VERSION "HNNBNNNYNNNNNNNNNNNNNNNNNNNNNNNNNNNNNNNNNN/4/%%%/4/'%**4NNN///"

NS_ :

BS_:

BU_: AWC BAP_Tester BMC_MLBevo BMS_MV BMS_NV CBC DCDC_800V_PAG DCDC_HV DCDC_HV_02 DCDC_IHEV FCU_MLBevo_FCEV Gateway Gateway_PAG Ladegeraet_2 Ladegeraet_Konzern LE1 LE2 LE_MLBevo Sub_Gateway TME

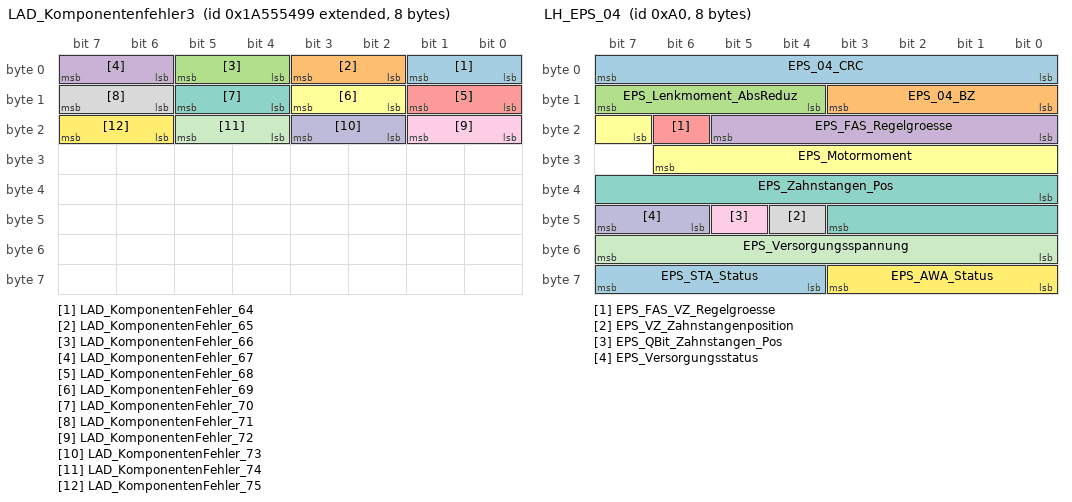
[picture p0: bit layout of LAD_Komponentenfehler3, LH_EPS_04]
BO_ 2589283481 LAD_Komponentenfehler3: 8 Ladegeraet_Konzern
 SG_ LAD_KomponentenFehler_64 : 0|2@1+ (1.0,0.0) [0.0|3] ""  BMC_MLBevo
 SG_ LAD_KomponentenFehler_65 : 2|2@1+ (1.0,0.0) [0.0|3] ""  BMC_MLBevo
 SG_ LAD_KomponentenFehler_66 : 4|2@1+ (1.0,0.0) [0.0|3] ""  BMC_MLBevo
 SG_ LAD_KomponentenFehler_67 : 6|2@1+ (1.0,0.0) [0.0|3] ""  BMC_MLBevo
 SG_ LAD_KomponentenFehler_68 : 8|2@1+ (1.0,0.0) [0.0|3] ""  BMC_MLBevo
 SG_ LAD_KomponentenFehler_69 : 10|2@1+ (1.0,0.0) [0.0|3] ""  BMC_MLBevo
 SG_ LAD_KomponentenFehler_70 : 12|2@1+ (1.0,0.0) [0.0|3] ""  BMC_MLBevo
 SG_ LAD_KomponentenFehler_71 : 14|2@1+ (1.0,0.0) [0.0|3] ""  BMC_MLBevo
 SG_ LAD_KomponentenFehler_72 : 16|2@1+ (1.0,0.0) [0.0|3] ""  BMC_MLBevo
 SG_ LAD_KomponentenFehler_73 : 18|2@1+ (1.0,0.0) [0.0|3] ""  BMC_MLBevo
 SG_ LAD_KomponentenFehler_74 : 20|2@1+ (1.0,0.0) [0.0|3] ""  BMC_MLBevo
 SG_ LAD_KomponentenFehler_75 : 22|2@1+ (1.0,0.0) [0.0|3] ""  BMC_MLBevo

BO_ 160 LH_EPS_04: 8 Gateway
 SG_ EPS_04_CRC : 0|8@1+ (1,0) [0|255] ""  Vector__XXX
 SG_ EPS_04_BZ : 8|4@1+ (1,0) [0|15] ""  Vector__XXX
 SG_ EPS_Lenkmoment_AbsReduz : 12|4@1+ (0.62,0.61) [0.61|8.05] "Unit_NewtoMeter"  Vector__XXX
 SG_ EPS_FAS_Regelgroesse : 16|6@1+ (2,0) [0|100] "Unit_PerCent"  Vector__XXX
 SG_ EPS_FAS_VZ_Regelgroesse : 22|1@1+ (1.0,0.0) [0.0|1] ""  Vector__XXX
 SG_ EPS_Motormoment : 23|8@1+ (0.2,-16.2) [-16.0|16.0] "Unit_NewtoMeter"  Vector__XXX
 SG_ EPS_Zahnstangen_Pos : 32|12@1+ (0.02,0) [0.00|81.86] "Unit_MilliMeter"  Vector__XXX
 SG_ EPS_VZ_Zahnstangenposition : 44|1@1+ (1.0,0.0) [0.0|1] ""  Vector__XXX
 SG_ EPS_QBit_Zahnstangen_Pos : 45|1@1+ (1.0,0.0) [0.0|1] ""  Vector__XXX
 SG_ EPS_Versorgungsstatus : 46|2@1+ (1.0,0.0) [0.0|3] ""  Vector__XXX
 SG_ EPS_Versorgungsspannung : 48|8@1+ (0.05,5.05) [5.05|17.70] "Unit_Volt"  Vector__XXX
 SG_ EPS_AWA_Status : 56|4@1+ (1.0,0.0) [0.0|15] ""  Vector__XXX
 SG_ EPS_STA_Status : 60|4@1+ (1.0,0.0) [0.0|15] ""  Vector__XXX

BO_ 1600 Motor_07: 8 Gateway
 SG_ MO_QBit_Ansaugluft_Temp : 0|1@1+ (1.0,0.0) [0.0|1] ""  Vector__XXX
 SG_ MO_QBit_Oel_Temp : 1|1@1+ (1.0,0.0) [0.0|1] ""  Vector__XXX
 SG_ MO_QBit_Kuehlmittel_Temp : 2|1@1+ (1.0,0.0) [0.0|1] ""  Vector__XXX
 SG_ MO_KL15_Abschaltempfehlung : 3|1@1+ (1.0,0.0) [0.0|1] ""  Vector__XXX
 SG_ MO_HYB_Fehler_HV_Netz : 4|1@1+ (1.0,0.0) [0.0|1] ""  Vector__XXX
 SG_ MO_aktives_Getriebeheizen : 5|1@1+ (1.0,0.0) [0.0|1] ""  Vector__XXX
 SG_ MO_Absperrventil_oeffnen : 6|2@1+ (1.0,0.0) [0.0|3] ""  TME
 SG_ MO_Ansaugluft_Temp : 8|8@1+ (0.75,-48) [-48.00|141.75] "Unit_DegreCelsi"  TME
 SG_ MO_Oel_Temp : 16|8@1+ (1,-60) [-60|192] "Unit_DegreCelsi"  TME
 SG_ MO_Kuehlmittel_Temp : 24|8@1+ (0.75,-48) [-48.00|141.75] "Unit_DegreCelsi"  TME
 SG_ MO_Hoeheninfo : 32|8@1+ (0.00781,0) [0.00000|1.98374] ""  TME
 SG_ MO_Kennfeldk : 40|1@1+ (1.0,0.0) [0.0|1] ""  TME
 SG_ MO_Versionsinfo_02 : 41|5@1+ (1.0,0.0) [0.0|31] ""  Vector__XXX
 SG_ MO_QBit_Hoeheninfo : 46|1@1+ (1.0,0.0) [0.0|1] ""  Vector__XXX
 SG_ MO_Getriebe_kuehlen : 47|1@1+ (1.0,0.0) [0.0|1] ""  Vector__XXX
 SG_ MO_Mom_Traegheit_02 : 48|5@1+ (0.01,0) [0.00|0.31] "Unit_KiloGramMeterSquar"  Vector__XXX
 SG_ MO_Heizungspumpenansteuerung : 53|4@1+ (10,0) [0|100] "Unit_PerCent"  TME
 SG_ MO_SpannungsAnf : 57|1@1+ (1.0,0.0) [0.0|1] ""  Vector__XXX
 SG_ MO_Nachlaufzeit_Heizungspumpe : 58|6@1+ (15,0) [0|945] "Unit_Secon"  TME

BO_ 1607 Motor_09: 8 Gateway
 SG_ MO_ITM_Kuehlmittel_Temp : 0|8@1+ (0.75,-48) [-45.75|143.25] "Unit_DegreCelsi"  TME
 SG_ MO_E85_Sensor : 8|4@1+ (10,0) [0|100] "Unit_PerCent"  Vector__XXX
 SG_ SCR_Anz_Motorstarts : 12|4@1+ (1.0,0.0) [0.0|15] ""  Vector__XXX
 SG_ SCR_Reichweite : 16|15@1+ (1,0) [0|32766] "Unit_KiloMeter"  Vector__XXX
 SG_ MO_Ethanol_Spuelhinweis : 31|1@1+ (1.0,0.0) [0.0|1] ""  Vector__XXX
 SG_ SCR_Warnstufe_1 : 32|1@1+ (1.0,0.0) [0.0|1] ""  Vector__XXX
 SG_ SCR_Warnstufe_2 : 33|1@1+ (1.0,0.0) [0.0|1] ""  Vector__XXX
 SG_ SCR_Text : 34|3@1+ (1.0,0.0) [0.0|7] ""  Vector__XXX
 SG_ SCR_Akustik : 37|2@1+ (1.0,0.0) [0.0|3] ""  Vector__XXX
 SG_ SCR_verbaut : 39|1@1+ (1.0,0.0) [0.0|1] ""  Vector__XXX
 SG_ MO_Kraftstofffilter_Wasser : 40|1@1+ (1.0,0.0) [0.0|1] ""  Vector__XXX
 SG_ SCR_Systemfehler : 41|1@1+ (1.0,0.0) [0.0|1] ""  Vector__XXX
 SG_ SCR_Inducement_Strategie : 42|2@1+ (1.0,0.0) [0.0|3] ""  Vector__XXX
 SG_ MO_CO2_Faktor : 44|12@1+ (1,0) [1|4094] "Unit_GramPerLiter"  Vector__XXX
 SG_ MO_MKB_MUX M  : 56|2@1+ (1.0,0.0) [0.0|3] ""  Vector__XXX
 SG_ MO_MKB_01 m0  : 59|5@1+ (1.0,0.0) [0.0|31] ""  Vector__XXX
 SG_ MO_MKB_02 m1  : 59|5@1+ (1.0,0.0) [0.0|31] ""  Vector__XXX
 SG_ MO_MKB_03 m2  : 59|5@1+ (1.0,0.0) [0.0|31] ""  Vector__XXX
 SG_ MO_MKB_04 m3  : 59|5@1+ (1.0,0.0) [0.0|31] ""  Vector__XXX

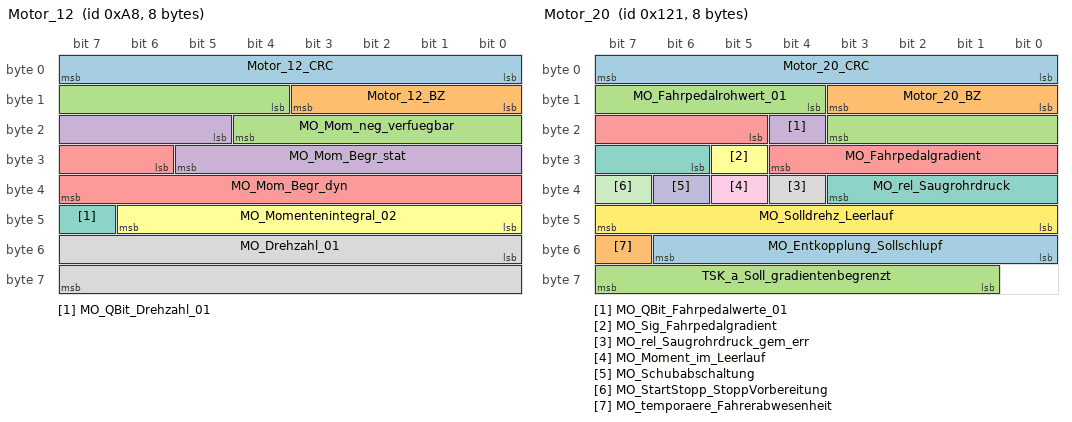
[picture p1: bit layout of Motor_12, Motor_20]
BO_ 168 Motor_12: 8 Gateway
 SG_ Motor_12_CRC : 0|8@1+ (1,0) [0|255] ""  Sub_Gateway
 SG_ Motor_12_BZ : 8|4@1+ (1,0) [0|15] ""  Sub_Gateway
 SG_ MO_Mom_neg_verfuegbar : 12|9@1+ (1,-509) [-509|0] ""  Sub_Gateway
 SG_ MO_Mom_Begr_stat : 21|9@1+ (1,0) [0|509] ""  Sub_Gateway
 SG_ MO_Mom_Begr_dyn : 30|10@1+ (1,-509) [-509|509] ""  Sub_Gateway
 SG_ MO_Momentenintegral_02 : 40|7@1+ (1,0) [0|100] "Unit_PerCent"  Sub_Gateway
 SG_ MO_QBit_Drehzahl_01 : 47|1@1+ (1.0,0.0) [0.0|1] ""  Sub_Gateway
 SG_ MO_Drehzahl_01 : 48|16@1+ (0.25,0) [0.00|16383.00] "Unit_MinutInver"  BMC_MLBevo,CBC,DCDC_800V_PAG,DCDC_HV,Ladegeraet_2,Ladegeraet_Konzern,Sub_Gateway,TME

BO_ 958 Motor_14: 8 Gateway
 SG_ Motor_14_CRC : 0|8@1+ (1,0) [0|255] ""  FCU_MLBevo_FCEV,Sub_Gateway
 SG_ Motor_14_BZ : 8|4@1+ (1,0) [0|15] ""  FCU_MLBevo_FCEV,Sub_Gateway
 SG_ MO_StartStopp_Status : 12|2@1+ (1.0,0.0) [0.0|3] ""  Sub_Gateway,TME
 SG_ MO_StartStopp_Wiederstart : 14|1@1+ (1.0,0.0) [0.0|1] ""  BMS_NV,Sub_Gateway,TME
 SG_ MO_StartStopp_Motorstopp : 15|1@1+ (1.0,0.0) [0.0|1] ""  BMS_NV,Sub_Gateway,TME
 SG_ MO_Freig_Reku : 16|2@1+ (1.0,0.0) [0.0|3] ""  Sub_Gateway
 SG_ MO_Kl_75 : 18|1@1+ (1.0,0.0) [0.0|1] ""  Sub_Gateway,TME
 SG_ MO_Kl_50 : 19|1@1+ (1.0,0.0) [0.0|1] ""  DCDC_IHEV,Ladegeraet_Konzern,Sub_Gateway
 SG_ MO_Gangposition : 20|4@1+ (1.0,0.0) [0.0|15] ""  Sub_Gateway,TME
 SG_ MO_StartStopp_Fahrerwunsch : 24|2@1+ (1.0,0.0) [0.0|3] ""  Sub_Gateway,TME
 SG_ MO_HYB_Fahrbereitschaft : 26|1@1+ (1.0,0.0) [0.0|1] ""  BMS_NV,FCU_MLBevo_FCEV,Ladegeraet_Konzern,Sub_Gateway,TME
 SG_ MO_Ext_E_Fahrt_aktiv : 27|1@1+ (1.0,0.0) [0.0|1] ""  Sub_Gateway,TME
 SG_ MO_Fahrer_bremst : 28|1@1+ (1.0,0.0) [0.0|1] ""  Sub_Gateway
 SG_ MO_QBit_Fahrer_bremst : 29|1@1+ (1.0,0.0) [0.0|1] ""  Sub_Gateway
 SG_ MO_BLS : 30|1@1+ (1.0,0.0) [0.0|1] ""  Sub_Gateway
 SG_ MO_Konsistenz_Bremsped : 31|1@1+ (1.0,0.0) [0.0|1] ""  Sub_Gateway
 SG_ MO_KomFehler_ESP : 32|1@1+ (1.0,0.0) [0.0|1] ""  Sub_Gateway
 SG_ MO_Klima_Eingr : 33|2@1+ (1.0,0.0) [0.0|3] ""  Sub_Gateway,TME
 SG_ MO_Aussp_Anlass : 35|1@1+ (1.0,0.0) [0.0|1] ""  Sub_Gateway
 SG_ MO_Freig_Anlass : 36|1@1+ (1.0,0.0) [0.0|1] ""  Sub_Gateway
 SG_ MO_Kuppl_schalter : 37|1@1+ (1.0,0.0) [0.0|1] ""  Sub_Gateway
 SG_ MO_Interlock : 38|1@1+ (1.0,0.0) [0.0|1] ""  Sub_Gateway
 SG_ MO_Motor_laeuft : 39|1@1+ (1.0,0.0) [0.0|1] ""  Sub_Gateway,TME
 SG_ MO_Kickdown : 40|1@1+ (1.0,0.0) [0.0|1] ""  Sub_Gateway,TME
 SG_ MO_QBit_KL_75 : 41|1@1+ (1.0,0.0) [0.0|1] ""  Sub_Gateway
 SG_ MO_EKlKomLeiRed : 42|2@1+ (1.0,0.0) [0.0|3] ""  Sub_Gateway
 SG_ MO_Handshake_STH : 44|1@1+ (1.0,0.0) [0.0|1] ""  Sub_Gateway
 SG_ MO_BKV_Unterdruckwarnung : 45|1@1+ (1.0,0.0) [0.0|1] ""  Sub_Gateway
 SG_ MO_Freigabe_Segeln : 46|1@1+ (1.0,0.0) [0.0|1] ""  Sub_Gateway
 SG_ MO_PTC_Status : 47|3@1+ (1.0,0.0) [0.0|7] ""  Sub_Gateway
 SG_ MO_QBit_Gangposition : 50|1@1+ (1.0,0.0) [0.0|1] ""  Sub_Gateway
 SG_ MO_Signalquelle_Gangposition : 51|1@1+ (1.0,0.0) [0.0|1] ""  Sub_Gateway
 SG_ MO_Remotestart_Betrieb : 52|1@1+ (1.0,0.0) [0.0|1] ""  Sub_Gateway
 SG_ MO_Remotestart_moeglich : 53|1@1+ (1.0,0.0) [0.0|1] ""  Sub_Gateway
 SG_ MO_Text_Geschw_red : 54|1@1+ (1.0,0.0) [0.0|1] ""  Sub_Gateway
 SG_ MO_FMAus_aktiv : 55|1@1+ (1.0,0.0) [0.0|1] ""  BMS_NV,Sub_Gateway
 SG_ MO_FMAus_Startvariante : 56|2@1+ (1.0,0.0) [0.0|3] ""  Sub_Gateway
 SG_ MO_BMS_NV_Anf_stuetzen : 58|1@1+ (1.0,0.0) [0.0|1] ""  Sub_Gateway
 SG_ MO_Zylinderabschaltung : 59|2@1+ (1.0,0.0) [0.0|3] ""  Sub_Gateway
 SG_ MO_HYB_VM_aktiv : 61|1@1+ (1.0,0.0) [0.0|1] ""  Sub_Gateway
 SG_ MO_StartVorauss_erfuellt : 62|2@1+ (1.0,0.0) [0.0|3] ""  Ladegeraet_Konzern,Sub_Gateway

BO_ 812 Motor_17: 8 Gateway
 SG_ MO_Sperrung_FahrPr_BZS : 0|8@1+ (1.0,0.0) [0.0|255] ""  Vector__XXX
 SG_ MO_Rampenzeit_Generator_Anf : 8|4@1+ (1.0,0.0) [0.0|15] ""  Vector__XXX
 SG_ MO_Prio_MAX_Wunschdrehzahl : 12|1@1+ (1.0,0.0) [0.0|1] ""  Vector__XXX
 SG_ MO_Prio_MIN_Wunschdrehzahl : 13|1@1+ (1.0,0.0) [0.0|1] ""  Vector__XXX
 SG_ MO_Luftpfad_aktiv : 14|1@1+ (1.0,0.0) [0.0|1] ""  Vector__XXX
 SG_ MO_v_Begrenz_Aktivierbar : 15|1@1+ (1.0,0.0) [0.0|1] ""  Vector__XXX
 SG_ MO_Drehzahlbeeinflussung : 16|8@1+ (0.39,0) [0.00|99.45] "Unit_PerCent"  Vector__XXX
 SG_ MO_MIN_Wunschdrehzahl : 24|8@1+ (25,0) [0|6350] "Unit_MinutInver"  Vector__XXX
 SG_ MO_MAX_Wunschdrehzahl : 32|9@1+ (25,0) [0|12750] "Unit_MinutInver"  Vector__XXX
 SG_ MO_Charisma_FahrPr : 41|4@1+ (1.0,0.0) [0.0|15] ""  TME
 SG_ MO_Charisma_Status : 45|2@1+ (1.0,0.0) [0.0|3] ""  Vector__XXX
 SG_ MO_StSt_Charisma_FahrPr : 47|4@1+ (1.0,0.0) [0.0|15] ""  Vector__XXX
 SG_ MO_StSt_Charisma_Status : 51|2@1+ (1.0,0.0) [0.0|3] ""  Vector__XXX
 SG_ MO_BZS_Charisma_FahrPr : 53|4@1+ (1.0,0.0) [0.0|15] ""  TME
 SG_ MO_BZS_Charisma_Status : 57|2@1+ (1.0,0.0) [0.0|3] ""  Vector__XXX
 SG_ MO_NGS_Position : 59|1@1+ (1.0,0.0) [0.0|1] ""  Vector__XXX
 SG_ MO_NGS_Status : 60|2@1+ (1.0,0.0) [0.0|3] ""  Vector__XXX
 SG_ MO_v_Begrenzung_Niveau : 62|2@1+ (1.0,0.0) [0.0|3] ""  Vector__XXX

BO_ 1648 Motor_18: 8 Gateway
 SG_ MO_max_Ladedruck : 0|6@1+ (0.1,0) [0.0|6.3] "Unit_Bar"  Sub_Gateway
 SG_ MO_ANC_Kennfeld_Anf : 6|2@1+ (1.0,0.0) [0.0|3] ""  Sub_Gateway
 SG_ MO_Bremslicht_Reku : 8|1@1+ (1.0,0.0) [0.0|1] ""  Sub_Gateway
 SG_ MO_StartStopp_PopUp : 9|2@1+ (1.0,0.0) [0.0|3] ""  Sub_Gateway
 SG_ MO1_Sperr_Info_WFS : 11|1@1+ (1.0,0.0) [0.0|1] ""  Sub_Gateway
 SG_ MO1_Freigabe_Info_WFS : 12|1@1+ (1.0,0.0) [0.0|1] ""  Sub_Gateway
 SG_ MO_EPCL : 13|3@1+ (1.0,0.0) [0.0|7] ""  Sub_Gateway
 SG_ MO_Zylabsch_Texte_02 : 16|4@1+ (1.0,0.0) [0.0|15] ""  Sub_Gateway
 SG_ MO_Fahrzeugtyp : 20|3@1+ (1.0,0.0) [0.0|7] ""  BMS_NV,Sub_Gateway
 SG_ MO_NMAX_Schaltanzeige : 23|9@1+ (25,0) [0|12775] "Unit_MinutInver"  Sub_Gateway
 SG_ MO_Abstellzeit : 32|8@1+ (8,0) [0|2024] "Unit_Minut"  BMS_MV,BMS_NV,Sub_Gateway,TME
 SG_ MO_Abstellzeit_Status : 40|2@1+ (1.0,0.0) [0.0|3] ""  BMS_MV,BMS_NV,Sub_Gateway,TME
 SG_ MO1_Freigabe_Verfallsinfo_WFS : 42|1@1+ (1.0,0.0) [0.0|1] ""  Sub_Gateway
 SG_ MO_Hybrid_StartStopp_LED : 43|2@1+ (1.0,0.0) [0.0|3] ""  Sub_Gateway
 SG_ MO_Fehler_Zylabsch : 45|2@1+ (1.0,0.0) [0.0|3] ""  Sub_Gateway
 SG_ MO_Anzahl_Abgesch_Zyl : 47|3@1+ (1.0,0.0) [0.0|7] ""  Sub_Gateway
 SG_ MO_Zylabsch_Texte : 50|2@1+ (1.0,0.0) [0.0|3] ""  Sub_Gateway
 SG_ MO_Ethanol_BS_Texte : 52|3@1+ (1.0,0.0) [0.0|7] ""  Sub_Gateway
 SG_ MO_Drehzahl_Warnung : 55|1@1+ (1.0,0.0) [0.0|1] ""  Sub_Gateway
 SG_ MO_obere_Drehzahlgrenze : 56|8@1+ (50,0) [50|12750] "Unit_MinutInver"  Sub_Gateway

BO_ 289 Motor_20: 8 Gateway
 SG_ Motor_20_CRC : 0|8@1+ (1,0) [0|255] ""  Sub_Gateway
 SG_ Motor_20_BZ : 8|4@1+ (1,0) [0|15] ""  Sub_Gateway
 SG_ MO_Fahrpedalrohwert_01 : 12|8@1+ (0.4,0) [0.0|101.6] "Unit_PerCent"  Sub_Gateway
 SG_ MO_QBit_Fahrpedalwerte_01 : 20|1@1+ (1.0,0.0) [0.0|1] ""  Sub_Gateway
 SG_ MO_Fahrpedalgradient : 21|8@1+ (25,0) [0|6350] "Unit_PerCentPerSecon"  Sub_Gateway
 SG_ MO_Sig_Fahrpedalgradient : 29|1@1+ (1.0,0.0) [0.0|1] ""  Sub_Gateway
 SG_ MO_rel_Saugrohrdruck : 30|6@1+ (18,0) [0|1116] "Unit_MilliBar"  Sub_Gateway
 SG_ MO_rel_Saugrohrdruck_gem_err : 36|1@1+ (1.0,0.0) [0.0|1] ""  Sub_Gateway
 SG_ MO_Moment_im_Leerlauf : 37|1@1+ (1.0,0.0) [0.0|1] ""  Sub_Gateway
 SG_ MO_Schubabschaltung : 38|1@1+ (1.0,0.0) [0.0|1] ""  Sub_Gateway
 SG_ MO_StartStopp_StoppVorbereitung : 39|1@1+ (1.0,0.0) [0.0|1] ""  Sub_Gateway
 SG_ MO_Solldrehz_Leerlauf : 40|8@1+ (10,0) [0|2540] "Unit_MinutInver"  Sub_Gateway
 SG_ MO_Entkopplung_Sollschlupf : 48|7@1+ (20,0) [0|2480] "Unit_MinutInver"  Sub_Gateway
 SG_ MO_temporaere_Fahrerabwesenheit : 55|1@1+ (1.0,0.0) [0.0|1] ""  Sub_Gateway
 SG_ TSK_a_Soll_gradientenbegrenzt : 57|7@1+ (0.1,-7.2) [-7.2|5.4] "Unit_MeterPerSeconSquar"  Sub_Gateway

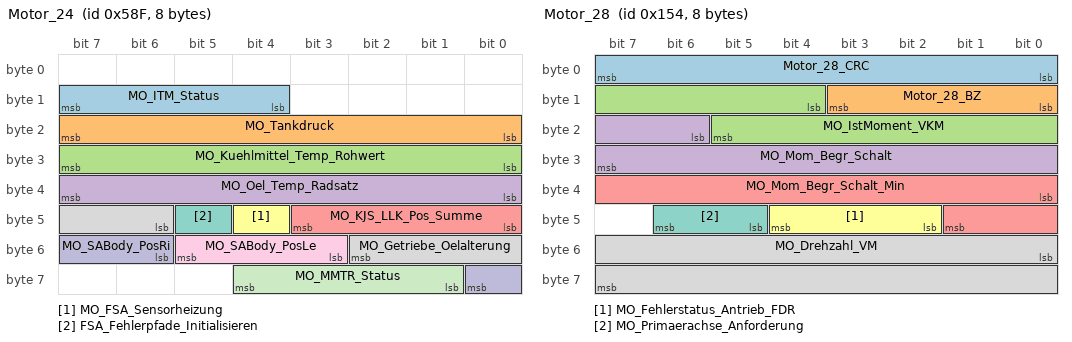
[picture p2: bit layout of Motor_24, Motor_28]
BO_ 1423 Motor_24: 8 Gateway
 SG_ MO_ITM_Status : 12|4@1+ (1.0,0.0) [0.0|15] ""  TME
 SG_ MO_Tankdruck : 16|8@1+ (2,-250) [-250|256] "Unit_MilliBar"  Vector__XXX
 SG_ MO_Kuehlmittel_Temp_Rohwert : 24|8@1+ (0.75,-48) [-48.00|141.75] "Unit_DegreCelsi"  TME
 SG_ MO_Oel_Temp_Radsatz : 32|8@1+ (1,-60) [-60|193] "Unit_DegreCelsi"  Vector__XXX
 SG_ MO_KJS_LLK_Pos_Summe : 40|4@1+ (10,0) [0|100] "Unit_PerCent"  Vector__XXX
 SG_ MO_FSA_Sensorheizung : 44|1@1+ (1.0,0.0) [0.0|1] ""  Vector__XXX
 SG_ FSA_Fehlerpfade_Initialisieren : 45|1@1+ (1.0,0.0) [0.0|1] ""  Vector__XXX
 SG_ MO_Getriebe_Oelalterung : 46|5@1+ (5,0) [0|100] "Unit_PerCent"  Vector__XXX
 SG_ MO_SABody_PosLe : 51|3@1+ (20,-20) [0|100] "Unit_PerCent"  Vector__XXX
 SG_ MO_SABody_PosRi : 54|3@1+ (20,-20) [0|100] "Unit_PerCent"  Vector__XXX
 SG_ MO_MMTR_Status : 57|4@1+ (1.0,0.0) [0.0|15] ""  LE1,LE2

BO_ 967 Motor_26: 8 Gateway
 SG_ MO_Kuehlerluefter_MUX M  : 0|1@1+ (1.0,0.0) [0.0|1] ""  TME
 SG_ MO_Kuehlerluefter_1 m0  : 1|7@1+ (1,0) [0|100] "Unit_PerCent"  TME
 SG_ MO_Kuehlerluefter_2 m1  : 1|7@1+ (1,0) [0|100] "Unit_PerCent"  TME
 SG_ MO_EFLEX_Lampe : 8|2@1+ (1.0,0.0) [0.0|3] ""  Vector__XXX
 SG_ MO_KJS_nicht_bereit : 10|1@1+ (1.0,0.0) [0.0|1] ""  Vector__XXX
 SG_ MO_ITM_Warnung_Pumpe : 11|1@1+ (1.0,0.0) [0.0|1] ""  Vector__XXX
 SG_ WIV_Anzeige_aktiv : 12|1@1+ (1.0,0.0) [0.0|1] ""  Vector__XXX
 SG_ WIV_Oelmin_Warn : 13|1@1+ (1.0,0.0) [0.0|1] ""  Vector__XXX
 SG_ WIV_Sensorfehler : 14|1@1+ (1.0,0.0) [0.0|1] ""  Vector__XXX
 SG_ WIV_Schieflage : 15|1@1+ (1.0,0.0) [0.0|1] ""  Vector__XXX
 SG_ WIV_Oelstand : 16|4@1+ (12.5,0) [0.0|100.0] "Unit_PerCent"  Vector__XXX
 SG_ MO_Zustand_HWP : 20|2@1+ (1.0,0.0) [0.0|3] ""  TME
 SG_ OLEV_Systemstoerung : 22|1@1+ (1.0,0.0) [0.0|1] ""  Vector__XXX
 SG_ MO_Oelwarnung_max : 23|1@1+ (1.0,0.0) [0.0|1] ""  Vector__XXX
 SG_ WIV_Oelsystem_aktiv : 24|1@1+ (1.0,0.0) [0.0|1] ""  Vector__XXX
 SG_ WIV_nicht_betriebswarm : 25|1@1+ (1.0,0.0) [0.0|1] ""  Vector__XXX
 SG_ WIV_Ueberfuell_Warn : 26|1@1+ (1.0,0.0) [0.0|1] ""  Vector__XXX
 SG_ WIV_laufender_Motor : 27|1@1+ (1.0,0.0) [0.0|1] ""  Vector__XXX
 SG_ MO_E_Warnungen : 28|4@1+ (1.0,0.0) [0.0|15] ""  Vector__XXX
 SG_ MO_Text_Motorstart : 32|4@1+ (1.0,0.0) [0.0|15] ""  Vector__XXX
 SG_ MO_E_Texte : 36|4@1+ (1.0,0.0) [0.0|15] ""  Vector__XXX
 SG_ WIV_Oeldyn_avl : 40|1@1+ (1.0,0.0) [0.0|1] ""  Vector__XXX
 SG_ MO_Text_Partikelfil_Reg : 41|1@1+ (1,0) [0|1] ""  Vector__XXX
 SG_ OLEV_Oelstand_nicht_vorhanden : 42|1@1+ (1.0,0.0) [0.0|1] ""  Vector__XXX
 SG_ WIV_Oelmenge : 43|5@1+ (125,0) [0|3875] "Unit_MilliLiter"  Vector__XXX
 SG_ MO_Systemlampe : 48|1@1+ (1.0,0.0) [0.0|1] ""  Vector__XXX
 SG_ MO_OBD2_Lampe : 49|1@1+ (1.0,0.0) [0.0|1] ""  Vector__XXX
 SG_ MO_Heissleuchte : 50|1@1+ (1.0,0.0) [0.0|1] ""  TME
 SG_ MO_Partikel_Lampe : 51|1@1+ (1.0,0.0) [0.0|1] ""  Vector__XXX
 SG_ MO_RedFahrleistung_Lampe : 52|1@1+ (1.0,0.0) [0.0|1] ""  Vector__XXX
 SG_ WIV_Oelstand_nicht_vorhanden : 53|1@1+ (1.0,0.0) [0.0|1] ""  Vector__XXX
 SG_ WIV_nachfuellanzeige_ein : 54|1@1+ (1.0,0.0) [0.0|1] ""  Vector__XXX
 SG_ WIV_Ueberfuell_deaktiv : 55|1@1+ (1.0,0.0) [0.0|1] ""  Vector__XXX
 SG_ WIV_Unterfuell_Warn : 56|1@1+ (1.0,0.0) [0.0|1] ""  Vector__XXX
 SG_ MO_Tankdeckel_Lampe : 57|1@1+ (1.0,0.0) [0.0|1] ""  Vector__XXX
 SG_ MO_Text_Tankdeckelwarn : 58|1@1+ (1.0,0.0) [0.0|1] ""  Vector__XXX
 SG_ MO_Vorglueh_Lampe : 59|1@1+ (1.0,0.0) [0.0|1] ""  Vector__XXX
 SG_ WIV_Oeldr_Warn_Motor : 60|1@1+ (1.0,0.0) [0.0|1] ""  Vector__XXX
 SG_ MO_E_Mode : 61|3@1+ (1.0,0.0) [0.0|7] ""  Vector__XXX

BO_ 340 Motor_28: 8 Gateway
 SG_ Motor_28_CRC : 0|8@1+ (1,0) [0|255] ""  Sub_Gateway
 SG_ Motor_28_BZ : 8|4@1+ (1,0) [0|15] ""  Sub_Gateway
 SG_ MO_IstMoment_VKM : 12|10@1+ (1,-509) [-509|509] ""  Sub_Gateway
 SG_ MO_Mom_Begr_Schalt : 22|10@1+ (1,-509) [-509|509] ""  Sub_Gateway
 SG_ MO_Mom_Begr_Schalt_Min : 32|10@1+ (1,-509) [-509|509] ""  Sub_Gateway
 SG_ MO_Fehlerstatus_Antrieb_FDR : 42|3@1+ (1.0,0.0) [0.0|7] ""  Sub_Gateway
 SG_ MO_Primaerachse_Anforderung : 45|2@1+ (1.0,0.0) [0.0|3] ""  Sub_Gateway
 SG_ MO_Drehzahl_VM : 48|16@1+ (0.25,0) [0.00|16383.00] "Unit_MinutInver"  BMC_MLBevo,BMS_MV,BMS_NV,DCDC_HV,DCDC_IHEV,Sub_Gateway,TME

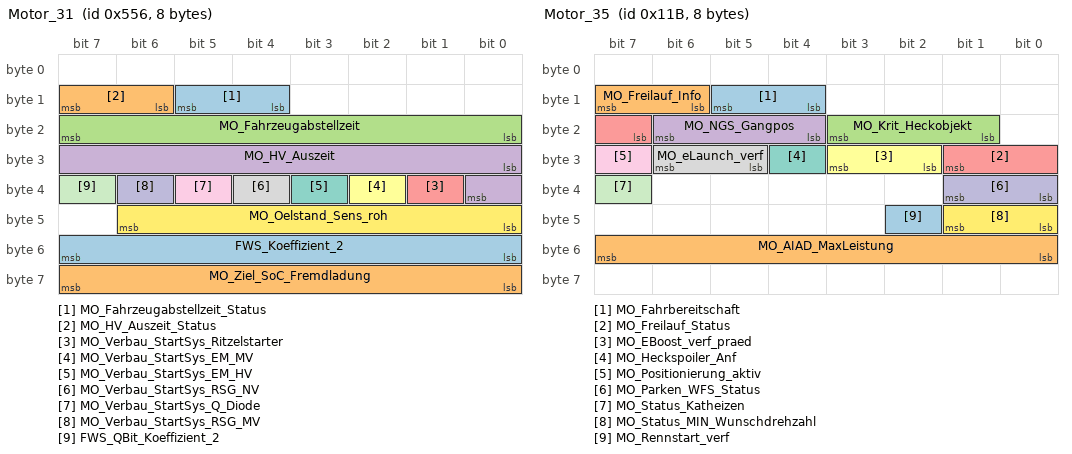
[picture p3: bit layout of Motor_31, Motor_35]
BO_ 1366 Motor_31: 8 Gateway
 SG_ MO_Fahrzeugabstellzeit_Status : 12|2@1+ (1.0,0.0) [0.0|3] ""  BMC_MLBevo,TME
 SG_ MO_HV_Auszeit_Status : 14|2@1+ (1.0,0.0) [0.0|3] ""  BMC_MLBevo,DCDC_HV,Ladegeraet_Konzern,TME
 SG_ MO_Fahrzeugabstellzeit : 16|8@1+ (8,0) [0|2024] "Unit_Minut"  BMC_MLBevo,TME
 SG_ MO_HV_Auszeit : 24|9@1+ (4,0) [0|2036] "Unit_Minut"  BMC_MLBevo,DCDC_HV,Ladegeraet_Konzern,TME
 SG_ MO_Verbau_StartSys_Ritzelstarter : 33|1@1+ (1.0,0.0) [0.0|1] ""  BMS_NV
 SG_ MO_Verbau_StartSys_EM_MV : 34|1@1+ (1.0,0.0) [0.0|1] ""  BMS_NV
 SG_ MO_Verbau_StartSys_EM_HV : 35|1@1+ (1.0,0.0) [0.0|1] ""  BMS_NV
 SG_ MO_Verbau_StartSys_RSG_NV : 36|1@1+ (1.0,0.0) [0.0|1] ""  BMS_NV
 SG_ MO_Verbau_StartSys_Q_Diode : 37|1@1+ (1.0,0.0) [0.0|1] ""  BMS_NV
 SG_ MO_Verbau_StartSys_RSG_MV : 38|1@1+ (1.0,0.0) [0.0|1] ""  BMS_NV
 SG_ FWS_QBit_Koeffizient_2 : 39|1@1+ (1.0,0.0) [0.0|1] ""  Vector__XXX
 SG_ MO_Oelstand_Sens_roh : 40|7@1+ (1,0) [0|127] "Unit_MilliMeter"  Vector__XXX
 SG_ FWS_Koeffizient_2 : 48|8@1+ (0.002,0) [0.000|0.506] "Unit_NewtonPer_Kmh_Squar"  Vector__XXX
 SG_ MO_Ziel_SoC_Fremdladung : 56|8@1+ (0.4,0) [0.0|100.0] "Unit_PerCent"  Vector__XXX

BO_ 283 Motor_35: 8 Gateway
 SG_ MO_Fahrbereitschaft : 12|2@1+ (1.0,0.0) [0.0|3] ""  Vector__XXX
 SG_ MO_Freilauf_Info : 14|2@1+ (1.0,0.0) [0.0|3] ""  Vector__XXX
 SG_ MO_Krit_Heckobjekt : 17|3@1+ (1.0,0.0) [0.0|7] ""  Vector__XXX
 SG_ MO_NGS_Gangpos : 20|3@1+ (1.0,0.0) [0.0|7] ""  Vector__XXX
 SG_ MO_Freilauf_Status : 23|3@1+ (1.0,0.0) [0.0|7] ""  BMS_NV
 SG_ MO_EBoost_verf_praed : 26|2@1+ (1.0,0.0) [0.0|3] ""  Vector__XXX
 SG_ MO_Heckspoiler_Anf : 28|1@1+ (1.0,0.0) [0.0|1] ""  Vector__XXX
 SG_ MO_eLaunch_verf : 29|2@1+ (1.0,0.0) [0.0|3] ""  Vector__XXX
 SG_ MO_Positionierung_aktiv : 31|1@1+ (1.0,0.0) [0.0|1] ""  Vector__XXX
 SG_ MO_Parken_WFS_Status : 32|2@1+ (1.0,0.0) [0.0|3] ""  Vector__XXX
 SG_ MO_Status_Katheizen : 39|1@1+ (1.0,0.0) [0.0|1] ""  Vector__XXX
 SG_ MO_Status_MIN_Wunschdrehzahl : 40|2@1+ (1.0,0.0) [0.0|3] ""  Vector__XXX
 SG_ MO_Rennstart_verf : 42|1@1+ (1.0,0.0) [0.0|1] ""  Vector__XXX
 SG_ MO_AIAD_MaxLeistung : 48|8@1+ (100,0) [0|25400] "Unit_Watt"  Vector__XXX

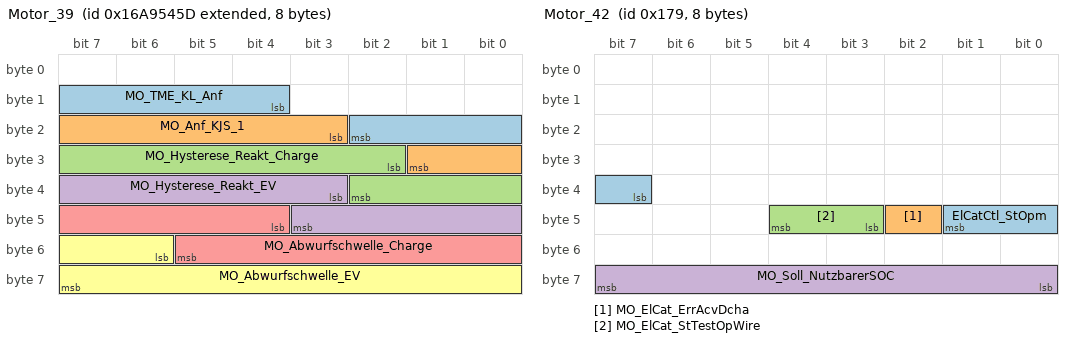
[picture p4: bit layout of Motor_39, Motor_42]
BO_ 2527679581 Motor_39: 8 Gateway
 SG_ MO_TME_KL_Anf : 12|7@1+ (1,0) [0|100] "Unit_PerCent"  TME
 SG_ MO_Anf_KJS_1 : 19|7@1+ (1,0) [0|100] "Unit_PerCent"  TME
 SG_ MO_Hysterese_Reakt_Charge : 26|9@1+ (4,0) [0|2036] "Unit_WattHour"  BMC_MLBevo
 SG_ MO_Hysterese_Reakt_EV : 35|9@1+ (4,0) [0|2036] "Unit_WattHour"  BMC_MLBevo
 SG_ MO_Abwurfschwelle_Charge : 44|10@1+ (4,0) [0|4084] "Unit_WattHour"  BMC_MLBevo
 SG_ MO_Abwurfschwelle_EV : 54|10@1+ (4,0) [0|4084] "Unit_WattHour"  BMC_MLBevo

BO_ 377 Motor_42: 8 Gateway
 SG_ ElCatCtl_StOpm : 39|3@1+ (1.0,0.0) [0.0|7] ""  Vector__XXX
 SG_ MO_ElCat_ErrAcvDcha : 42|1@1+ (1.0,0.0) [0.0|1] ""  Vector__XXX
 SG_ MO_ElCat_StTestOpWire : 43|2@1+ (1.0,0.0) [0.0|3] ""  Vector__XXX
 SG_ MO_Soll_NutzbarerSOC : 56|8@1+ (0.5,0) [0.0|100.0] "Unit_PerCent"  BMC_MLBevo

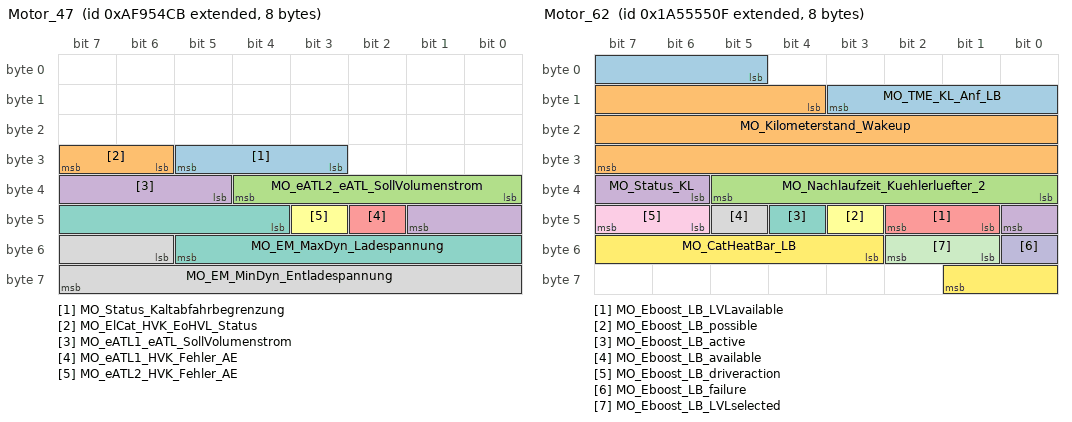
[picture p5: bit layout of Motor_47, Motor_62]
BO_ 2331595979 Motor_47: 8 Gateway
 SG_ MO_Status_Kaltabfahrbegrenzung : 27|3@1+ (1.0,0.0) [0.0|7] ""  Vector__XXX
 SG_ MO_ElCat_HVK_EoHVL_Status : 30|2@1+ (1.0,0.0) [0.0|3] ""  Vector__XXX
 SG_ MO_eATL2_eATL_SollVolumenstrom : 32|5@1+ (0.5,0) [0.0|14.5] "Unit_LiterPerMinut"  TME
 SG_ MO_eATL1_eATL_SollVolumenstrom : 37|5@1+ (0.5,0) [0.0|14.5] "Unit_LiterPerMinut"  TME
 SG_ MO_eATL1_HVK_Fehler_AE : 42|1@1+ (1.0,0.0) [0.0|1] ""  Vector__XXX
 SG_ MO_eATL2_HVK_Fehler_AE : 43|1@1+ (1.0,0.0) [0.0|1] ""  Vector__XXX
 SG_ MO_EM_MaxDyn_Ladespannung : 44|10@1+ (1,0) [0|1022] "Unit_Volt"  Vector__XXX
 SG_ MO_EM_MinDyn_Entladespannung : 54|10@1+ (1,0) [0|1022] "Unit_Volt"  Vector__XXX

BO_ 2589283599 Motor_62: 8 Gateway
 SG_ MO_TME_KL_Anf_LB : 5|7@1+ (1,0) [0|100] "Unit_PerCent"  TME
 SG_ MO_Kilometerstand_Wakeup : 12|20@1+ (1,0) [0|1048573] "Unit_KiloMeter"  Vector__XXX
 SG_ MO_Nachlaufzeit_Kuehlerluefter_2 : 32|6@1+ (15,0) [0|945] "Unit_Secon"  TME
 SG_ MO_Status_KL : 38|3@1+ (1.0,0.0) [0.0|7] ""  TME
 SG_ MO_Eboost_LB_LVLavailable : 41|2@1+ (1.0,0.0) [0.0|3] ""  Vector__XXX
 SG_ MO_Eboost_LB_possible : 43|1@1+ (1.0,0.0) [0.0|1] ""  Vector__XXX
 SG_ MO_Eboost_LB_active : 44|1@1+ (1.0,0.0) [0.0|1] ""  Vector__XXX
 SG_ MO_Eboost_LB_available : 45|1@1+ (1.0,0.0) [0.0|1] ""  Vector__XXX
 SG_ MO_Eboost_LB_driveraction : 46|2@1+ (1.0,0.0) [0.0|3] ""  Vector__XXX
 SG_ MO_Eboost_LB_failure : 48|1@1+ (1.0,0.0) [0.0|1] ""  Vector__XXX
 SG_ MO_Eboost_LB_LVLselected : 49|2@1+ (1.0,0.0) [0.0|3] ""  Vector__XXX
 SG_ MO_CatHeatBar_LB : 51|7@1+ (1,0) [0|100] "Unit_PerCent"  Vector__XXX

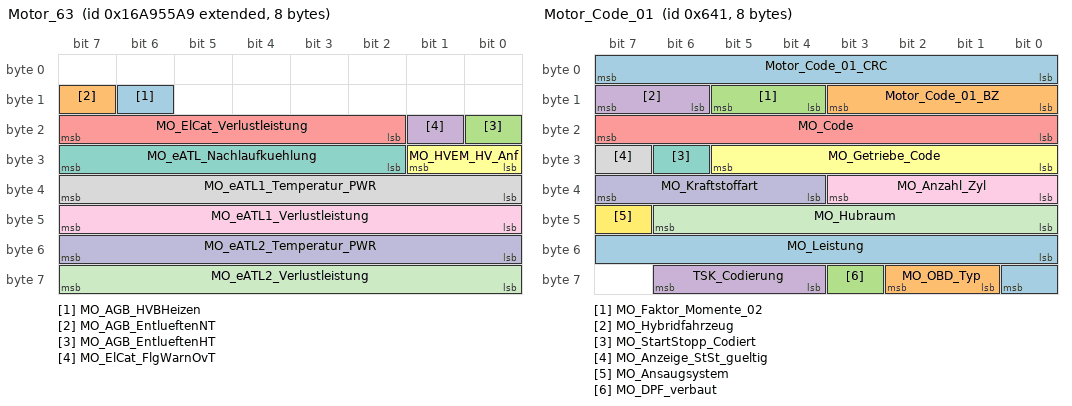
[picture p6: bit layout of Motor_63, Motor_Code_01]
BO_ 2527679913 Motor_63: 8 Gateway
 SG_ MO_AGB_HVBHeizen : 14|1@1+ (1.0,0.0) [0.0|1] ""  TME
 SG_ MO_AGB_EntlueftenNT : 15|1@1+ (1.0,0.0) [0.0|1] ""  TME
 SG_ MO_AGB_EntlueftenHT : 16|1@1+ (1.0,0.0) [0.0|1] ""  TME
 SG_ MO_ElCat_FlgWarnOvT : 17|1@1+ (1.0,0.0) [0.0|1] ""  TME
 SG_ MO_ElCat_Verlustleistung : 18|6@1+ (100,0) [0|6100] "Unit_Watt"  TME
 SG_ MO_HVEM_HV_Anf : 24|2@1+ (1.0,0.0) [0.0|3] ""  Vector__XXX
 SG_ MO_eATL_Nachlaufkuehlung : 26|6@1+ (107.43,0) [0.00|6553.23] "Unit_None"  TME
 SG_ MO_eATL1_Temperatur_PWR : 32|8@1+ (1,-40) [-40|213] "Unit_DegreCelsi"  TME
 SG_ MO_eATL1_Verlustleistung : 40|8@1+ (33,0) [0|8349] "Unit_Watt"  TME
 SG_ MO_eATL2_Temperatur_PWR : 48|8@1+ (1,-40) [-40|213] "Unit_DegreCelsi"  TME
 SG_ MO_eATL2_Verlustleistung : 56|8@1+ (33,0) [0|8349] "Unit_Watt"  TME

BO_ 1601 Motor_Code_01: 8 Gateway
 SG_ Motor_Code_01_CRC : 0|8@1+ (1,0) [0|255] ""  BMC_MLBevo,BMS_MV,BMS_NV,FCU_MLBevo_FCEV,TME
 SG_ Motor_Code_01_BZ : 8|4@1+ (1,0) [0|15] ""  BMC_MLBevo,BMS_MV,BMS_NV,FCU_MLBevo_FCEV,TME
 SG_ MO_Faktor_Momente_02 : 12|2@1+ (1,0) [1|3] "Unit_NewtoMeter"  FCU_MLBevo_FCEV
 SG_ MO_Hybridfahrzeug : 14|2@1+ (1.0,0.0) [0.0|3] ""  BMS_MV,BMS_NV,FCU_MLBevo_FCEV,TME
 SG_ MO_Code : 16|8@1+ (1,0) [0|255] ""  FCU_MLBevo_FCEV,TME
 SG_ MO_Getriebe_Code : 24|6@1+ (1.0,0.0) [0.0|63] ""  FCU_MLBevo_FCEV,TME
 SG_ MO_StartStopp_Codiert : 30|1@1+ (1.0,0.0) [0.0|1] ""  BMS_NV,FCU_MLBevo_FCEV
 SG_ MO_Anzeige_StSt_gueltig : 31|1@1+ (1.0,0.0) [0.0|1] ""  FCU_MLBevo_FCEV
 SG_ MO_Anzahl_Zyl : 32|4@1+ (1.0,0.0) [0.0|15] ""  FCU_MLBevo_FCEV
 SG_ MO_Kraftstoffart : 36|4@1+ (1.0,0.0) [0.0|15] ""  BMC_MLBevo,BMS_MV,FCU_MLBevo_FCEV,TME
 SG_ MO_Hubraum : 40|7@1+ (0.1,0) [0.0|12.7] "Unit_Liter"  BMC_MLBevo,BMS_MV,FCU_MLBevo_FCEV
 SG_ MO_Ansaugsystem : 47|1@1+ (1.0,0.0) [0.0|1] ""  FCU_MLBevo_FCEV
 SG_ MO_Leistung : 48|9@1+ (1,0) [0|511] "Unit_KiloWatt"  FCU_MLBevo_FCEV
 SG_ MO_OBD_Typ : 57|2@1+ (1.0,0.0) [0.0|3] ""  BMC_MLBevo,BMS_MV,DCDC_IHEV,FCU_MLBevo_FCEV,Ladegeraet_2,Ladegeraet_Konzern,TME
 SG_ MO_DPF_verbaut : 59|1@1+ (1.0,0.0) [0.0|1] ""  FCU_MLBevo_FCEV
 SG_ TSK_Codierung : 60|3@1+ (1.0,0.0) [0.0|7] ""  FCU_MLBevo_FCEV

BO_ 220 Motor_FuelCell_01: 8 Gateway
 SG_ MO_FCU_SollModus : 45|5@1+ (1.0,0.0) [0.0|31] ""  FCU_MLBevo_FCEV
 SG_ MO_FCU_SollLeistung : 50|14@1+ (0.1,-200) [-200.0|1438.2] "Unit_KiloWatt"  FCU_MLBevo_FCEV

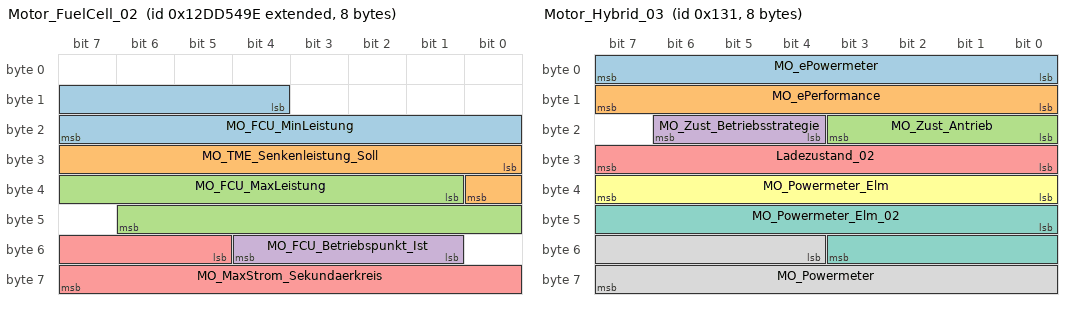
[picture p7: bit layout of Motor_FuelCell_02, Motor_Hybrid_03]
BO_ 2463978654 Motor_FuelCell_02: 8 Gateway
 SG_ MO_FCU_MinLeistung : 12|12@1+ (0.1,-200) [-200.0|209.4] "Unit_KiloWatt"  FCU_MLBevo_FCEV
 SG_ MO_TME_Senkenleistung_Soll : 24|9@1+ (0.1,0) [0.0|51.0] "Unit_KiloWatt"  TME
 SG_ MO_FCU_MaxLeistung : 33|14@1+ (0.1,-200) [-200.0|1438.2] "Unit_KiloWatt"  FCU_MLBevo_FCEV
 SG_ MO_FCU_Betriebspunkt_Ist : 49|4@1+ (1.0,0.0) [0.0|15] ""  FCU_MLBevo_FCEV
 SG_ MO_MaxStrom_Sekundaerkreis : 53|11@1+ (1,0) [0|2046] "Unit_Amper"  FCU_MLBevo_FCEV

BO_ 305 Motor_Hybrid_03: 8 Gateway
 SG_ MO_ePowermeter : 0|8@1+ (0.4,-0.4) [0.0|100.8] "Unit_PerCent"  Sub_Gateway
 SG_ MO_ePerformance : 8|8@1+ (0.4,-0.4) [0.0|100.8] "Unit_PerCent"  Sub_Gateway
 SG_ MO_Zust_Antrieb : 16|4@1+ (1.0,0.0) [0.0|15] ""  Sub_Gateway,TME
 SG_ MO_Zust_Betriebsstrategie : 20|3@1+ (1.0,0.0) [0.0|7] ""  Sub_Gateway,TME
 SG_ Ladezustand_02 : 24|8@1+ (0.5,0) [0.0|100.0] "Unit_PerCent"  Ladegeraet_Konzern,Sub_Gateway,TME
 SG_ MO_Powermeter_Elm : 32|8@1+ (1,-128) [-100|100] "Unit_PerCent"  Sub_Gateway
 SG_ MO_Powermeter_Elm_02 : 40|12@1+ (0.05,-102.4) [-100.00|100.00] "Unit_PerCent"  Sub_Gateway
 SG_ MO_Powermeter : 52|12@1+ (1,0) [0|4092] ""  Sub_Gateway

BO_ 394 Motor_Hybrid_11: 8 Gateway
 SG_ MO_Ablaufstatus : 12|4@1+ (1.0,0.0) [0.0|15] ""  Vector__XXX
 SG_ MO_Ablaufstrg_Betriebszustand : 16|3@1+ (1.0,0.0) [0.0|7] ""  Vector__XXX
 SG_ MO_Ablaufstrg_Zustand_VKM_Ist : 19|1@1+ (1.0,0.0) [0.0|1] ""  Vector__XXX
 SG_ MO_Ablaufstrg_Kraftschluss_Ist : 20|1@1+ (1.0,0.0) [0.0|1] ""  Vector__XXX
 SG_ MO_Ablaufstrg_Zustand_K0_Ist : 21|1@1+ (1.0,0.0) [0.0|1] ""  Vector__XXX
 SG_ MO_Ablaufstrg_Kraftschluss2_Ist : 22|1@1+ (1.0,0.0) [0.0|1] ""  Vector__XXX
 SG_ MO_HYB_LowSpeedModus : 23|1@1+ (1.0,0.0) [0.0|1] ""  Vector__XXX
 SG_ MO_Ablaufstrg_Zustand_VKM_Ziel : 24|1@1+ (1.0,0.0) [0.0|1] ""  Vector__XXX
 SG_ MO_Ablaufstrg_Kraftschluss_Ziel : 25|1@1+ (1.0,0.0) [0.0|1] ""  Vector__XXX
 SG_ MO_Ablaufstrg_Zustand_K0_Ziel : 26|1@1+ (1.0,0.0) [0.0|1] ""  Vector__XXX
 SG_ MO_Ablaufstrg_Kraftschluss2_Ziel : 27|1@1+ (1.0,0.0) [0.0|1] ""  Vector__XXX
 SG_ MO_HYB_Stoppmodus : 28|1@1+ (1.0,0.0) [0.0|1] ""  Vector__XXX
 SG_ MO_Auth_Aufforderung_WFS : 29|1@1+ (1.0,0.0) [0.0|1] ""  Vector__XXX
 SG_ MO_Start_Dynamik : 30|3@1+ (1.0,0.0) [0.0|7] ""  Vector__XXX
 SG_ MO_Start_Art : 33|3@1+ (1.0,0.0) [0.0|7] ""  TME
 SG_ MO_Abstellposition_02 : 36|8@1+ (2,0) [0|508] "Unit_DegreOfArc"  Vector__XXX
 SG_ MO_Mom_Freiheit_Sekundaerachse : 44|1@1+ (1.0,0.0) [0.0|1] ""  Vector__XXX
 SG_ MO_Nachlaufzeit_Kuehlerluefter : 45|6@1+ (15,0) [0|945] "Unit_Secon"  TME
 SG_ MO_Tankklappensteuerung : 51|2@1+ (1.0,0.0) [0.0|3] ""  Vector__XXX
 SG_ MO_HYB_E_Faktor : 53|4@1+ (1.0,0.0) [0.0|15] ""  Vector__XXX
 SG_ MO_HYB_EMode_Info : 57|2@1+ (1.0,0.0) [0.0|3] ""  Vector__XXX
 SG_ MO_HYB_Adaption_aktiv : 59|1@1+ (1.0,0.0) [0.0|1] ""  Vector__XXX

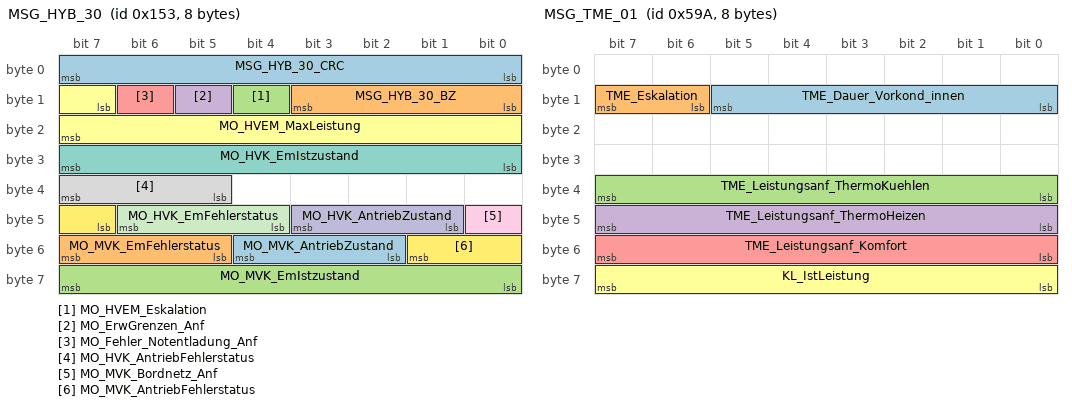
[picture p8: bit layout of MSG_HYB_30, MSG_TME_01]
BO_ 339 MSG_HYB_30: 8 Gateway
 SG_ MSG_HYB_30_CRC : 0|8@1+ (1,0) [0|255] ""  Ladegeraet_Konzern
 SG_ MSG_HYB_30_BZ : 8|4@1+ (1,0) [0|15] ""  Ladegeraet_Konzern
 SG_ MO_HVEM_Eskalation : 12|1@1+ (1.0,0.0) [0.0|1] ""  Vector__XXX
 SG_ MO_ErwGrenzen_Anf : 13|1@1+ (1.0,0.0) [0.0|1] ""  BMC_MLBevo
 SG_ MO_Fehler_Notentladung_Anf : 14|1@1+ (1.0,0.0) [0.0|1] ""  Vector__XXX
 SG_ MO_HVEM_MaxLeistung : 15|9@1+ (50,0) [0|25450] "Unit_Watt"  Vector__XXX
 SG_ MO_HVK_EmIstzustand : 24|8@1+ (1.0,0.0) [0.0|255] ""  Vector__XXX
 SG_ MO_HVK_AntriebFehlerstatus : 37|3@1+ (1.0,0.0) [0.0|7] ""  Vector__XXX
 SG_ MO_MVK_Bordnetz_Anf : 40|1@1+ (1.0,0.0) [0.0|1] ""  Vector__XXX
 SG_ MO_HVK_AntriebZustand : 41|3@1+ (1.0,0.0) [0.0|7] ""  TME
 SG_ MO_HVK_EmFehlerstatus : 44|3@1+ (1.0,0.0) [0.0|7] ""  Vector__XXX
 SG_ MO_MVK_AntriebFehlerstatus : 47|3@1+ (1.0,0.0) [0.0|7] ""  Vector__XXX
 SG_ MO_MVK_AntriebZustand : 50|3@1+ (1.0,0.0) [0.0|7] ""  Vector__XXX
 SG_ MO_MVK_EmFehlerstatus : 53|3@1+ (1.0,0.0) [0.0|7] ""  Vector__XXX
 SG_ MO_MVK_EmIstzustand : 56|8@1+ (1.0,0.0) [0.0|255] ""  Vector__XXX

BO_ 1434 MSG_TME_01: 8 TME
 SG_ TME_Dauer_Vorkond_innen : 8|6@1+ (1,0) [0|60] "Unit_Minut"  Gateway_PAG,Ladegeraet_Konzern
 SG_ TME_Eskalation : 14|2@1+ (1.0,0.0) [0.0|3] ""  Gateway_PAG
 SG_ TME_Leistungsanf_ThermoKuehlen : 32|8@1+ (50,0) [0|12650] "Unit_Watt"  Gateway_PAG
 SG_ TME_Leistungsanf_ThermoHeizen : 40|8@1+ (50,0) [0|12650] "Unit_Watt"  Gateway_PAG
 SG_ TME_Leistungsanf_Komfort : 48|8@1+ (50,0) [0|12650] "Unit_Watt"  Gateway,Gateway_PAG
 SG_ KL_IstLeistung : 56|8@1+ (50,0) [0|12650] "Unit_Watt"  FCU_MLBevo_FCEV,Gateway,Gateway_PAG,Ladegeraet_Konzern

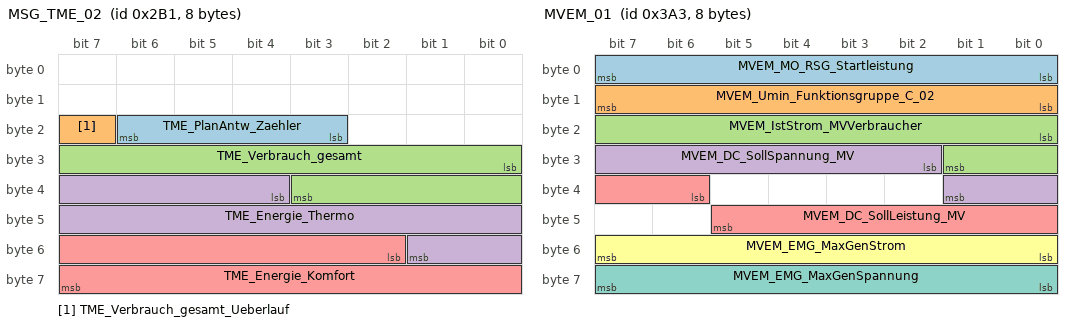
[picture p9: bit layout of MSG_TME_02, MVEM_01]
BO_ 689 MSG_TME_02: 8 TME
 SG_ TME_PlanAntw_Zaehler : 19|4@1+ (1,0) [0|13] "Unit_None"  Gateway,Gateway_PAG,Ladegeraet_2,Ladegeraet_Konzern
 SG_ TME_Verbrauch_gesamt_Ueberlauf : 23|1@1+ (1.0,0.0) [0.0|1] ""  Gateway,Gateway_PAG
 SG_ TME_Verbrauch_gesamt : 24|12@1+ (1,0) [0|4095] "Unit_WattSecond"  Gateway,Gateway_PAG
 SG_ TME_Energie_Thermo : 36|14@1+ (5,0) [0|63250] "Unit_WattHour"  Gateway,Gateway_PAG,Ladegeraet_Konzern
 SG_ TME_Energie_Komfort : 50|14@1+ (5,0) [0|63250] "Unit_WattHour"  Gateway,Gateway_PAG,Ladegeraet_Konzern

BO_ 931 MVEM_01: 8 Gateway
 SG_ MVEM_MO_RSG_Startleistung : 0|8@1+ (500,0) [0|126500] "Unit_Watt"  Vector__XXX
 SG_ MVEM_Umin_Funktionsgruppe_C_02 : 8|8@1+ (0.25,0) [0.00|63.25] "Unit_Volt"  Vector__XXX
 SG_ MVEM_IstStrom_MVVerbraucher : 16|10@1+ (1,-511) [-511|510] "Unit_Amper"  Vector__XXX
 SG_ MVEM_DC_SollSpannung_MV : 26|8@1+ (0.25,0) [0.00|63.25] "Unit_Volt"  DCDC_800V_PAG,DCDC_IHEV
 SG_ MVEM_DC_SollLeistung_MV : 38|8@1+ (25,-6325) [-6325|0] "Unit_Watt"  DCDC_800V_PAG,DCDC_IHEV
 SG_ MVEM_EMG_MaxGenStrom : 48|8@1+ (2,0) [0|506] "Unit_Amper"  Vector__XXX
 SG_ MVEM_EMG_MaxGenSpannung : 56|8@1+ (0.25,0) [0.00|63.25] "Unit_Volt"  Vector__XXX

BO_ 2589283456 MVEM_02: 8 Gateway
 SG_ MVEM_MO_Sollspannung_Notbetrieb : 24|8@1+ (0.25,0) [0.00|63.25] "Unit_Volt"  Vector__XXX
 SG_ MVEM_Umax_Rueckspeisung : 32|8@1+ (0.25,0) [0.00|63.25] "Unit_Volt"  Vector__XXX
 SG_ MVEM_Umin_Funktionsgruppe_C : 40|8@1+ (0.25,0) [0.00|63.25] "Unit_Volt"  Vector__XXX
 SG_ MVEM_Umin_Funktionsgruppe_B : 48|8@1+ (0.25,0) [0.00|63.25] "Unit_Volt"  Vector__XXX
 SG_ MVEM_Umin_Funktionsgruppe_A : 56|8@1+ (0.25,0) [0.00|63.25] "Unit_Volt"  DCDC_800V_PAG,DCDC_IHEV

BO_ 2463978826 MVEM_04: 8 Gateway
 SG_ MVEM_TME_Leistungsfreigabe : 56|8@1+ (50,0) [0|12650] "Unit_Watt"  TME

BO_ 1284 MVK_01: 8 Gateway
 SG_ MVK_01_CRC : 0|8@1+ (1,0) [0|255] ""  DCDC_IHEV
 SG_ MVK_01_BZ : 8|4@1+ (1,0) [0|15] ""  DCDC_IHEV
 SG_ MVK_DCDC_Sollmodus_02 : 12|4@1+ (1.0,0.0) [0.0|15] ""  DCDC_IHEV
 SG_ MVK_eKAT_Sollmodus : 24|3@1+ (1.0,0.0) [0.0|7] ""  Vector__XXX
 SG_ MVK_eKMV_Sollmodus : 27|3@1+ (1.0,0.0) [0.0|7] ""  TME
 SG_ MVK_MVH_L_Sollmodus : 30|3@1+ (1.0,0.0) [0.0|7] ""  TME
 SG_ MV_Bordnetz_aktiv : 33|1@1+ (1.0,0.0) [0.0|1] ""  Vector__XXX
 SG_ MVK_BOOST_Sollmodus : 34|3@1+ (1.0,0.0) [0.0|7] ""  Vector__XXX
 SG_ MVK_eABC_Sollmodus : 37|3@1+ (1.0,0.0) [0.0|7] ""  Vector__XXX
 SG_ MVK_eAWS_Sollmodus : 40|3@1+ (1.0,0.0) [0.0|7] ""  Vector__XXX
 SG_ MV_Bordnetz_Fehler : 43|1@1+ (1.0,0.0) [0.0|1] ""  TME
 SG_ MVK_MVPTC_Sollmodus : 44|3@1+ (1.0,0.0) [0.0|7] ""  TME
 SG_ MVK_Istmodus_Anf : 47|1@1+ (1.0,0.0) [0.0|1] ""  BMS_MV,DCDC_IHEV
 SG_ MVK_MO_EmSollzustand : 48|8@1+ (1.0,0.0) [0.0|255] ""  DCDC_800V_PAG,DCDC_IHEV
 SG_ MVK_BMS_Sollmodus : 56|3@1+ (1.0,0.0) [0.0|7] ""  BMS_MV
 SG_ MVK_DCDC_Sollmodus : 59|3@1+ (1.0,0.0) [0.0|7] ""  DCDC_800V_PAG,DCDC_IHEV
 SG_ MVK_MV_Netz_Warnungen : 62|2@1+ (1.0,0.0) [0.0|3] ""  Vector__XXX

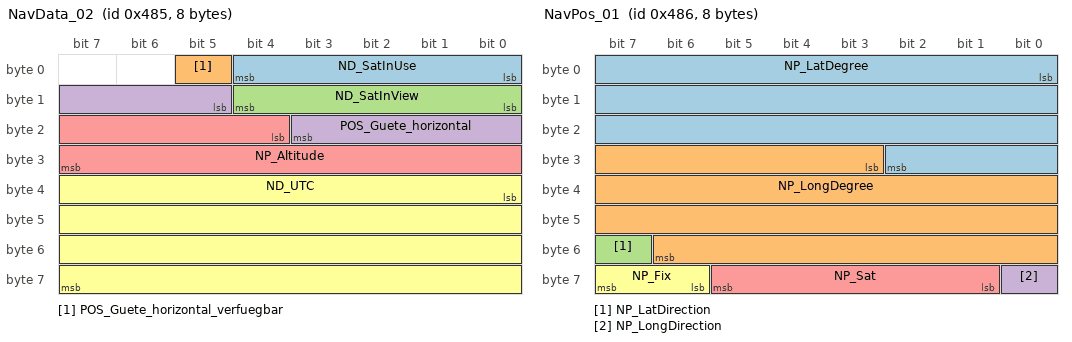
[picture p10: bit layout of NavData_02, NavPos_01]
BO_ 1157 NavData_02: 8 Gateway
 SG_ ND_SatInUse : 0|5@1+ (1,0) [0|29] ""  Sub_Gateway,TME
 SG_ POS_Guete_horizontal_verfuegbar : 5|1@1+ (1.0,0.0) [0.0|1] ""  Sub_Gateway
 SG_ ND_SatInView : 8|5@1+ (1,0) [0|29] ""  Sub_Gateway
 SG_ POS_Guete_horizontal : 13|7@1+ (2,0) [0|246] "Unit_Meter"  Sub_Gateway
 SG_ NP_Altitude : 20|12@1+ (2,-500) [-500|7686] "Unit_Meter"  Sub_Gateway,TME
 SG_ ND_UTC : 32|32@1+ (1,0) [0|4294967293] "Unit_Secon"  Ladegeraet_Konzern,Sub_Gateway

BO_ 1158 NavPos_01: 8 Gateway
 SG_ NP_LatDegree : 0|27@1+ (0.000001,0) [0.000000|90.000000] "Unit_DegreOfArc"  Sub_Gateway
 SG_ NP_LongDegree : 27|28@1+ (0.000001,0) [0.000000|180.000000] "Unit_DegreOfArc"  Sub_Gateway
 SG_ NP_LatDirection : 55|1@1+ (1.0,0.0) [0.0|1] ""  Sub_Gateway
 SG_ NP_LongDirection : 56|1@1+ (1.0,0.0) [0.0|1] ""  Sub_Gateway
 SG_ NP_Sat : 57|5@1+ (1,0) [0|29] ""  Sub_Gateway
 SG_ NP_Fix : 62|2@1+ (1.0,0.0) [0.0|3] ""  Sub_Gateway

BO_ 2589283496 NavPos_02_Map_Matched: 8 Gateway
 SG_ POS_MUX M  : 0|2@1+ (1.0,0.0) [0.0|3] ""  Sub_Gateway
 SG_ POS_ODD_EVEN : 2|1@1+ (1.0,0.0) [0.0|1] ""  Sub_Gateway
 SG_ POS_PosStati m0  : 3|4@1+ (1.0,0.0) [0.0|15] ""  Sub_Gateway
 SG_ POS_Heading m1  : 4|12@1+ (0.1,0) [0.0|409.5] "Unit_DegreOfArc"  Sub_Gateway
 SG_ POS_LatDirection m0  : 7|1@1+ (1.0,0.0) [0.0|1] ""  Sub_Gateway
 SG_ POS_LatDegree m0  : 8|27@1+ (0.000001,0) [0.000000|90.000000] "Unit_DegreOfArc"  Sub_Gateway
 SG_ POS_Last_GPS_Sync m1  : 16|14@1+ (1,0) [0|16383] "Unit_Secon"  Sub_Gateway
 SG_ POS_Heading_Trust m1  : 30|2@1+ (1.0,0.0) [0.0|3] ""  Sub_Gateway
 SG_ POS_UTC_REF m1  : 32|32@1+ (1,0) [0|4294967295] "Unit_Secon"  Sub_Gateway
 SG_ POS_LongDirection m0  : 35|1@1+ (1.0,0.0) [0.0|1] ""  Sub_Gateway
 SG_ POS_LongDegree m0  : 36|28@1+ (0.000001,0) [0.000000|180.000000] "Unit_DegreOfArc"  Sub_Gateway

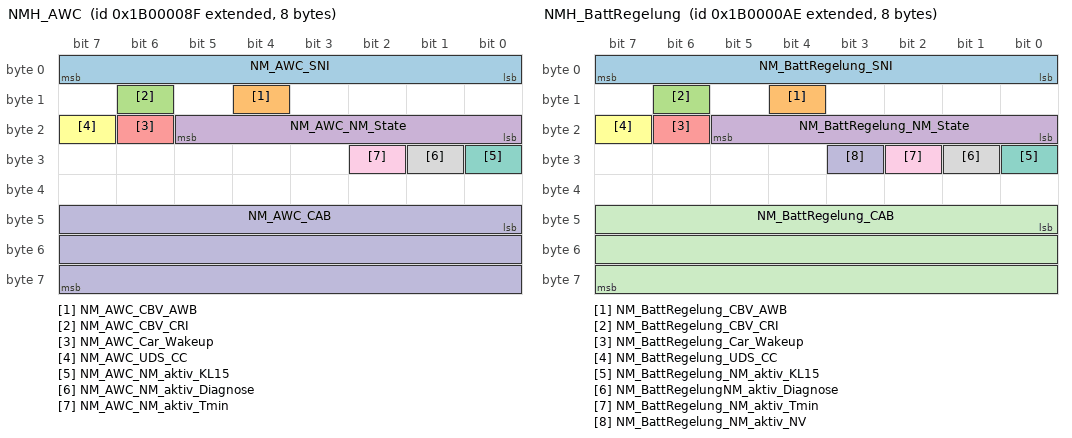
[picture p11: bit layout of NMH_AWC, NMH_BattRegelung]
BO_ 2600468623 NMH_AWC: 8 AWC
 SG_ NM_AWC_SNI : 0|8@1+ (1.0,0.0) [0.0|255] ""  Gateway,LE1,LE2,Sub_Gateway
 SG_ NM_AWC_CBV_AWB : 12|1@1+ (1.0,0.0) [0.0|1] ""  Gateway
 SG_ NM_AWC_CBV_CRI : 14|1@1+ (1.0,0.0) [0.0|1] ""  Gateway,LE1,LE2,Sub_Gateway
 SG_ NM_AWC_NM_State : 16|6@1+ (1.0,0.0) [0.0|63] ""  Vector__XXX
 SG_ NM_AWC_Car_Wakeup : 22|1@1+ (1.0,0.0) [0.0|1] ""  Gateway
 SG_ NM_AWC_UDS_CC : 23|1@1+ (1.0,0.0) [0.0|1] ""  Vector__XXX
 SG_ NM_AWC_NM_aktiv_KL15 : 24|1@1+ (1.0,0.0) [0.0|1] ""  Vector__XXX
 SG_ NM_AWC_NM_aktiv_Diagnose : 25|1@1+ (1.0,0.0) [0.0|1] ""  Vector__XXX
 SG_ NM_AWC_NM_aktiv_Tmin : 26|1@1+ (1.0,0.0) [0.0|1] ""  Vector__XXX
 SG_ NM_AWC_CAB : 40|24@1+ (1.0,0.0) [0.0|16777215] ""  Gateway,LE1,LE2,Sub_Gateway

BO_ 2600468654 NMH_BattRegelung: 8 BMS_NV
 SG_ NM_BattRegelung_SNI : 0|8@1+ (1.0,0.0) [0.0|255] ""  BMC_MLBevo,BMS_MV,CBC,DCDC_800V_PAG,DCDC_HV,DCDC_HV_02,DCDC_IHEV,FCU_MLBevo_FCEV,Gateway,Gateway_PAG,Ladegeraet_2,Ladegeraet_Konzern,LE1,LE2,LE_MLBevo,Sub_Gateway,TME
 SG_ NM_BattRegelung_CBV_AWB : 12|1@1+ (1.0,0.0) [0.0|1] ""  Gateway,Gateway_PAG
 SG_ NM_BattRegelung_CBV_CRI : 14|1@1+ (1.0,0.0) [0.0|1] ""  BMC_MLBevo,BMS_MV,CBC,DCDC_800V_PAG,DCDC_HV,DCDC_HV_02,DCDC_IHEV,FCU_MLBevo_FCEV,Gateway,Gateway_PAG,Ladegeraet_2,Ladegeraet_Konzern,LE1,LE2,LE_MLBevo,Sub_Gateway,TME
 SG_ NM_BattRegelung_NM_State : 16|6@1+ (1.0,0.0) [0.0|63] ""  Vector__XXX
 SG_ NM_BattRegelung_Car_Wakeup : 22|1@1+ (1.0,0.0) [0.0|1] ""  Gateway
 SG_ NM_BattRegelung_UDS_CC : 23|1@1+ (1.0,0.0) [0.0|1] ""  Vector__XXX
 SG_ NM_BattRegelung_NM_aktiv_KL15 : 24|1@1+ (1.0,0.0) [0.0|1] ""  Vector__XXX
 SG_ NM_BattRegelungNM_aktiv_Diagnose : 25|1@1+ (1.0,0.0) [0.0|1] ""  Vector__XXX
 SG_ NM_BattRegelung_NM_aktiv_Tmin : 26|1@1+ (1.0,0.0) [0.0|1] ""  Vector__XXX
 SG_ NM_BattRegelung_NM_aktiv_NV : 27|1@1+ (1.0,0.0) [0.0|1] ""  Vector__XXX
 SG_ NM_BattRegelung_CAB : 40|24@1+ (1.0,0.0) [0.0|16777215] ""  BMC_MLBevo,BMS_MV,CBC,DCDC_800V_PAG,DCDC_HV,DCDC_HV_02,DCDC_IHEV,FCU_MLBevo_FCEV,Gateway,Gateway_PAG,Ladegeraet_2,Ladegeraet_Konzern,LE1,LE2,LE_MLBevo,Sub_Gateway,TME

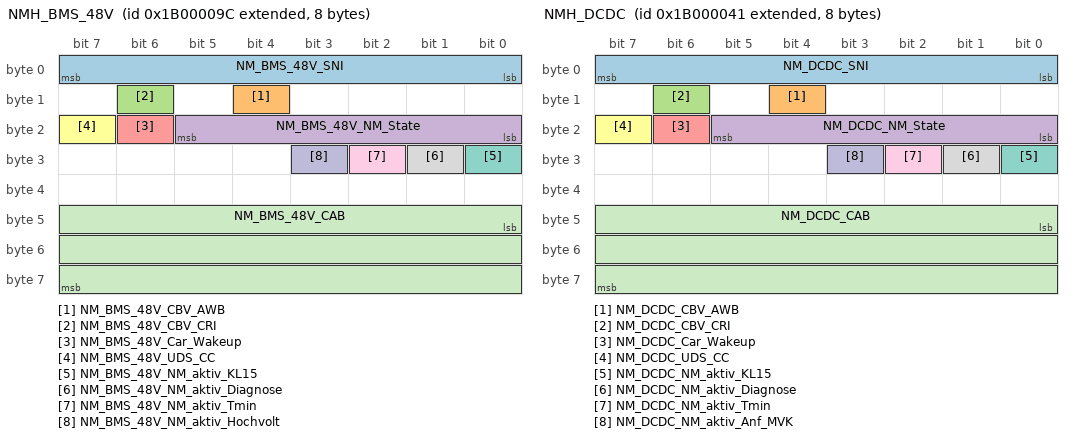
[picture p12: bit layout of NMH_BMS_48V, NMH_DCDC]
BO_ 2600468636 NMH_BMS_48V: 8 BMS_MV
 SG_ NM_BMS_48V_SNI : 0|8@1+ (1.0,0.0) [0.0|255] ""  BMC_MLBevo,BMS_NV,CBC,DCDC_800V_PAG,DCDC_HV,DCDC_HV_02,DCDC_IHEV,Gateway,Gateway_PAG,Ladegeraet_2,Ladegeraet_Konzern,LE1,LE2,LE_MLBevo,Sub_Gateway,TME
 SG_ NM_BMS_48V_CBV_AWB : 12|1@1+ (1.0,0.0) [0.0|1] ""  Gateway,Gateway_PAG
 SG_ NM_BMS_48V_CBV_CRI : 14|1@1+ (1.0,0.0) [0.0|1] ""  BMC_MLBevo,BMS_NV,CBC,DCDC_800V_PAG,DCDC_HV,DCDC_HV_02,DCDC_IHEV,Gateway,Gateway_PAG,Ladegeraet_2,Ladegeraet_Konzern,LE1,LE2,LE_MLBevo,Sub_Gateway,TME
 SG_ NM_BMS_48V_NM_State : 16|6@1+ (1.0,0.0) [0.0|63] ""  Vector__XXX
 SG_ NM_BMS_48V_Car_Wakeup : 22|1@1+ (1.0,0.0) [0.0|1] ""  Gateway,Gateway_PAG
 SG_ NM_BMS_48V_UDS_CC : 23|1@1+ (1.0,0.0) [0.0|1] ""  Vector__XXX
 SG_ NM_BMS_48V_NM_aktiv_KL15 : 24|1@1+ (1.0,0.0) [0.0|1] ""  Vector__XXX
 SG_ NM_BMS_48V_NM_aktiv_Diagnose : 25|1@1+ (1.0,0.0) [0.0|1] ""  Vector__XXX
 SG_ NM_BMS_48V_NM_aktiv_Tmin : 26|1@1+ (1.0,0.0) [0.0|1] ""  Vector__XXX
 SG_ NM_BMS_48V_NM_aktiv_Hochvolt : 27|1@1+ (1.0,0.0) [0.0|1] ""  Vector__XXX
 SG_ NM_BMS_48V_CAB : 40|24@1+ (1.0,0.0) [0.0|16777215] ""  BMC_MLBevo,BMS_NV,CBC,DCDC_800V_PAG,DCDC_HV,DCDC_HV_02,DCDC_IHEV,Gateway,Gateway_PAG,Ladegeraet_2,Ladegeraet_Konzern,LE1,LE2,LE_MLBevo,Sub_Gateway,TME

BO_ 2600468545 NMH_DCDC: 8 DCDC_IHEV
 SG_ NM_DCDC_SNI : 0|8@1+ (1.0,0.0) [0.0|255] ""  BMC_MLBevo,BMS_MV,BMS_NV,CBC,DCDC_HV,DCDC_HV_02,FCU_MLBevo_FCEV,Gateway,Gateway_PAG,Ladegeraet_2,Ladegeraet_Konzern,LE1,LE2,LE_MLBevo,Sub_Gateway,TME
 SG_ NM_DCDC_CBV_AWB : 12|1@1+ (1.0,0.0) [0.0|1] ""  Gateway,Gateway_PAG
 SG_ NM_DCDC_CBV_CRI : 14|1@1+ (1.0,0.0) [0.0|1] ""  BMC_MLBevo,BMS_MV,BMS_NV,CBC,DCDC_HV,DCDC_HV_02,FCU_MLBevo_FCEV,Gateway,Gateway_PAG,Ladegeraet_2,Ladegeraet_Konzern,LE1,LE2,LE_MLBevo,Sub_Gateway,TME
 SG_ NM_DCDC_NM_State : 16|6@1+ (1.0,0.0) [0.0|63] ""  Vector__XXX
 SG_ NM_DCDC_Car_Wakeup : 22|1@1+ (1.0,0.0) [0.0|1] ""  Gateway
 SG_ NM_DCDC_UDS_CC : 23|1@1+ (1.0,0.0) [0.0|1] ""  Vector__XXX
 SG_ NM_DCDC_NM_aktiv_KL15 : 24|1@1+ (1.0,0.0) [0.0|1] ""  Vector__XXX
 SG_ NM_DCDC_NM_aktiv_Diagnose : 25|1@1+ (1.0,0.0) [0.0|1] ""  Vector__XXX
 SG_ NM_DCDC_NM_aktiv_Tmin : 26|1@1+ (1.0,0.0) [0.0|1] ""  Vector__XXX
 SG_ NM_DCDC_NM_aktiv_Anf_MVK : 27|1@1+ (1.0,0.0) [0.0|1] ""  Vector__XXX
 SG_ NM_DCDC_CAB : 40|24@1+ (1.0,0.0) [0.0|16777215] ""  BMC_MLBevo,BMS_MV,BMS_NV,CBC,DCDC_HV,DCDC_HV_02,FCU_MLBevo_FCEV,Gateway,Gateway_PAG,Ladegeraet_2,Ladegeraet_Konzern,LE1,LE2,LE_MLBevo,Sub_Gateway,TME

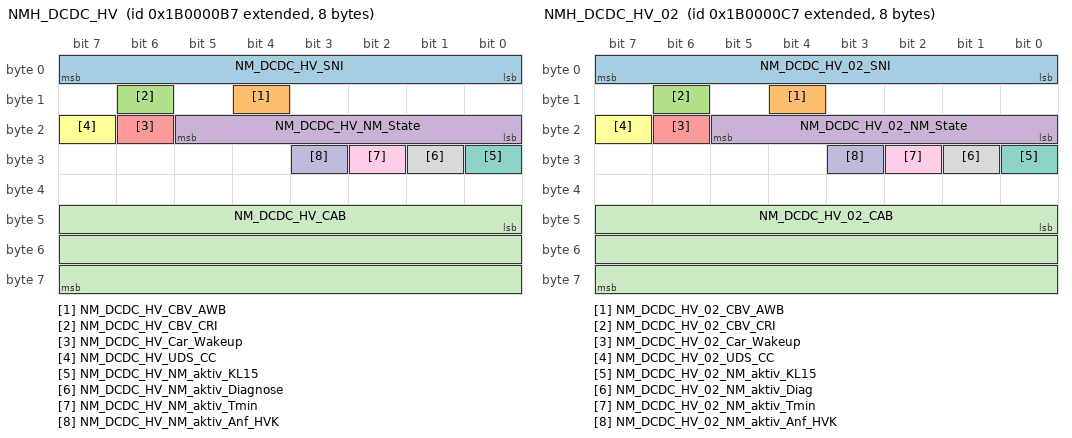
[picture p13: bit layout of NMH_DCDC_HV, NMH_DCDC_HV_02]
BO_ 2600468663 NMH_DCDC_HV: 8 CBC
 SG_ NM_DCDC_HV_SNI : 0|8@1+ (1.0,0.0) [0.0|255] ""  BMC_MLBevo,BMS_MV,BMS_NV,DCDC_HV_02,DCDC_IHEV,Gateway,Gateway_PAG,Ladegeraet_2,Ladegeraet_Konzern,LE1,LE2,LE_MLBevo,Sub_Gateway,TME
 SG_ NM_DCDC_HV_CBV_AWB : 12|1@1+ (1.0,0.0) [0.0|1] ""  Gateway,Gateway_PAG
 SG_ NM_DCDC_HV_CBV_CRI : 14|1@1+ (1.0,0.0) [0.0|1] ""  BMC_MLBevo,BMS_MV,BMS_NV,DCDC_HV_02,DCDC_IHEV,Gateway,Gateway_PAG,Ladegeraet_2,Ladegeraet_Konzern,LE1,LE2,LE_MLBevo,Sub_Gateway,TME
 SG_ NM_DCDC_HV_NM_State : 16|6@1+ (1.0,0.0) [0.0|63] ""  Vector__XXX
 SG_ NM_DCDC_HV_Car_Wakeup : 22|1@1+ (1.0,0.0) [0.0|1] ""  Gateway,Gateway_PAG
 SG_ NM_DCDC_HV_UDS_CC : 23|1@1+ (1.0,0.0) [0.0|1] ""  Vector__XXX
 SG_ NM_DCDC_HV_NM_aktiv_KL15 : 24|1@1+ (1.0,0.0) [0.0|1] ""  Vector__XXX
 SG_ NM_DCDC_HV_NM_aktiv_Diagnose : 25|1@1+ (1.0,0.0) [0.0|1] ""  Vector__XXX
 SG_ NM_DCDC_HV_NM_aktiv_Tmin : 26|1@1+ (1.0,0.0) [0.0|1] ""  Vector__XXX
 SG_ NM_DCDC_HV_NM_aktiv_Anf_HVK : 27|1@1+ (1.0,0.0) [0.0|1] ""  Vector__XXX
 SG_ NM_DCDC_HV_CAB : 40|24@1+ (1.0,0.0) [0.0|16777215] ""  BMC_MLBevo,BMS_MV,BMS_NV,DCDC_HV_02,DCDC_IHEV,Gateway,Gateway_PAG,Ladegeraet_2,Ladegeraet_Konzern,LE1,LE2,LE_MLBevo,Sub_Gateway,TME

BO_ 2600468679 NMH_DCDC_HV_02: 8 DCDC_HV_02
 SG_ NM_DCDC_HV_02_SNI : 0|8@1+ (1.0,0.0) [0.0|255] ""  BMC_MLBevo,BMS_MV,BMS_NV,DCDC_800V_PAG,DCDC_HV,DCDC_IHEV,FCU_MLBevo_FCEV,Gateway,Gateway_PAG,Ladegeraet_2,Ladegeraet_Konzern,LE1,LE2,LE_MLBevo,Sub_Gateway,TME
 SG_ NM_DCDC_HV_02_CBV_AWB : 12|1@1+ (1.0,0.0) [0.0|1] ""  Gateway,Gateway_PAG
 SG_ NM_DCDC_HV_02_CBV_CRI : 14|1@1+ (1.0,0.0) [0.0|1] ""  BMC_MLBevo,BMS_MV,BMS_NV,DCDC_800V_PAG,DCDC_HV,DCDC_IHEV,FCU_MLBevo_FCEV,Gateway,Gateway_PAG,Ladegeraet_2,Ladegeraet_Konzern,LE1,LE2,LE_MLBevo,Sub_Gateway,TME
 SG_ NM_DCDC_HV_02_NM_State : 16|6@1+ (1.0,0.0) [0.0|63] ""  Vector__XXX
 SG_ NM_DCDC_HV_02_Car_Wakeup : 22|1@1+ (1.0,0.0) [0.0|1] ""  Gateway,Gateway_PAG
 SG_ NM_DCDC_HV_02_UDS_CC : 23|1@1+ (1.0,0.0) [0.0|1] ""  Vector__XXX
 SG_ NM_DCDC_HV_02_NM_aktiv_KL15 : 24|1@1+ (1.0,0.0) [0.0|1] ""  Vector__XXX
 SG_ NM_DCDC_HV_02_NM_aktiv_Diag : 25|1@1+ (1.0,0.0) [0.0|1] ""  Vector__XXX
 SG_ NM_DCDC_HV_02_NM_aktiv_Tmin : 26|1@1+ (1.0,0.0) [0.0|1] ""  Vector__XXX
 SG_ NM_DCDC_HV_02_NM_aktiv_Anf_HVK : 27|1@1+ (1.0,0.0) [0.0|1] ""  Vector__XXX
 SG_ NM_DCDC_HV_02_CAB : 40|24@1+ (1.0,0.0) [0.0|16777215] ""  BMC_MLBevo,BMS_MV,BMS_NV,DCDC_800V_PAG,DCDC_HV,DCDC_IHEV,FCU_MLBevo_FCEV,Gateway,Gateway_PAG,Ladegeraet_2,Ladegeraet_Konzern,LE1,LE2,LE_MLBevo,Sub_Gateway,TME

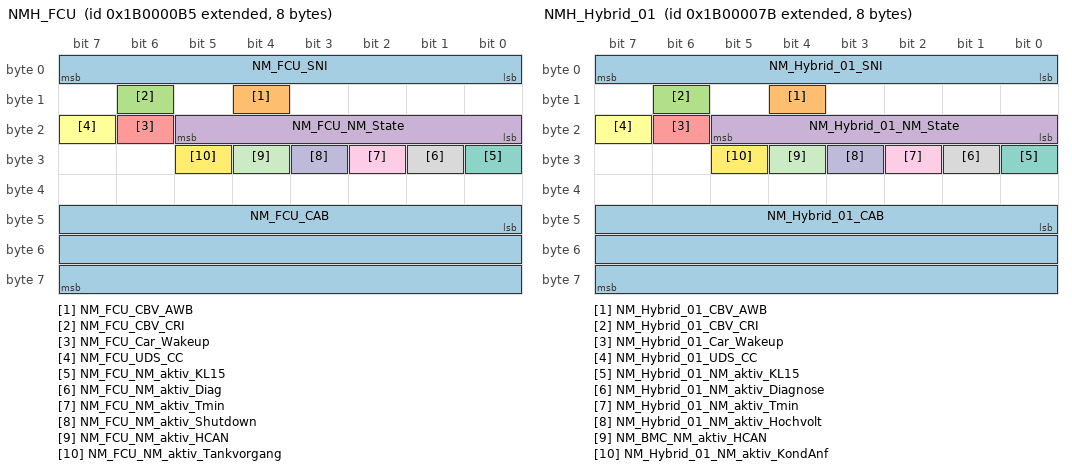
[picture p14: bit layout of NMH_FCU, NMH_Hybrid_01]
BO_ 2600468661 NMH_FCU: 8 FCU_MLBevo_FCEV
 SG_ NM_FCU_SNI : 0|8@1+ (1.0,0.0) [0.0|255] ""  Gateway
 SG_ NM_FCU_CBV_AWB : 12|1@1+ (1.0,0.0) [0.0|1] ""  Vector__XXX
 SG_ NM_FCU_CBV_CRI : 14|1@1+ (1.0,0.0) [0.0|1] ""  Gateway
 SG_ NM_FCU_NM_State : 16|6@1+ (1.0,0.0) [0.0|63] ""  Vector__XXX
 SG_ NM_FCU_Car_Wakeup : 22|1@1+ (1.0,0.0) [0.0|1] ""  Gateway
 SG_ NM_FCU_UDS_CC : 23|1@1+ (1.0,0.0) [0.0|1] ""  Vector__XXX
 SG_ NM_FCU_NM_aktiv_KL15 : 24|1@1+ (1.0,0.0) [0.0|1] ""  Vector__XXX
 SG_ NM_FCU_NM_aktiv_Diag : 25|1@1+ (1.0,0.0) [0.0|1] ""  Vector__XXX
 SG_ NM_FCU_NM_aktiv_Tmin : 26|1@1+ (1.0,0.0) [0.0|1] ""  Vector__XXX
 SG_ NM_FCU_NM_aktiv_Shutdown : 27|1@1+ (1.0,0.0) [0.0|1] ""  Vector__XXX
 SG_ NM_FCU_NM_aktiv_HCAN : 28|1@1+ (1.0,0.0) [0.0|1] ""  Vector__XXX
 SG_ NM_FCU_NM_aktiv_Tankvorgang : 29|1@1+ (1.0,0.0) [0.0|1] ""  Vector__XXX
 SG_ NM_FCU_CAB : 40|24@1+ (1.0,0.0) [0.0|16777215] ""  Gateway

BO_ 2600468496 NMH_Gateway: 8 Gateway
 SG_ NM_Gateway_SNI : 0|8@1+ (1.0,0.0) [0.0|255] ""  BMC_MLBevo,BMS_MV,BMS_NV,CBC,DCDC_800V_PAG,DCDC_HV,DCDC_HV_02,DCDC_IHEV,FCU_MLBevo_FCEV,Ladegeraet_2,Ladegeraet_Konzern,LE1,LE2,LE_MLBevo,Sub_Gateway,TME
 SG_ NM_Gateway_CBV_AWB : 12|1@1+ (1.0,0.0) [0.0|1] ""  Vector__XXX
 SG_ NM_Gateway_CBV_CRI : 14|1@1+ (1.0,0.0) [0.0|1] ""  BMC_MLBevo,BMS_MV,BMS_NV,CBC,DCDC_800V_PAG,DCDC_HV,DCDC_HV_02,DCDC_IHEV,FCU_MLBevo_FCEV,Ladegeraet_2,Ladegeraet_Konzern,LE1,LE2,LE_MLBevo,Sub_Gateway,TME
 SG_ NM_Gateway_NM_State : 16|6@1+ (1.0,0.0) [0.0|63] ""  Vector__XXX
 SG_ NM_Gateway_Car_Wakeup : 22|1@1+ (1.0,0.0) [0.0|1] ""  Vector__XXX
 SG_ NM_Gateway_UDS_CC : 23|1@1+ (1.0,0.0) [0.0|1] ""  Vector__XXX
 SG_ NM_Gateway_NM_aktiv_KL15 : 24|1@1+ (1.0,0.0) [0.0|1] ""  Vector__XXX
 SG_ NM_Gateway_NM_aktiv_Diagnose : 25|1@1+ (1.0,0.0) [0.0|1] ""  Vector__XXX
 SG_ NM_Gateway_NM_aktiv_Tmin : 26|1@1+ (1.0,0.0) [0.0|1] ""  Vector__XXX
 SG_ NM_Gateway_NM_aktiv_CWU : 27|1@1+ (1.0,0.0) [0.0|1] ""  Vector__XXX
 SG_ NM_Gateway_NM_aktiv_FC : 28|1@1+ (1.0,0.0) [0.0|1] ""  Vector__XXX
 SG_ NM_Gateway_NM_aktiv_Connect : 29|1@1+ (1.0,0.0) [0.0|1] ""  Vector__XXX
 SG_ NM_Gateway_NM_aktiv_EM : 30|1@1+ (1.0,0.0) [0.0|1] ""  Vector__XXX
 SG_ NM_Gateway_NM_aktiv_OBDC : 31|1@1+ (1.0,0.0) [0.0|1] ""  Vector__XXX
 SG_ NM_Gateway_NM_aktiv_Buskopplung : 32|1@1+ (1.0,0.0) [0.0|1] ""  Vector__XXX
 SG_ NM_Gateway_NM_aktiv_LIN2 : 33|1@1+ (1.0,0.0) [0.0|1] ""  Vector__XXX
 SG_ NM_Gateway_NM_aktiv_Fremdladung : 34|1@1+ (1.0,0.0) [0.0|1] ""  Vector__XXX
 SG_ NM_Gateway_CAB : 40|24@1+ (1.0,0.0) [0.0|16777215] ""  BMC_MLBevo,BMS_MV,BMS_NV,CBC,DCDC_800V_PAG,DCDC_HV,DCDC_HV_02,DCDC_IHEV,FCU_MLBevo_FCEV,Ladegeraet_2,Ladegeraet_Konzern,LE1,LE2,LE_MLBevo,Sub_Gateway,TME

BO_ 2600468603 NMH_Hybrid_01: 8 BMC_MLBevo
 SG_ NM_Hybrid_01_SNI : 0|8@1+ (1.0,0.0) [0.0|255] ""  BMS_MV,BMS_NV,CBC,DCDC_800V_PAG,DCDC_HV,DCDC_HV_02,DCDC_IHEV,FCU_MLBevo_FCEV,Gateway,Gateway_PAG,Ladegeraet_2,Ladegeraet_Konzern,LE1,LE2,LE_MLBevo,Sub_Gateway,TME
 SG_ NM_Hybrid_01_CBV_AWB : 12|1@1+ (1.0,0.0) [0.0|1] ""  Gateway,Gateway_PAG
 SG_ NM_Hybrid_01_CBV_CRI : 14|1@1+ (1.0,0.0) [0.0|1] ""  BMS_MV,BMS_NV,CBC,DCDC_800V_PAG,DCDC_HV,DCDC_HV_02,DCDC_IHEV,FCU_MLBevo_FCEV,Gateway,Gateway_PAG,Ladegeraet_2,Ladegeraet_Konzern,LE1,LE2,LE_MLBevo,Sub_Gateway,TME
 SG_ NM_Hybrid_01_NM_State : 16|6@1+ (1.0,0.0) [0.0|63] ""  Vector__XXX
 SG_ NM_Hybrid_01_Car_Wakeup : 22|1@1+ (1.0,0.0) [0.0|1] ""  Gateway
 SG_ NM_Hybrid_01_UDS_CC : 23|1@1+ (1.0,0.0) [0.0|1] ""  Vector__XXX
 SG_ NM_Hybrid_01_NM_aktiv_KL15 : 24|1@1+ (1.0,0.0) [0.0|1] ""  Vector__XXX
 SG_ NM_Hybrid_01_NM_aktiv_Diagnose : 25|1@1+ (1.0,0.0) [0.0|1] ""  Vector__XXX
 SG_ NM_Hybrid_01_NM_aktiv_Tmin : 26|1@1+ (1.0,0.0) [0.0|1] ""  Vector__XXX
 SG_ NM_Hybrid_01_NM_aktiv_Hochvolt : 27|1@1+ (1.0,0.0) [0.0|1] ""  Vector__XXX
 SG_ NM_BMC_NM_aktiv_HCAN : 28|1@1+ (1.0,0.0) [0.0|1] ""  Vector__XXX
 SG_ NM_Hybrid_01_NM_aktiv_KondAnf : 29|1@1+ (1.0,0.0) [0.0|1] ""  Vector__XXX
 SG_ NM_Hybrid_01_CAB : 40|24@1+ (1.0,0.0) [0.0|16777215] ""  BMS_MV,BMS_NV,CBC,DCDC_800V_PAG,DCDC_HV,DCDC_HV_02,DCDC_IHEV,FCU_MLBevo_FCEV,Gateway,Gateway_PAG,Ladegeraet_2,Ladegeraet_Konzern,LE1,LE2,LE_MLBevo,Sub_Gateway,TME

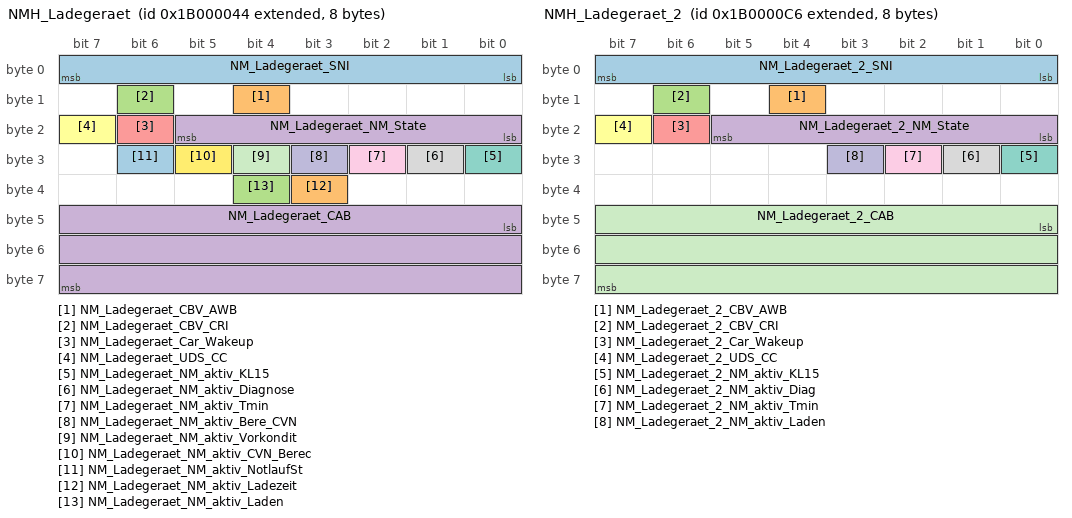
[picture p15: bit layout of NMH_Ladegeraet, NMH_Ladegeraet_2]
BO_ 2600468548 NMH_Ladegeraet: 8 Ladegeraet_Konzern
 SG_ NM_Ladegeraet_SNI : 0|8@1+ (1.0,0.0) [0.0|255] ""  BMC_MLBevo,BMS_MV,BMS_NV,CBC,DCDC_800V_PAG,DCDC_HV,DCDC_HV_02,DCDC_IHEV,FCU_MLBevo_FCEV,Gateway,Gateway_PAG,Ladegeraet_2,LE1,LE2,LE_MLBevo,Sub_Gateway,TME
 SG_ NM_Ladegeraet_CBV_AWB : 12|1@1+ (1.0,0.0) [0.0|1] ""  Gateway,Gateway_PAG
 SG_ NM_Ladegeraet_CBV_CRI : 14|1@1+ (1.0,0.0) [0.0|1] ""  BMC_MLBevo,BMS_MV,BMS_NV,CBC,DCDC_800V_PAG,DCDC_HV,DCDC_HV_02,DCDC_IHEV,FCU_MLBevo_FCEV,Gateway,Gateway_PAG,Ladegeraet_2,LE1,LE2,LE_MLBevo,Sub_Gateway,TME
 SG_ NM_Ladegeraet_NM_State : 16|6@1+ (1.0,0.0) [0.0|63] ""  Vector__XXX
 SG_ NM_Ladegeraet_Car_Wakeup : 22|1@1+ (1.0,0.0) [0.0|1] ""  Gateway
 SG_ NM_Ladegeraet_UDS_CC : 23|1@1+ (1.0,0.0) [0.0|1] ""  Vector__XXX
 SG_ NM_Ladegeraet_NM_aktiv_KL15 : 24|1@1+ (1.0,0.0) [0.0|1] ""  Vector__XXX
 SG_ NM_Ladegeraet_NM_aktiv_Diagnose : 25|1@1+ (1.0,0.0) [0.0|1] ""  Vector__XXX
 SG_ NM_Ladegeraet_NM_aktiv_Tmin : 26|1@1+ (1.0,0.0) [0.0|1] ""  Vector__XXX
 SG_ NM_Ladegeraet_NM_aktiv_Bere_CVN : 27|1@1+ (1.0,0.0) [0.0|1] ""  Vector__XXX
 SG_ NM_Ladegeraet_NM_aktiv_Vorkondit : 28|1@1+ (1.0,0.0) [0.0|1] ""  Vector__XXX
 SG_ NM_Ladegeraet_NM_aktiv_CVN_Berec : 29|1@1+ (1.0,0.0) [0.0|1] ""  Vector__XXX
 SG_ NM_Ladegeraet_NM_aktiv_NotlaufSt : 30|1@1+ (1.0,0.0) [0.0|1] ""  Vector__XXX
 SG_ NM_Ladegeraet_NM_aktiv_Ladezeit : 35|1@1+ (1.0,0.0) [0.0|1] ""  Vector__XXX
 SG_ NM_Ladegeraet_NM_aktiv_Laden : 36|1@1+ (1.0,0.0) [0.0|1] ""  Vector__XXX
 SG_ NM_Ladegeraet_CAB : 40|24@1+ (1.0,0.0) [0.0|16777215] ""  BMC_MLBevo,BMS_MV,BMS_NV,CBC,DCDC_800V_PAG,DCDC_HV,DCDC_HV_02,DCDC_IHEV,FCU_MLBevo_FCEV,Gateway,Gateway_PAG,Ladegeraet_2,LE1,LE2,LE_MLBevo,Sub_Gateway,TME

BO_ 2600468678 NMH_Ladegeraet_2: 8 Ladegeraet_2
 SG_ NM_Ladegeraet_2_SNI : 0|8@1+ (1.0,0.0) [0.0|255] ""  BMC_MLBevo,BMS_MV,BMS_NV,CBC,DCDC_800V_PAG,DCDC_HV,DCDC_HV_02,DCDC_IHEV,FCU_MLBevo_FCEV,Gateway,Gateway_PAG,Ladegeraet_Konzern,LE1,LE2,LE_MLBevo,Sub_Gateway,TME
 SG_ NM_Ladegeraet_2_CBV_AWB : 12|1@1+ (1.0,0.0) [0.0|1] ""  Gateway,Gateway_PAG
 SG_ NM_Ladegeraet_2_CBV_CRI : 14|1@1+ (1.0,0.0) [0.0|1] ""  BMC_MLBevo,BMS_MV,BMS_NV,CBC,DCDC_800V_PAG,DCDC_HV,DCDC_HV_02,DCDC_IHEV,FCU_MLBevo_FCEV,Gateway,Gateway_PAG,Ladegeraet_Konzern,LE1,LE2,LE_MLBevo,Sub_Gateway,TME
 SG_ NM_Ladegeraet_2_NM_State : 16|6@1+ (1.0,0.0) [0.0|63] ""  Vector__XXX
 SG_ NM_Ladegeraet_2_Car_Wakeup : 22|1@1+ (1.0,0.0) [0.0|1] ""  Gateway,Gateway_PAG
 SG_ NM_Ladegeraet_2_UDS_CC : 23|1@1+ (1.0,0.0) [0.0|1] ""  Gateway,Gateway_PAG
 SG_ NM_Ladegeraet_2_NM_aktiv_KL15 : 24|1@1+ (1.0,0.0) [0.0|1] ""  Vector__XXX
 SG_ NM_Ladegeraet_2_NM_aktiv_Diag : 25|1@1+ (1.0,0.0) [0.0|1] ""  Vector__XXX
 SG_ NM_Ladegeraet_2_NM_aktiv_Tmin : 26|1@1+ (1.0,0.0) [0.0|1] ""  Vector__XXX
 SG_ NM_Ladegeraet_2_NM_aktiv_Laden : 27|1@1+ (1.0,0.0) [0.0|1] ""  Vector__XXX
 SG_ NM_Ladegeraet_2_CAB : 40|24@1+ (1.0,0.0) [0.0|16777215] ""  BMC_MLBevo,BMS_MV,BMS_NV,CBC,DCDC_800V_PAG,DCDC_HV,DCDC_HV_02,DCDC_IHEV,FCU_MLBevo_FCEV,Gateway,Gateway_PAG,Ladegeraet_Konzern,LE1,LE2,LE_MLBevo,Sub_Gateway,TME

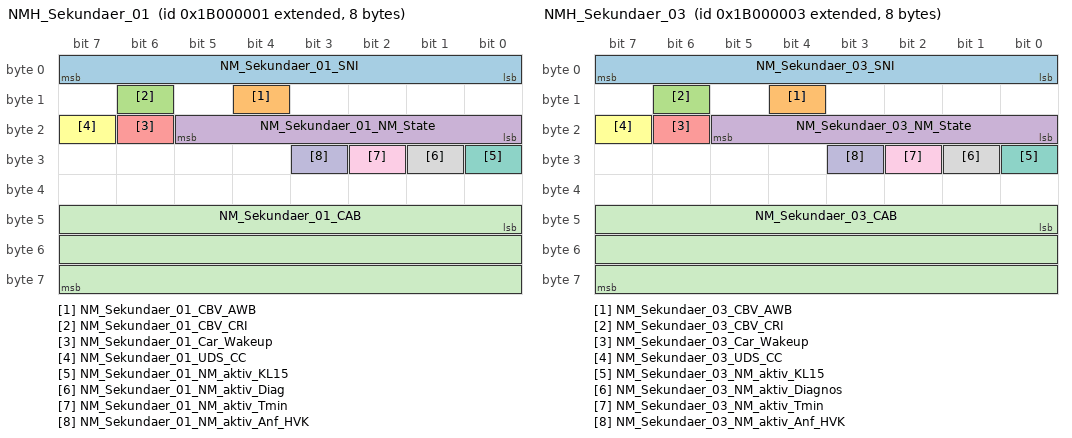
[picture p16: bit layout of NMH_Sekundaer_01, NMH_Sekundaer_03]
BO_ 2600468481 NMH_Sekundaer_01: 8 LE2
 SG_ NM_Sekundaer_01_SNI : 0|8@1+ (1.0,0.0) [0.0|255] ""  BMC_MLBevo,BMS_MV,BMS_NV,CBC,DCDC_800V_PAG,DCDC_HV,DCDC_HV_02,DCDC_IHEV,Gateway,Gateway_PAG,Ladegeraet_2,Ladegeraet_Konzern,LE1,LE_MLBevo,Sub_Gateway,TME
 SG_ NM_Sekundaer_01_CBV_AWB : 12|1@1+ (1.0,0.0) [0.0|1] ""  Gateway
 SG_ NM_Sekundaer_01_CBV_CRI : 14|1@1+ (1.0,0.0) [0.0|1] ""  BMC_MLBevo,BMS_MV,BMS_NV,CBC,DCDC_800V_PAG,DCDC_HV,DCDC_HV_02,DCDC_IHEV,Gateway,Gateway_PAG,Ladegeraet_2,Ladegeraet_Konzern,LE1,LE_MLBevo,Sub_Gateway,TME
 SG_ NM_Sekundaer_01_NM_State : 16|6@1+ (1.0,0.0) [0.0|63] ""  Vector__XXX
 SG_ NM_Sekundaer_01_Car_Wakeup : 22|1@1+ (1.0,0.0) [0.0|1] ""  Gateway
 SG_ NM_Sekundaer_01_UDS_CC : 23|1@1+ (1.0,0.0) [0.0|1] ""  Vector__XXX
 SG_ NM_Sekundaer_01_NM_aktiv_KL15 : 24|1@1+ (1.0,0.0) [0.0|1] ""  Vector__XXX
 SG_ NM_Sekundaer_01_NM_aktiv_Diag : 25|1@1+ (1.0,0.0) [0.0|1] ""  Vector__XXX
 SG_ NM_Sekundaer_01_NM_aktiv_Tmin : 26|1@1+ (1.0,0.0) [0.0|1] ""  Vector__XXX
 SG_ NM_Sekundaer_01_NM_aktiv_Anf_HVK : 27|1@1+ (1.0,0.0) [0.0|1] ""  Vector__XXX
 SG_ NM_Sekundaer_01_CAB : 40|24@1+ (1.0,0.0) [0.0|16777215] ""  BMC_MLBevo,BMS_MV,BMS_NV,CBC,DCDC_800V_PAG,DCDC_HV,DCDC_HV_02,DCDC_IHEV,Gateway,Gateway_PAG,Ladegeraet_2,Ladegeraet_Konzern,LE1,LE_MLBevo,Sub_Gateway,TME

BO_ 2600468483 NMH_Sekundaer_03: 8 LE1
 SG_ NM_Sekundaer_03_SNI : 0|8@1+ (1.0,0.0) [0.0|255] ""  BMC_MLBevo,BMS_MV,BMS_NV,CBC,DCDC_800V_PAG,DCDC_HV,DCDC_HV_02,DCDC_IHEV,Gateway,Gateway_PAG,Ladegeraet_2,Ladegeraet_Konzern,LE2,Sub_Gateway,TME
 SG_ NM_Sekundaer_03_CBV_AWB : 12|1@1+ (1.0,0.0) [0.0|1] ""  Gateway,Gateway_PAG
 SG_ NM_Sekundaer_03_CBV_CRI : 14|1@1+ (1.0,0.0) [0.0|1] ""  BMC_MLBevo,BMS_MV,BMS_NV,CBC,DCDC_800V_PAG,DCDC_HV,DCDC_HV_02,DCDC_IHEV,Gateway,Gateway_PAG,Ladegeraet_2,Ladegeraet_Konzern,LE2,Sub_Gateway,TME
 SG_ NM_Sekundaer_03_NM_State : 16|6@1+ (1.0,0.0) [0.0|63] ""  Vector__XXX
 SG_ NM_Sekundaer_03_Car_Wakeup : 22|1@1+ (1.0,0.0) [0.0|1] ""  Vector__XXX
 SG_ NM_Sekundaer_03_UDS_CC : 23|1@1+ (1.0,0.0) [0.0|1] ""  Vector__XXX
 SG_ NM_Sekundaer_03_NM_aktiv_KL15 : 24|1@1+ (1.0,0.0) [0.0|1] ""  Vector__XXX
 SG_ NM_Sekundaer_03_NM_aktiv_Diagnos : 25|1@1+ (1.0,0.0) [0.0|1] ""  Vector__XXX
 SG_ NM_Sekundaer_03_NM_aktiv_Tmin : 26|1@1+ (1.0,0.0) [0.0|1] ""  Vector__XXX
 SG_ NM_Sekundaer_03_NM_aktiv_Anf_HVK : 27|1@1+ (1.0,0.0) [0.0|1] ""  Vector__XXX
 SG_ NM_Sekundaer_03_CAB : 40|24@1+ (1.0,0.0) [0.0|16777215] ""  BMC_MLBevo,BMS_MV,BMS_NV,CBC,DCDC_800V_PAG,DCDC_HV,DCDC_HV_02,DCDC_IHEV,Gateway,Gateway_PAG,Ladegeraet_2,Ladegeraet_Konzern,LE2,Sub_Gateway,TME

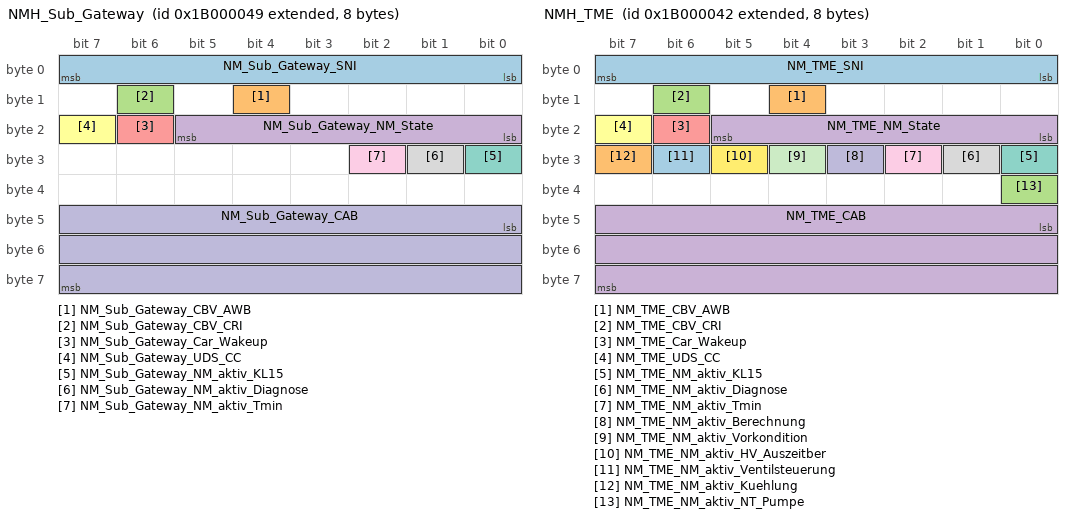
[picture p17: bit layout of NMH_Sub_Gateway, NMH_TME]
BO_ 2600468553 NMH_Sub_Gateway: 8 Sub_Gateway
 SG_ NM_Sub_Gateway_SNI : 0|8@1+ (1.0,0.0) [0.0|255] ""  AWC,BMC_MLBevo,BMS_MV,BMS_NV,CBC,DCDC_800V_PAG,DCDC_HV,DCDC_HV_02,DCDC_IHEV,FCU_MLBevo_FCEV,Gateway,Ladegeraet_2,Ladegeraet_Konzern,LE1,LE2,LE_MLBevo,TME
 SG_ NM_Sub_Gateway_CBV_AWB : 12|1@1+ (1.0,0.0) [0.0|1] ""  Gateway
 SG_ NM_Sub_Gateway_CBV_CRI : 14|1@1+ (1.0,0.0) [0.0|1] ""  AWC,BMC_MLBevo,BMS_MV,BMS_NV,CBC,DCDC_800V_PAG,DCDC_HV,DCDC_HV_02,DCDC_IHEV,FCU_MLBevo_FCEV,Gateway,Ladegeraet_2,Ladegeraet_Konzern,LE1,LE2,LE_MLBevo,TME
 SG_ NM_Sub_Gateway_NM_State : 16|6@1+ (1.0,0.0) [0.0|63] ""  Vector__XXX
 SG_ NM_Sub_Gateway_Car_Wakeup : 22|1@1+ (1.0,0.0) [0.0|1] ""  Gateway
 SG_ NM_Sub_Gateway_UDS_CC : 23|1@1+ (1.0,0.0) [0.0|1] ""  Vector__XXX
 SG_ NM_Sub_Gateway_NM_aktiv_KL15 : 24|1@1+ (1.0,0.0) [0.0|1] ""  Vector__XXX
 SG_ NM_Sub_Gateway_NM_aktiv_Diagnose : 25|1@1+ (1.0,0.0) [0.0|1] ""  Vector__XXX
 SG_ NM_Sub_Gateway_NM_aktiv_Tmin : 26|1@1+ (1.0,0.0) [0.0|1] ""  Vector__XXX
 SG_ NM_Sub_Gateway_CAB : 40|24@1+ (1.0,0.0) [0.0|16777215] ""  AWC,BMC_MLBevo,BMS_MV,BMS_NV,CBC,DCDC_800V_PAG,DCDC_HV,DCDC_HV_02,DCDC_IHEV,FCU_MLBevo_FCEV,Gateway,Ladegeraet_2,Ladegeraet_Konzern,LE1,LE2,LE_MLBevo,TME

BO_ 2600468546 NMH_TME: 8 TME
 SG_ NM_TME_SNI : 0|8@1+ (1.0,0.0) [0.0|255] ""  BMC_MLBevo,BMS_MV,BMS_NV,CBC,DCDC_800V_PAG,DCDC_HV,DCDC_HV_02,DCDC_IHEV,FCU_MLBevo_FCEV,Gateway,Gateway_PAG,Ladegeraet_2,Ladegeraet_Konzern,LE1,LE2,LE_MLBevo,Sub_Gateway
 SG_ NM_TME_CBV_AWB : 12|1@1+ (1.0,0.0) [0.0|1] ""  Gateway,Gateway_PAG
 SG_ NM_TME_CBV_CRI : 14|1@1+ (1.0,0.0) [0.0|1] ""  BMC_MLBevo,BMS_MV,BMS_NV,CBC,DCDC_800V_PAG,DCDC_HV,DCDC_HV_02,DCDC_IHEV,FCU_MLBevo_FCEV,Gateway,Gateway_PAG,Ladegeraet_2,Ladegeraet_Konzern,LE1,LE2,LE_MLBevo,Sub_Gateway
 SG_ NM_TME_NM_State : 16|6@1+ (1.0,0.0) [0.0|63] ""  Vector__XXX
 SG_ NM_TME_Car_Wakeup : 22|1@1+ (1.0,0.0) [0.0|1] ""  Gateway,Gateway_PAG
 SG_ NM_TME_UDS_CC : 23|1@1+ (1.0,0.0) [0.0|1] ""  Vector__XXX
 SG_ NM_TME_NM_aktiv_KL15 : 24|1@1+ (1.0,0.0) [0.0|1] ""  Vector__XXX
 SG_ NM_TME_NM_aktiv_Diagnose : 25|1@1+ (1.0,0.0) [0.0|1] ""  Vector__XXX
 SG_ NM_TME_NM_aktiv_Tmin : 26|1@1+ (1.0,0.0) [0.0|1] ""  Vector__XXX
 SG_ NM_TME_NM_aktiv_Berechnung : 27|1@1+ (1.0,0.0) [0.0|1] ""  Vector__XXX
 SG_ NM_TME_NM_aktiv_Vorkondition : 28|1@1+ (1.0,0.0) [0.0|1] ""  Vector__XXX
 SG_ NM_TME_NM_aktiv_HV_Auszeitber : 29|1@1+ (1.0,0.0) [0.0|1] ""  Vector__XXX
 SG_ NM_TME_NM_aktiv_Ventilsteuerung : 30|1@1+ (1.0,0.0) [0.0|1] ""  Vector__XXX
 SG_ NM_TME_NM_aktiv_Kuehlung : 31|1@1+ (1.0,0.0) [0.0|1] ""  Vector__XXX
 SG_ NM_TME_NM_aktiv_NT_Pumpe : 32|1@1+ (1.0,0.0) [0.0|1] ""  Vector__XXX
 SG_ NM_TME_CAB : 40|24@1+ (1.0,0.0) [0.0|16777215] ""  BMC_MLBevo,BMS_MV,BMS_NV,CBC,DCDC_800V_PAG,DCDC_HV,DCDC_HV_02,DCDC_IHEV,FCU_MLBevo_FCEV,Gateway,Gateway_PAG,Ladegeraet_2,Ladegeraet_Konzern,LE1,LE2,LE_MLBevo,Sub_Gateway

BO_ 1635 NVEM_02: 8 Gateway
 SG_ BEM_02_Abschaltstufen : 0|3@1+ (1.0,0.0) [0.0|7] ""  BMC_MLBevo,CBC,DCDC_800V_PAG,DCDC_HV,DCDC_HV_02,Ladegeraet_2,Ladegeraet_Konzern,TME
 SG_ BEM_STH_Zielzeit : 3|4@1+ (5,0) [0|60] "Unit_Minut"  TME
 SG_ BEM_MMI_Vorwarnung : 7|1@1+ (1.0,0.0) [0.0|1] ""  Vector__XXX
 SG_ NVEM_Anf_SD_schalten : 15|1@1+ (1.0,0.0) [0.0|1] ""  Vector__XXX
 SG_ BEM_Generatordiagnose : 16|2@1+ (1.0,0.0) [0.0|3] ""  Vector__XXX
 SG_ BEM_Red_Innengeblaese : 18|2@1+ (1.0,0.0) [0.0|3] ""  TME
 SG_ BEM_STH_Einschaltverbot : 20|1@1+ (1.0,0.0) [0.0|1] ""  TME
 SG_ BEM_HL_Regelung_Status : 21|3@1+ (1.0,0.0) [0.0|7] ""  Vector__XXX
 SG_ BEM_Ladezustand : 24|4@1+ (10,0) [0|100] "Unit_PerCent"  Vector__XXX
 SG_ BEM_Batteriediagnose : 28|3@1+ (1.0,0.0) [0.0|7] ""  Vector__XXX
 SG_ MIB_Stromsparmodus : 31|1@1+ (1.0,0.0) [0.0|1] ""  Vector__XXX
 SG_ BEM_REK_aktiv : 37|1@1+ (1.0,0.0) [0.0|1] ""  Vector__XXX
 SG_ NVEM_Last_Anf : 38|2@1+ (1.0,0.0) [0.0|3] ""  Vector__XXX
 SG_ BEM_UBDM : 40|8@1+ (0.05,5) [5.05|17.70] "Unit_Volt"  Ladegeraet_2,Ladegeraet_Konzern
 SG_ BEM_UGenSoll : 48|6@1+ (0.1,10.6) [10.6|16.0] "Unit_Volt"  Vector__XXX
 SG_ BEM_Anf_KL15_schalten : 54|2@1+ (1.0,0.0) [0.0|3] ""  Vector__XXX
 SG_ NVEM_Batterie_Service : 56|2@1+ (1.0,0.0) [0.0|3] ""  Vector__XXX
 SG_ NVEM_Freigabe_OnlineUpdate : 58|1@1+ (1.0,0.0) [0.0|1] ""  Vector__XXX
 SG_ NVEM_Freigabe_ORU4 : 59|2@1+ (1.0,0.0) [0.0|3] ""  Vector__XXX

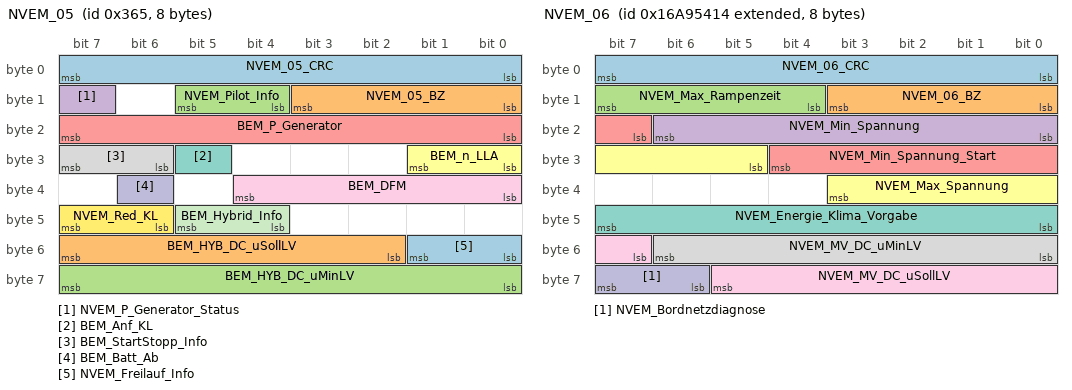
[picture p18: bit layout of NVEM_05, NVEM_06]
BO_ 869 NVEM_05: 8 Gateway
 SG_ NVEM_05_CRC : 0|8@1+ (1,0) [0|255] ""  Vector__XXX
 SG_ NVEM_05_BZ : 8|4@1+ (1,0) [0|15] ""  Vector__XXX
 SG_ NVEM_Pilot_Info : 12|2@1+ (1.0,0.0) [0.0|3] ""  Vector__XXX
 SG_ NVEM_P_Generator_Status : 15|1@1+ (1.0,0.0) [0.0|1] ""  Vector__XXX
 SG_ BEM_P_Generator : 16|8@1+ (50,0) [0|12700] "Unit_Watt"  Vector__XXX
 SG_ BEM_n_LLA : 24|2@1+ (1.0,0.0) [0.0|3] ""  Vector__XXX
 SG_ BEM_Anf_KL : 29|1@1+ (1.0,0.0) [0.0|1] ""  Vector__XXX
 SG_ BEM_StartStopp_Info : 30|2@1+ (1.0,0.0) [0.0|3] ""  Vector__XXX
 SG_ BEM_DFM : 32|5@1+ (3.225,0.025) [0.025|100.000] ""  Vector__XXX
 SG_ BEM_Batt_Ab : 38|1@1+ (1.0,0.0) [0.0|1] ""  CBC,DCDC_800V_PAG,DCDC_IHEV
 SG_ BEM_Hybrid_Info : 44|2@1+ (1.0,0.0) [0.0|3] ""  Vector__XXX
 SG_ NVEM_Red_KL : 46|2@1+ (1.0,0.0) [0.0|3] ""  TME
 SG_ NVEM_Freilauf_Info : 48|2@1+ (1.0,0.0) [0.0|3] ""  Vector__XXX
 SG_ BEM_HYB_DC_uSollLV : 50|6@1+ (0.1,10.6) [10.6|16.0] "Unit_Volt"  CBC,DCDC_800V_PAG,DCDC_HV,LE_MLBevo
 SG_ BEM_HYB_DC_uMinLV : 56|8@1+ (0.1,0) [0.0|25.3] "Unit_Volt"  Vector__XXX

BO_ 2527679508 NVEM_06: 8 Gateway
 SG_ NVEM_06_CRC : 0|8@1+ (1,0) [0|255] ""  Vector__XXX
 SG_ NVEM_06_BZ : 8|4@1+ (1,0) [0|15] ""  Vector__XXX
 SG_ NVEM_Max_Rampenzeit : 12|4@1+ (1.0,0.0) [0.0|15] ""  Vector__XXX
 SG_ NVEM_Min_Spannung : 16|7@1+ (0.05,10.6) [10.60|16.00] "Unit_Volt"  Vector__XXX
 SG_ NVEM_Min_Spannung_Start : 23|6@1+ (0.1,7) [7.0|13.1] "Unit_Volt"  BMS_NV
 SG_ NVEM_Max_Spannung : 29|7@1+ (0.05,10.6) [10.60|16.00] "Unit_Volt"  Vector__XXX
 SG_ NVEM_Energie_Klima_Vorgabe : 40|8@1+ (10,0) [0|2530] "Unit_WattHour"  Vector__XXX
 SG_ NVEM_MV_DC_uMinLV : 48|7@1+ (0.1,3.5) [3.5|16.0] "Unit_Volt"  DCDC_IHEV
 SG_ NVEM_MV_DC_uSollLV : 55|7@1+ (0.05,10.6) [10.60|16.00] "Unit_Volt"  DCDC_IHEV
 SG_ NVEM_Bordnetzdiagnose : 62|2@1+ (1.0,0.0) [0.0|3] ""  Vector__XXX

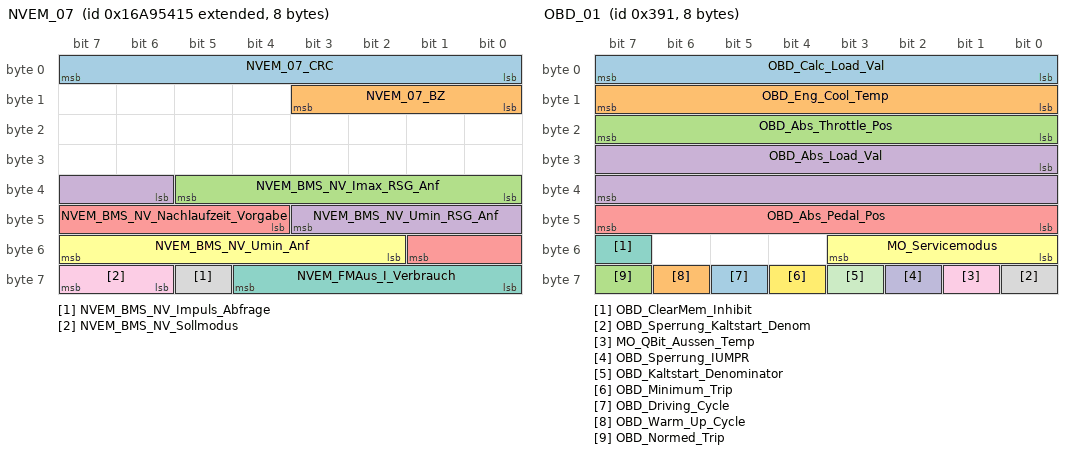
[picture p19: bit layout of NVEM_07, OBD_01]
BO_ 2527679509 NVEM_07: 8 Gateway
 SG_ NVEM_07_CRC : 0|8@1+ (1,0) [0|255] ""  BMS_NV
 SG_ NVEM_07_BZ : 8|4@1+ (1,0) [0|15] ""  BMS_NV
 SG_ NVEM_BMS_NV_Imax_RSG_Anf : 32|6@1+ (20,0) [0|1220] "Unit_Amper"  BMS_NV
 SG_ NVEM_BMS_NV_Umin_RSG_Anf : 38|6@1+ (0.1,7) [7.0|13.1] "Unit_Volt"  BMS_NV
 SG_ NVEM_BMS_NV_Nachlaufzeit_Vorgabe : 44|6@1+ (1,0) [0|60] "Unit_Minut"  BMS_NV
 SG_ NVEM_BMS_NV_Umin_Anf : 50|6@1+ (0.1,9) [9.0|15.1] "Unit_Volt"  BMS_NV
 SG_ NVEM_FMAus_I_Verbrauch : 56|5@1+ (5,0) [0|145] "Unit_Amper"  BMS_NV
 SG_ NVEM_BMS_NV_Impuls_Abfrage : 61|1@1+ (1.0,0.0) [0.0|1] ""  BMS_NV
 SG_ NVEM_BMS_NV_Sollmodus : 62|2@1+ (1.0,0.0) [0.0|3] ""  BMS_NV

BO_ 527 NVEM_10: 8 Gateway
 SG_ NVEM_MOD_Budget : 34|4@1+ (10,0) [0|100] "Unit_PerCent"  Vector__XXX
 SG_ NVEM_MOD_Freigabe : 38|2@1+ (1.0,0.0) [0.0|3] ""  Vector__XXX
 SG_ NVEM_DC_iSoll_NV : 48|8@1+ (1,-253) [-253|0] "Unit_Amper"  DCDC_HV
 SG_ NVEM_DC_uSoll_NV : 56|8@1+ (0.025,10.6) [10.600|16.000] "Unit_Volt"  DCDC_HV

BO_ 913 OBD_01: 8 Gateway
 SG_ OBD_Calc_Load_Val : 0|8@1+ (0.39215686274509803,0) [0E-17|99.99999999999999765] "Unit_PerCent"  BMC_MLBevo,BMS_MV,DCDC_HV,FCU_MLBevo_FCEV,Sub_Gateway,TME
 SG_ OBD_Eng_Cool_Temp : 8|8@1+ (1,-40) [-40|215] "Unit_DegreCelsi"  BMC_MLBevo,BMS_MV,DCDC_HV,FCU_MLBevo_FCEV,Sub_Gateway,TME
 SG_ OBD_Abs_Throttle_Pos : 16|8@1+ (0.39215686274509803,0) [0E-17|99.99999999999999765] "Unit_PerCent"  BMC_MLBevo,BMS_MV,DCDC_HV,FCU_MLBevo_FCEV,Sub_Gateway,TME
 SG_ OBD_Abs_Load_Val : 24|16@1+ (0.39215686274509803,0) [0E-17|25699.99999999999939605] "Unit_PerCent"  BMC_MLBevo,BMS_MV,DCDC_HV,FCU_MLBevo_FCEV,Sub_Gateway,TME
 SG_ OBD_Abs_Pedal_Pos : 40|8@1+ (0.39215686274509803,0) [0E-17|99.99999999999999765] "Unit_PerCent"  BMC_MLBevo,BMS_MV,DCDC_HV,FCU_MLBevo_FCEV,Sub_Gateway,TME
 SG_ MO_Servicemodus : 48|4@1+ (1.0,0.0) [0.0|15] ""  FCU_MLBevo_FCEV,Sub_Gateway
 SG_ OBD_ClearMem_Inhibit : 55|1@1+ (1.0,0.0) [0.0|1] ""  BMC_MLBevo,DCDC_HV,FCU_MLBevo_FCEV,Sub_Gateway,TME
 SG_ OBD_Sperrung_Kaltstart_Denom : 56|1@1+ (1.0,0.0) [0.0|1] ""  DCDC_HV,FCU_MLBevo_FCEV,Sub_Gateway,TME
 SG_ MO_QBit_Aussen_Temp : 57|1@1+ (1.0,0.0) [0.0|1] ""  BMC_MLBevo,FCU_MLBevo_FCEV,Ladegeraet_Konzern,Sub_Gateway,TME
 SG_ OBD_Sperrung_IUMPR : 58|1@1+ (1.0,0.0) [0.0|1] ""  BMC_MLBevo,BMS_MV,DCDC_HV,FCU_MLBevo_FCEV,Ladegeraet_2,Ladegeraet_Konzern,Sub_Gateway,TME
 SG_ OBD_Kaltstart_Denominator : 59|1@1+ (1.0,0.0) [0.0|1] ""  BMC_MLBevo,BMS_MV,DCDC_HV,FCU_MLBevo_FCEV,Sub_Gateway,TME
 SG_ OBD_Minimum_Trip : 60|1@1+ (1.0,0.0) [0.0|1] ""  BMC_MLBevo,BMS_MV,DCDC_HV,FCU_MLBevo_FCEV,Ladegeraet_2,Ladegeraet_Konzern,Sub_Gateway,TME
 SG_ OBD_Driving_Cycle : 61|1@1+ (1.0,0.0) [0.0|1] ""  BMC_MLBevo,BMS_MV,DCDC_HV,FCU_MLBevo_FCEV,Ladegeraet_2,Ladegeraet_Konzern,Sub_Gateway,TME
 SG_ OBD_Warm_Up_Cycle : 62|1@1+ (1.0,0.0) [0.0|1] ""  BMC_MLBevo,BMS_MV,CBC,DCDC_HV,DCDC_HV_02,DCDC_IHEV,FCU_MLBevo_FCEV,Ladegeraet_2,Ladegeraet_Konzern,Sub_Gateway,TME
 SG_ OBD_Normed_Trip : 63|1@1+ (1.0,0.0) [0.0|1] ""  BMC_MLBevo,BMS_MV,DCDC_HV,FCU_MLBevo_FCEV,Ladegeraet_2,Ladegeraet_Konzern,Sub_Gateway,TME

BO_ 2589283478 OBD_02: 8 Gateway
 SG_ OBD_Aussen_Temp_gef : 56|8@1+ (1,-40) [-40|213] "Unit_DegreCelsi"  Vector__XXX

BO_ 2549875343 OBDC_AWC_Req: 8 Gateway
 SG_ OBDC_AWC_Req_Data : 0|64@1+ (1.0,0.0) [0.0|18446744073709551615] ""  Vector__XXX

BO_ 2550006415 OBDC_AWC_Resp: 64 AWC
 SG_ OBDC_AWC_Resp_Data : 0|512@1+ (1.0,0.0) [0.0|13407807929942597099574024998205846127479365820592393377723561443721764030073546976801874298166903427690031858186486050853753882811946569946433649006084095] ""  Gateway,Gateway_PAG

BO_ 2549875374 OBDC_BattRegelung_Req: 8 Gateway
 SG_ OBDC_BattRegelung_Req_Data : 0|64@1+ (1.0,0.0) [0.0|18446744073709551615] ""  BMS_NV

BO_ 2550006446 OBDC_BattRegelung_Resp: 8 BMS_NV
 SG_ OBDC_BattRegelung_Resp_Data : 0|64@1+ (1.0,0.0) [0.0|18446744073709551615] ""  Gateway,Gateway_PAG

BO_ 2549875356 OBDC_BMS_48V_Req: 8 Gateway
 SG_ OBDC_BMS_48V_Req_Data : 0|64@1+ (1.0,0.0) [0.0|18446744073709551615] ""  BMS_MV

BO_ 2550006428 OBDC_BMS_48V_Resp: 8 BMS_MV
 SG_ OBDC_BMS_48V_Resp_Data : 0|64@1+ (1.0,0.0) [0.0|18446744073709551615] ""  Gateway,Gateway_PAG

BO_ 2549875399 OBDC_DCDC_HV_02_Req: 8 Gateway
 SG_ OBDC_DCDC_HV_02_Req_Data : 0|64@1+ (1,0) [0|18446744073709551615] ""  DCDC_HV_02

BO_ 2550006471 OBDC_DCDC_HV_02_Resp: 8 DCDC_HV_02
 SG_ OBDC_DCDC_HV_02_Resp_Data : 0|64@1+ (1,0) [0|18446744073709551615] ""  Gateway,Gateway_PAG

BO_ 2549875407 OBDC_DCDC_HV_03_Req: 8 Gateway
 SG_ OBDC_DCDC_HV_03_Req_Data : 0|64@1+ (1.0,0.0) [0.0|18446744073709551615] ""  FCU_MLBevo_FCEV

BO_ 2550006479 OBDC_DCDC_HV_03_Resp: 8 FCU_MLBevo_FCEV
 SG_ OBDC_DCDC_HV_03_Resp_Data : 0|64@1+ (1.0,0.0) [0.0|18446744073709551615] ""  Gateway

BO_ 2549875383 OBDC_DCDC_HV_Req: 8 Gateway
 SG_ OBDC_DCDC_HV_Req_Data : 0|64@1+ (1.0,0.0) [0.0|18446744073709551615] ""  CBC,DCDC_800V_PAG,DCDC_HV

BO_ 2550006455 OBDC_DCDC_HV_Resp: 8 CBC
 SG_ OBDC_DCDC_HV_Resp_Data : 0|64@1+ (1,0) [0|18446744073709551615] "Unit_None"  Gateway,Gateway_PAG

BO_ 2549875265 OBDC_DCDC_Req: 8 Gateway
 SG_ OBDC_DCDC_Req_Data : 0|64@1+ (1.0,0.0) [0.0|18446744073709551615] ""  DCDC_IHEV

BO_ 2550006337 OBDC_DCDC_Resp: 8 DCDC_IHEV
 SG_ OBDC_DCDC_Resp_Data : 0|64@1+ (1.0,0.0) [0.0|18446744073709551615] ""  Gateway,Gateway_PAG

BO_ 2549875381 OBDC_FCU_Req: 8 Gateway
 SG_ OBDC_FCU_Req_Data : 0|64@1+ (1.0,0.0) [0.0|18446744073709551615] ""  FCU_MLBevo_FCEV

BO_ 2550006453 OBDC_FCU_Resp: 8 FCU_MLBevo_FCEV
 SG_ OBDC_FCU_Resp_Data : 0|64@1+ (1.0,0.0) [0.0|18446744073709551615] ""  Gateway

BO_ 2549940736 OBDC_Funktionaler_Req_All: 8 Gateway
 SG_ OBDC_Funktionaler_Req_All_Data : 0|64@1+ (1.0,0.0) [0.0|18446744073709551615] ""  BMC_MLBevo,BMS_MV,BMS_NV,CBC,DCDC_800V_PAG,DCDC_HV,DCDC_HV_02,DCDC_IHEV,FCU_MLBevo_FCEV,Ladegeraet_2,Ladegeraet_Konzern,TME

BO_ 2549875323 OBDC_Hybrid_01_Req: 8 Gateway
 SG_ OBDC_Hybrid_01_Req_Data : 0|64@1+ (1.0,0.0) [0.0|18446744073709551615] ""  BMC_MLBevo

BO_ 2550006395 OBDC_Hybrid_01_Resp: 8 BMC_MLBevo
 SG_ OBDC_Hybrid_01_Resp_Data : 0|64@1+ (1.0,0.0) [0.0|18446744073709551615] ""  Gateway,Gateway_PAG

BO_ 2549875398 OBDC_Ladegeraet_2_Req: 8 Gateway
 SG_ OBDC_Ladegeraet_2_Req_Data : 0|64@1+ (1,0) [0|18446744073709551615] ""  Ladegeraet_2

BO_ 2550006470 OBDC_Ladegeraet_2_Resp: 8 Ladegeraet_2
 SG_ OBDC_Ladegeraet_2_Resp_Data : 0|64@1+ (1,0) [0|18446744073709551615] ""  Gateway,Gateway_PAG

BO_ 2549875268 OBDC_Ladegeraet_Req: 8 Gateway
 SG_ OBDC_Ladegeraet_Req_Data : 0|64@1+ (1.0,0.0) [0.0|18446744073709551615] ""  Ladegeraet_Konzern

BO_ 2550006340 OBDC_Ladegeraet_Resp: 8 Ladegeraet_Konzern
 SG_ OBDC_Ladegeraet_Resp_Data : 0|64@1+ (1.0,0.0) [0.0|18446744073709551615] ""  Gateway,Gateway_PAG

BO_ 2549903568 OBDC_SSN_BJB_Req: 8 Gateway
 SG_ OBDC_SSN_BJB_Req_Data : 0|64@1+ (1.0,0.0) [0.0|18446744073709551615] ""  BMC_MLBevo

BO_ 2550034640 OBDC_SSN_BJB_Resp: 8 BMC_MLBevo
 SG_ OBDC_SSN_BJB_Resp_Data : 0|64@1+ (1.0,0.0) [0.0|18446744073709551615] ""  Gateway,Gateway_PAG

BO_ 2549903569 OBDC_SSN_CMC_01_Req: 8 Gateway
 SG_ OBDC_SSN_CMC_01_Req_Data : 0|64@1+ (1.0,0.0) [0.0|18446744073709551615] ""  BMC_MLBevo

BO_ 2550034641 OBDC_SSN_CMC_01_Resp: 8 BMC_MLBevo
 SG_ OBDC_SSN_CMC_01_Resp_Data : 0|64@1+ (1.0,0.0) [0.0|18446744073709551615] ""  Gateway,Gateway_PAG

BO_ 2549903570 OBDC_SSN_CMC_02_Req: 8 Gateway
 SG_ OBDC_SSN_CMC_02_Req_Data : 0|64@1+ (1.0,0.0) [0.0|18446744073709551615] ""  BMC_MLBevo

BO_ 2550034642 OBDC_SSN_CMC_02_Resp: 8 BMC_MLBevo
 SG_ OBDC_SSN_CMC_02_Resp_Data : 0|64@1+ (1.0,0.0) [0.0|18446744073709551615] ""  Gateway,Gateway_PAG

BO_ 2549903571 OBDC_SSN_CMC_03_Req: 8 Gateway
 SG_ OBDC_SSN_CMC_03_Req_Data : 0|64@1+ (1.0,0.0) [0.0|18446744073709551615] ""  BMC_MLBevo

BO_ 2550034643 OBDC_SSN_CMC_03_Resp: 8 BMC_MLBevo
 SG_ OBDC_SSN_CMC_03_Resp_Data : 0|64@1+ (1.0,0.0) [0.0|18446744073709551615] ""  Gateway,Gateway_PAG

BO_ 2549903572 OBDC_SSN_CMC_04_Req: 8 Gateway
 SG_ OBDC_SSN_CMC_04_Req_Data : 0|64@1+ (1.0,0.0) [0.0|18446744073709551615] ""  BMC_MLBevo

BO_TX_BU_ 160 :Gateway,Gateway_PAG;
BO_TX_BU_ 1600 :Gateway,Gateway_PAG;
BO_TX_BU_ 1607 :Gateway,Gateway_PAG;
BO_TX_BU_ 168 :Gateway,Gateway_PAG;
BO_TX_BU_ 958 :Gateway,Gateway_PAG;
BO_TX_BU_ 812 :Gateway,Gateway_PAG;
BO_TX_BU_ 1648 :Gateway,Gateway_PAG;
BO_TX_BU_ 289 :Gateway,Gateway_PAG;
BO_TX_BU_ 1423 :Gateway,Gateway_PAG;
BO_TX_BU_ 967 :Gateway,Gateway_PAG;
BO_TX_BU_ 340 :Gateway,Gateway_PAG;
BO_TX_BU_ 1366 :Gateway,Gateway_PAG;
BO_TX_BU_ 283 :Gateway,Gateway_PAG;
BO_TX_BU_ 2527679581 :Gateway,Gateway_PAG;
BO_TX_BU_ 377 :Gateway,Gateway_PAG;
BO_TX_BU_ 2331595979 :Gateway,Gateway_PAG;
BO_TX_BU_ 2527679913 :Gateway,Gateway_PAG;
BO_TX_BU_ 1601 :Gateway,Gateway_PAG;
BO_TX_BU_ 305 :Gateway,Gateway_PAG;
BO_TX_BU_ 394 :Gateway,Gateway_PAG;
BO_TX_BU_ 339 :Gateway,Gateway_PAG;
BO_TX_BU_ 931 :Gateway,Gateway_PAG;
BO_TX_BU_ 2589283456 :Gateway,Gateway_PAG;
BO_TX_BU_ 1284 :Gateway,Gateway_PAG;
BO_TX_BU_ 1157 :Gateway,Gateway_PAG;
BO_TX_BU_ 1158 :Gateway,Gateway_PAG;
BO_TX_BU_ 2589283496 :Gateway,Gateway_PAG;
BO_TX_BU_ 2600468663 :CBC,DCDC_800V_PAG,DCDC_HV;
BO_TX_BU_ 2600468496 :Gateway,Gateway_PAG;
BO_TX_BU_ 2600468483 :LE1,LE_MLBevo;
BO_TX_BU_ 1635 :Gateway,Gateway_PAG;
BO_TX_BU_ 869 :Gateway,Gateway_PAG;
BO_TX_BU_ 2527679508 :Gateway,Gateway_PAG;
BO_TX_BU_ 2527679509 :Gateway,Gateway_PAG;
BO_TX_BU_ 527 :Gateway,Gateway_PAG;
BO_TX_BU_ 913 :Gateway,Gateway_PAG;
BO_TX_BU_ 2589283478 :Gateway,Gateway_PAG;
BO_TX_BU_ 2549875343 :Gateway,Gateway_PAG;
BO_TX_BU_ 2549875374 :Gateway,Gateway_PAG;
BO_TX_BU_ 2549875356 :Gateway,Gateway_PAG;
BO_TX_BU_ 2549875399 :Gateway,Gateway_PAG;
BO_TX_BU_ 2549875383 :Gateway,Gateway_PAG;
BO_TX_BU_ 2550006455 :CBC,DCDC_800V_PAG,DCDC_HV;
BO_TX_BU_ 2549875265 :Gateway,Gateway_PAG;
BO_TX_BU_ 2549940736 :Gateway,Gateway_PAG;
BO_TX_BU_ 2549875323 :Gateway,Gateway_PAG;
BO_TX_BU_ 2549875398 :Gateway,Gateway_PAG;
BO_TX_BU_ 2549875268 :Gateway,Gateway_PAG;
BO_TX_BU_ 2549903568 :Gateway,Gateway_PAG;
BO_TX_BU_ 2549903569 :Gateway,Gateway_PAG;
BO_TX_BU_ 2549903570 :Gateway,Gateway_PAG;
BO_TX_BU_ 2549903571 :Gateway,Gateway_PAG;
BO_TX_BU_ 2549903572 :Gateway,Gateway_PAG;
CM_ BO_ 1600 "ab MQB mit QBit Höheneinfo und MO_Versionsinfo_02";
CM_ BO_ 168 "Teil 2 neue Momentenschnittstelle MLB";
CM_ BO_ 1648 "Kombischnittstelle";
CM_ BO_ 1423 "CAN-Botschaft";
CM_ BO_ 967 "MQB - vorher Motor_06 / Umbenennung wg. ID-Wechsel";
CM_ BO_ 1601 "ab MQB mit CRC-8";
CM_ BO_ 339 "CAN-Botschaft";
CM_ BO_ 2600468546 "CAN_NM_PDU MLBevo";
CM_ BO_ 1635 "DLC=8 ab D4 gültig";
CM_ BO_ 869 "ab MQB";
CM_ BO_ 2549940736 "VDC funktionaler Request auf CANHS";

CM_ SG_ 2589283481 LAD_KomponentenFehler_64 "Übertragung OBD relevanter Fehlerpfade vom Secondary zum Primary Steuergerät. 
Zuordnung der generischen Komponentenfehler muss zwischen Sender und Empfänger abgestimmt werden.";
CM_ SG_ 2589283481 LAD_KomponentenFehler_65 "Übertragung OBD relevanter Fehlerpfade vom Secondary zum Primary Steuergerät. 
Zuordnung der generischen Komponentenfehler muss zwischen Sender und Empfänger abgestimmt werden.";
CM_ SG_ 2589283481 LAD_KomponentenFehler_66 "Übertragung OBD relevanter Fehlerpfade vom Secondary zum Primary Steuergerät. 
Zuordnung der generischen Komponentenfehler muss zwischen Sender und Empfänger abgestimmt werden.";
CM_ SG_ 2589283481 LAD_KomponentenFehler_67 "Übertragung OBD relevanter Fehlerpfade vom Secondary zum Primary Steuergerät. 
Zuordnung der generischen Komponentenfehler muss zwischen Sender und Empfänger abgestimmt werden.";
CM_ SG_ 2589283481 LAD_KomponentenFehler_68 "Übertragung OBD relevanter Fehlerpfade vom Secondary zum Primary Steuergerät. 
Zuordnung der generischen Komponentenfehler muss zwischen Sender und Empfänger abgestimmt werden.";
CM_ SG_ 2589283481 LAD_KomponentenFehler_69 "Übertragung OBD relevanter Fehlerpfade vom Secondary zum Primary Steuergerät. 
Zuordnung der generischen Komponentenfehler muss zwischen Sender und Empfänger abgestimmt werden.";
CM_ SG_ 2589283481 LAD_KomponentenFehler_70 "Übertragung OBD relevanter Fehlerpfade vom Secondary zum Primary Steuergerät. 
Zuordnung der generischen Komponentenfehler muss zwischen Sender und Empfänger abgestimmt werden.";
CM_ SG_ 2589283481 LAD_KomponentenFehler_71 "Übertragung OBD relevanter Fehlerpfade vom Secondary zum Primary Steuergerät. 
Zuordnung der generischen Komponentenfehler muss zwischen Sender und Empfänger abgestimmt werden.";
CM_ SG_ 2589283481 LAD_KomponentenFehler_72 "Übertragung OBD relevanter Fehlerpfade vom Secondary zum Primary Steuergerät. 
Zuordnung der generischen Komponentenfehler muss zwischen Sender und Empfänger abgestimmt werden.";
CM_ SG_ 2589283481 LAD_KomponentenFehler_73 "Übertragung OBD relevanter Fehlerpfade vom Secondary zum Primary Steuergerät. 
Zuordnung der generischen Komponentenfehler muss zwischen Sender und Empfänger abgestimmt werden.";
CM_ SG_ 2589283481 LAD_KomponentenFehler_74 "Übertragung OBD relevanter Fehlerpfade vom Secondary zum Primary Steuergerät. 
Zuordnung der generischen Komponentenfehler muss zwischen Sender und Empfänger abgestimmt werden.";
CM_ SG_ 2589283481 LAD_KomponentenFehler_75 "Übertragung OBD relevanter Fehlerpfade vom Secondary zum Primary Steuergerät. 
Zuordnung der generischen Komponentenfehler muss zwischen Sender und Empfänger abgestimmt werden.";

CM_ SG_ 160 EPS_04_BZ "Botschaftszähler
Botschaft asynchron geroutet. Zählerwert kann springen.";
CM_ SG_ 160 EPS_04_CRC "Für MLB:
'Berechnung siehe Lastenheft 'Kommunikationsabsicherung für FlexRay und CAN''

Ab MQB und MLBevo:
'Berechnung siehe Lastenheft 'End-to-End Kommunikationsabsicherung''

Endwerte siehe Begleitdokument 'S-PDU Kennungsfolgen'";
CM_ SG_ 160 EPS_AWA_Status "beschreibt den Status der AWA-Funktion im EPS-Steuergerät. (Ausweich-Assistent)";
CM_ SG_ 160 EPS_FAS_Regelgroesse "Aktuelle Regelauslastung der STA/STP-Funktionsschnittstelle";
CM_ SG_ 160 EPS_FAS_VZ_Regelgroesse "Richtung der FAS Regelgröße";
CM_ SG_ 160 EPS_Lenkmoment_AbsReduz "Gibt den Absolutwert des aktuelle Handlenkmoment mit einer Auflösung von 0 ,62 Nm aus";
CM_ SG_ 160 EPS_Motormoment "Motornahes Motor-Sollmoment";
CM_ SG_ 160 EPS_QBit_Zahnstangen_Pos "beschreibt die Qualität/Vertrauenswürdigkeit der Zahnstangenposition";
CM_ SG_ 160 EPS_STA_Status "beschreibt den Status der STA-Funktion im EPS-Steuergerät. (Stauassistent)";
CM_ SG_ 160 EPS_Versorgungsspannung "Gibt die am Steuergerät anliegende Spannung aus.
";
CM_ SG_ 160 EPS_Versorgungsstatus "Erkennung Störung im Versorgungspfad
";
CM_ SG_ 160 EPS_VZ_Zahnstangenposition "Vorzeichen der Position/Verschiebung der Zahnstange bzgl. Lenkungsmitte
Vorzeichen:
(Fahreransicht: positiv = links von der Nullstellung des Lenkrades)
Nullstellung = +0mm";
CM_ SG_ 160 EPS_Zahnstangen_Pos "Position/Verschiebung der Zahnstange bzgl. Lenkungsmitte";

CM_ SG_ 1600 MO_Absperrventil_oeffnen "Signal an Klima-SG das Absperrrventil anzusteuern. Ab D4 auch 0x3 Ventil_schließen.

Im MQB wird hier der Soll-Status des Absperrventils ausgegeben.
Achtung: bei z. B. klemmendem Ventil entspricht das Signal nicht dem tatsächlichen Status!";
CM_ SG_ 1600 MO_aktives_Getriebeheizen "Information für Getriebe, ob ein Ventil für Getriebheizen angesteuert werden muss";
CM_ SG_ 1600 MO_Ansaugluft_Temp "In Fahrzeugen ohne Außentemperatur vom Kombi kann aus der Ansauglufttemperatur auf die Außentemperatur geschlossen werden. Beim SDI ist das mit einer gewissen Genauigkeit gegeben. Genutzt wird es vom ASG.";
CM_ SG_ 1600 MO_Getriebe_kuehlen "Anforderung Getriebekühlventilansteuerung";
CM_ SG_ 1600 MO_Heizungspumpenansteuerung "Anforderung Heizungspumpenansteuerung
MQB und Hybrid: Status der Heizungsunterstützungspumpe am MSG
";
CM_ SG_ 1600 MO_Hoeheninfo "Korrekturfaktor Höhe (1 entspricht 1013 mbar)";
CM_ SG_ 1600 MO_HYB_Fehler_HV_Netz "Im HV-Bordnetz ist fehlerbedingt kein generatorischer Betrieb möglich. Das 12V-Bordnetz wird über den DC/DC-Wandler allein aus der Traktionsbatterie gespeist. Um diesen Zustand möglichst lange aufrechterhalten zu können, sollten Komfort-Verbraucher abgesc";
CM_ SG_ 1600 MO_Kennfeldk "Die Kennfeldkühlung ist in diesem Fahrzeug verbaut und hat keinen Systemfehler";
CM_ SG_ 1600 MO_KL15_Abschaltempfehlung "Kessy Abschaltempfehlung nach Verlassen des Fahrzeugs";
CM_ SG_ 1600 MO_Kuehlmittel_Temp "Kuehlmitteltemperatur";
CM_ SG_ 1600 MO_Mom_Traegheit_02 "Massenträgheit (J) der Motors bzw. der Antriebsmaschinen in kgm².

Zur Berücksichtigung des E-Motor in Hybrid-Projekten:
in MLB-Projekten wird nur der J-Wert des Verbrennungsmotors und nicht der J-Wert des E-Motors berücksichtigt.
In MQB/MLBevo-Projek";
CM_ SG_ 1600 MO_Nachlaufzeit_Heizungspumpe "Nachlaufzeit für Heizungspumpe für Turboladerschutz";
CM_ SG_ 1600 MO_Oel_Temp "Realer Meßbereich ca. -40..150 Grad";
CM_ SG_ 1600 MO_QBit_Ansaugluft_Temp "
";
CM_ SG_ 1600 MO_QBit_Hoeheninfo "Qualifizierungsbit der Höheninfo. Gesetzt bei Ersatzwert, Init oder Fehler.";
CM_ SG_ 1600 MO_QBit_Kuehlmittel_Temp "
";
CM_ SG_ 1600 MO_SpannungsAnf "Forderung des Motor-SGs zur Spannungsanhebung";
CM_ SG_ 1600 MO_Versionsinfo_02 "Versioninformation vom Motor zur Steuerung bei inkompatiblen KMatrix-Änderung bzw. Einführung von neuen Funktionen, die in den Empfängern verriegelt werden müssen. Zu jedem Ereignis wird ein fixer Zählerstand zugeordnet, um dem Empfänger die funktionale Ä";

CM_ SG_ 1607 MO_CO2_Faktor "dynamischer Umrechnungsfaktor von l in CO2";
CM_ SG_ 1607 MO_E85_Sensor "Information über den E85 Gehalt (%-mass.) im Ottokraftstoff";
CM_ SG_ 1607 MO_Ethanol_Spuelhinweis "Hinweis das der Fahrer beim nächsten Tanken Ethanol armen Sprit tanken soll.";
CM_ SG_ 1607 MO_ITM_Kuehlmittel_Temp "Kuehlmitteltemperatur: Ersatzkühlmitteltemperatur für Motoren mit ITM (Thermomanagement)

ACHTUNG: Ab MQB wird in diesem Signal das Anzeigeplateau durch das MSG dargestellt!";
CM_ SG_ 1607 MO_Kraftstofffilter_Wasser "Für Schlechtkraftstoffländer wird das Wasserabscheidevolumen im Dieselkraftstofffilter mit einem  Wassersensor überwacht. Ist das Volumen erschöpft, erfolgt im Kombi eine entsprechende Anzeige.";
CM_ SG_ 1607 MO_MKB_01 "Motorkennbuchstabe 1";
CM_ SG_ 1607 MO_MKB_02 "Motorkennbuchstabe 2";
CM_ SG_ 1607 MO_MKB_03 "Motorkennbuchstabe 3";
CM_ SG_ 1607 MO_MKB_04 "Motorkennbuchstabe 4";
CM_ SG_ 1607 MO_MKB_MUX "Die vier Motorkennbuchstaben werden gemultiplext in MO_MKB übertragen. Das Signal MO_MKB_MUX stellt das Steuersignal für diesen Multiplexer dar.";
CM_ SG_ 1607 SCR_Akustik "Ansteuerung von Summer/Gong bei Aktivieren der SCR-Warnungen.
Bedienung des Signals nur bei Dieseln mit SCR-System. Andere senden Initwert.";
CM_ SG_ 1607 SCR_Anz_Motorstarts "Anzahl noch möglicher Motorstarts, wenn Reichweite = 0 ist
0..13 = Anzeige 'x mögliche Restarts'
14 = Eingeschränkte Fahrfunktion (z. Zt. Audi)
15 = keine Einschränkung (Anzeige Reichweite)
Bedienung des Signals nur bei Dieseln mit SCR-System.";
CM_ SG_ 1607 SCR_Inducement_Strategie "Art des Motor-Inducement-Konzepts. Abhängig von diesem Signal sind die Warntexte zwischen 'Kein Motorstart (in...km)' und 'eingeschränkte Fahrbarkeit (in ...km)' auszuwählen.";
CM_ SG_ 1607 SCR_Reichweite "Gesamtreichweite in km der aktuellen SCR-Tankfüllung, sofern die Reichweite kleiner 2400 km ist. Bei einer Reichweite größer 2400 km wird grundsätzlich der Initwert (32767) übertragen. Bedienung des Signals nur bei Dieseln mit SCR-System.";
CM_ SG_ 1607 SCR_Systemfehler "Ansteuerung Anzeige für SCR-Systemfehler";
CM_ SG_ 1607 SCR_Text "Warntext (z. B. in Kombination mit SCR Warnstufe und SCR-Systemfehler).
Bedienung des Signals nur bei Dieseln mit SCR-System. Andere senden Initwert.";
CM_ SG_ 1607 SCR_verbaut "Die SCR-Signale deren Initwert ungleich 0 sind, werden nur dann ausgewertet, wenn SCR_verbaut == 1 den Verbau des SCR Systems zeigt.";
CM_ SG_ 1607 SCR_Warnstufe_1 "Ansteuerung der SCR Füllstandswarnlampe (Stufe 1) (gelbe Lampe) SCR_Warnstufe_1 (Prio 2).
Bedienung des Signals nur bei Dieseln mit SCR-System. Andere senden Initwert.";
CM_ SG_ 1607 SCR_Warnstufe_2 "Ansteuerung der SCR Füllstandswarnlampe (Stufe 2) (Blinkbit für gelbe Lampe oder rote Lampe) SCR_Warnstufe_2 (Prio 1).
Bedienung des Signals nur bei Dieseln mit SCR-System. Andere senden Initwert.";

CM_ SG_ 168 MO_Drehzahl_01 "Im Fehlerfall wird die Motordrehzahl über die Nockenwellendrehzahl als Ersatzgrösse ausgegeben

Bei Parallelhybrid: Getriebeeingangsdrehzahl (=E-Maschinen Drehzahl)

Hinweis: 
Ehemaliger Fehlerwert 0xFFFF wird senderseitig nicht unterstützt. 
Diesen";
CM_ SG_ 168 MO_Mom_Begr_dyn "Einheitenloser Wert! Faktor in MO_Faktor_Momente (CAN V6.x) bzw. MO_Faktor_Momente_02 (CAN V7.x/V8.x) in Motor_Code_01 beachten!

Bei aktueller Drehzahl kurzfristig (ca. 100..200 ms) max. mögliches Moment (Summe aus Verbrennungsmotor und E-Motor), wird ";
CM_ SG_ 168 MO_Mom_Begr_stat "Einheitenloser Wert! Faktor in MO_Faktor_Momente (CAN V6.x) bzw. MO_Faktor_Momente_02 (CAN V7.x) in Motor_Code_01 beachten!

Bei aktueller Drehzahl quasistationär (nach ca. 3..5 s) max. mögliches Moment (Summe aus max. Moment des Verbrennungsmotors aus ";
CM_ SG_ 168 MO_Mom_neg_verfuegbar "Einheitenloser Wert! Faktor in MO_Faktor_Momente (CAN V6.x) bzw. MO_Faktor_Momente_02 (CAN V7.x) in Motor_Code_01 beachten!

Bei aktueller Drehzahl im nächsten Task (bei CAN-Übertragung z.B. 10ms) tatsächlich verfügbares negatives Moment (Summe aus Verl";
CM_ SG_ 168 MO_Momentenintegral_02 "100  %  entspricht volle Verfügbarkeit aktuell vorhanden. 0 % entspricht Integral bis Limit gefüllt, erhöhender Eingriff kann aktuell nicht berücksichtigt werden oder aufgrund eines Fehlers nicht verfügbar
";
CM_ SG_ 168 MO_QBit_Drehzahl_01 "AUDI D4: Zykluszeit: 10ms (siehe Zykluszeit schnell/Cycletime Fast)

Achtung:
Reduktion der Zykluszeit Motor_03 auf 10ms geplant.
Projektabhängig soll künftig mit 10ms gesendet werden.
Empfänger die in weiteren Konzern-Projekten eingesetzt werden müs";
CM_ SG_ 168 Motor_12_CRC "Für MLB:
'Berechnung siehe Lastenheft 'Kommunikationsabsicherung für FlexRay und CAN''

Ab MQB und MLBevo:
'Berechnung siehe Lastenheft 'End-to-End Kommunikationsabsicherung'

Endwerte siehe Begleitdokument 'S-PDU Kennungsfolgen'";

CM_ SG_ 958 MO_Aussp_Anlass "Das Signal zeigt an, ob die Wiederholstartsperre aktiv ist. D. h. eine Ansteuerung des Anlassers wird auch bei erfüllten Startvoraussetzungen (HS: Interlock betätigt bzw. AT: P/N eingelegt und Bremse betätigt) nicht erfolgen.";
CM_ SG_ 958 MO_BKV_Unterdruckwarnung "Über die Unterdruckwarnung signalisiert das MSG dem ESP, dass kein ausreichender Unterdruck für den BKV zur Verfügung gestellt werden kann.";
CM_ SG_ 958 MO_BLS "Ungefiltertes Rohsignal des Bremslichtschalters, nur wenn HW-Eingang bestückt und ausgewertet wird. Bei Motoren ohne genutzten HW-Eingang wird kein Ersatzwert (bspw. SW-Signal über CAN) ausgegeben!
Bei AUDI muss das Signal wg. Bremslichtfunktion immer be";
CM_ SG_ 958 MO_BMS_NV_Anf_stuetzen "Garantierte Unterstützung des Zusatzspeichers ist erforderlich. Zusatzspeicher muss an das Versorgungsnezt angebunden werden. ";
CM_ SG_ 958 MO_EKlKomLeiRed "Anforderung an die Klimasteuerung, die Leistungsaufnahme des E-Kompressors bei schlechtem SOC und in bestimmten Fahrsituationen zu begrenzen. (Das bereits bestehende Signal 'Klimakompressor aus' als stets umzusetzende Anforderung bleibt unverändert besteh";
CM_ SG_ 958 MO_Ext_E_Fahrt_aktiv "Funktionsrückmeldung zum erw. E-Fahr-Betrieb über Lampe/LED im E-Mode-Taster";
CM_ SG_ 958 MO_Fahrer_bremst "Redundante Bremsinformation vom Motor.

MLB:
AUDI D4: Zykluszeit: 10ms (siehe Zykluszeit schnell/Cycletime Fast)
Im AUDI B8 wird in diesem Bit der Wert der ESP-CAN-Information 'ESP_Fahrer_bremst' ausgegeben.

Achtung:
Reduktion der Zykluszeit Motor";
CM_ SG_ 958 MO_FMAus_aktiv "Das Signal gibt Rückmeldung ob Freilauf Motor aus aktiv ist. Beleibt auch 0km/h (unterhalb der StartStopp Schwelle) weiterhin aktiv.";
CM_ SG_ 958 MO_FMAus_Startvariante "Startvariante beim Motorstart aus der Freilauf-Motor-AUS Phase";
CM_ SG_ 958 MO_Freig_Anlass "Bit wird gesetzt, wenn der Motor beim Automatikstart gestartet werden darf (Motorstillstand, Emissionsmaßnahmen sind erfüllt).";
CM_ SG_ 958 MO_Freig_Reku "Empfehlung des Motor-SG's zur Spannungsabsenkung/-anhebung für den Rekuperationsbetrieb";
CM_ SG_ 958 MO_Freigabe_Segeln "Freigabebit des Segelbetriebs im Getriebe. Bedingt durch bestimmte Diagnosen und Adaptionen des MSGs, die nur im Schub möglich sind, darf nicht jede Schubphase für einen Segelbetrieb genutzt werden. Eine Freigabe bleibt auch außerhalb einer Schubphase bes";
CM_ SG_ 958 MO_Gangposition "MLB:
Stellung des Wählhebels in der Schaltgasse des Handschaltgetriebes.
MLBevo: 
Ausweitung der Bedienung auch auf Automatikgetriebe;
Routing des Signals GE_Fahrstufe: 
1. Position_R (dez. 6) auf MO_Gangposition: Gang_R (dez. 13) wegen Entfall Signa";
CM_ SG_ 958 MO_Handshake_STH "Es gilt: Signalspec MO_Handshake v1.0

Handshake zwischen MSG und STH. Wenn das MSG die EKP aufgrund einer STH-Anforderung ansteuert und kein Fehlereintrag bzgl. EKP/KPE/NDR vorliegt, wird das Bit gesetzt.";
CM_ SG_ 958 MO_HYB_Fahrbereitschaft "Signal steuert u.a. in der Lenkhilfe zusammen mit weiteren Informationen den Modewechsel in den 'Drivemode'
Grüne Anzeige im Kombiinstrument zur Signalisierung der Bereitschaft des Hybridsystems.";
CM_ SG_ 958 MO_HYB_VM_aktiv "0 = VMotor wird nicht aktiv gehalten (nVM < n_min und keine LL-Regelung aktiv)
1 = VMotor aktiv (ab der ersten Einspritzung; gilt auch für Schubbetrieb, wenn VMotor spätestens durch LLRegelung befeuert würde)
Verwendet zur Bestimmung des Ist-Zustandes";
CM_ SG_ 958 MO_Interlock "Das Motorsteuergerät gibt die Information aus, ab wann der Kupplungsschalter durch das Motorsteuergerät als getreten gesehen wird.
Bei Systemen für Start Stopp muss das Interlocksignal für einen Start durch das MSG generiert werden, sobald der Schalthebe";
CM_ SG_ 958 MO_Kickdown "Es gilt: Signalspec MO_Kickdown v1.0";
CM_ SG_ 958 MO_Kl_50 "Klemme 50: Startausführung durch Ritzelstarter

MLB: nicht von allen Motoren gesendet
MQB/MLBevo: gesendet von allen Motoren";
CM_ SG_ 958 MO_Kl_75 "Klemme X
";
CM_ SG_ 958 MO_Klima_Eingr "Eingriffe des Motor bei der Klima";
CM_ SG_ 958 MO_KomFehler_ESP "Anzeige Kommunikationsfehler bei Empfang vom ESP";
CM_ SG_ 958 MO_Konsistenz_Bremsped "MLB:

AUDI D4: Zykluszeit: 10ms (siehe Zykluszeit schnell/Cycletime Fast)
Siehe 'Funktionsspezifikation Bremslichtinfo B8'

Achtung:
Reduktion der Zykluszeit Motor_03 auf 10ms geplant.
Projektabhängig soll künftig mit 10ms gesendet werden.
Empfäng";
CM_ SG_ 958 MO_Kuppl_schalter "MLB:
Das Motorsteuergerät gibt die Information aus, ab wann der Kupplungsschalter durch das Motorsteuergerät als getreten gesehen wird
0x0: Schalter sagt betätigt (Ausgekuppelt)
0x1: Schalter sagt nicht betätigt (Eingekuppelt)

MQB:
Nur Handschalter";
CM_ SG_ 958 MO_Motor_laeuft "Das Motorsteuergerät gibt die Information aus, ab wann der Motor verbrennungsbedingt autark läuft und durch zuschaltbare Nebenaggregate mechanisch belastbar ist (z.B. durch Generator, Klimakompressor, etc.).

Die 'Motor läuft' Information wird ausgegebe";
CM_ SG_ 958 MO_PTC_Status "Status-Rückmeldung vom MSG zum aktuellen PTC-Status (stufiges PTC, Relais am MSG). Bei Ansteuerung eines stufigen PTC durch ein anderes SG beschreibt das Signal die vom MSG freigegebene PTC-Stufe.";
CM_ SG_ 958 MO_QBit_Fahrer_bremst "MLB:
AUDI D4: Zykluszeit: 10ms (siehe Zykluszeit schnell/Cycletime Fast)

Achtung:
Reduktion der Zykluszeit Motor_03 auf 10ms geplant.
Projektabhängig soll künftig mit 10ms gesendet werden.
Empfänger die in weiteren Konzern-Projekten eingesetzt werd";
CM_ SG_ 958 MO_QBit_Gangposition "Qualitätsbit zum Signal MO_Gangposition";
CM_ SG_ 958 MO_QBit_KL_75 "Q - Bit für das KL 75 Signal zur Vermeidung der fehlerhaften Erkennung von Motorstarts. 
Wird auf 1 gesetzt, solange das Motorsteuergerät KL15 = AUS erkannt hat.";
CM_ SG_ 958 MO_Remotestart_Betrieb "Das MSG ist für den Remotestart-Betrieb bereit. Nach Empfang der Motorstartanforderung für RSt-Betrieb durch BCM wird der Fahrzeugmotor gestartet und solange der Motor läuft, bleibt dieses Bit aktiv. Dieses Signal ist nur zur Verwendung durch das BCM zur ";
CM_ SG_ 958 MO_Remotestart_moeglich "Wenn Bit gesetzt, würde das MSG bei entsprechender Anforderung durch das BCM den Remotestartbetrieb einleiten, d.h. das MSG ist remotestartfähig und es liegen aktuell keine relevanten Fehler oder andere Abbruchgründe vor.";
CM_ SG_ 958 MO_Signalquelle_Gangposition "Signalquelle des Signals MO_Gangposition
0: Signalquelle Gangpositionssensor
1: Signalquelle Modellwert (v/n)";
CM_ SG_ 958 MO_StartStopp_Fahrerwunsch "Fahreraktivität Start/Stop";
CM_ SG_ 958 MO_StartStopp_Motorstopp "Motor-Stopp durch Start/Stopp-Koordinator
HYBRID:
Wenn MO_Hybridfahrzeug = 1 gilt:
Verbrennungsmotor durch Hybrid-Koordinator im MSG ausgeschaltet. 
Die definierten Start/Stopp-Signale beziehen sich nur auf den Verbrennungsmotor!";
CM_ SG_ 958 MO_StartStopp_Status "Aktivitätsstatus Start/Stopp-Koordinator
HYBRID:
Wenn MO_Hybridfahrzeug = 1 gilt:
Signal bezieht sich nur auf den Verbrennungsmotor, nicht auf den Hybridantrieb
";
CM_ SG_ 958 MO_StartStopp_Wiederstart "Motorwiederstart durch Start/Stopp-Koordinator
HYBRID:
Wenn MO_Hybridfahrzeug =1 gilt:
Warnung vor Spannungseinbruch beim Zustart des Verbrennungsmotors. 
-nicht relevant, da derzeit kein Start über 12V-Starter geplant-
Dieses Signal wird nur vom Hyb";
CM_ SG_ 958 MO_StartVorauss_erfuellt "Dient der Fallunterscheidung bei ZAT-Betätigung im Zustand 'KL15 ein' (bei nicht gesetztem Signal folgt KL15 aus, bei gesetztem Signal folgt setzen KL50-Anf.)

0: Signal nicht bedient 
1: Voraussetzungen zur Antriebsstrangaktivierung / Startvoraussetzu";
CM_ SG_ 958 MO_Text_Geschw_red "Anforderung an das Kombi die Textmeldung 'Geschwindigkeitsreduzierung' anzuzeigen";
CM_ SG_ 958 MO_Zylinderabschaltung "Status Zylinderabschaltung Motor";
CM_ SG_ 958 Motor_14_CRC "Ab MQB und MLBevo:
'Berechnung siehe Lastenheft 'End-to-End Kommunikationsabsicherung'

Endwerte siehe Begleitdokument 'S-PDU Kennungsfolgen'";

CM_ SG_ 812 MO_BZS_Charisma_FahrPr "Rückmeldung des aktuellen Charisma-Fahrprogramms der MSG Betriebsstrategie

MLBevo: Aktuelles Fahrprogramm des Charisma-Teilnehmers (siehe Systemlastenheft Drive Select)
MQB: Istwert der Kennlinie (siehe Systemlastenheft MQB FPA)";
CM_ SG_ 812 MO_BZS_Charisma_Status "Charisma Systemstatus des Charisma-Teilnehmers MSG (Betriebszustände)

Wert 0x3 ist nur für Fahrzeuge ab MQB relevant";
CM_ SG_ 812 MO_Charisma_FahrPr "MLBevo: Aktuelles Fahrprogramm des Charisma-Teilnehmers (siehe Systemlastenheft Drive Select)
MQB: Istwert der Kennlinie (siehe Systemlastenheft MQB FPA)";
CM_ SG_ 812 MO_Charisma_Status "Charisma Systemstatus des Charisma-Teilnehmers

Wert 0x3 ist nur für Fahrzeuge ab MQB relevant";
CM_ SG_ 812 MO_Drehzahlbeeinflussung "Faktor zur Anhebung der Fahrdrehzahl im Warmlauf";
CM_ SG_ 812 MO_Luftpfad_aktiv "Getriebeeingriff wird zusätzlich zum Zündungspfad auch über den Luftpfad umgesetzt, kommt zu MLB neu in die PL48-Getriebe";
CM_ SG_ 812 MO_MAX_Wunschdrehzahl "maximale Motorwunschdrehzahl, die vom Getriebe nicht überschritten werden darf

Signal darf GE_Synchro_Wunschdrehzahl nicht spiegeln";
CM_ SG_ 812 MO_MIN_Wunschdrehzahl "minimale Motorwunschdrehzahl aufgrund Regeneration, die vom Getriebe nicht unterschritten werden darf

Hinweis: 
Ehemaliger Fehlerwert 0xFF wird senderseitig nicht unterstützt. 
Diesen Wert aus Kompatibilitätsgründen nicht neu belegen!";
CM_ SG_ 812 MO_NGS_Position "Messwert des Neutralgangsensors
(nur Handschalter)";
CM_ SG_ 812 MO_NGS_Status "Status des Signals MO_NGS_Position. Das MSG prüft die Plausibilität nur hinsichtlich sicher geöffnetem Triebstrang.";
CM_ SG_ 812 MO_Prio_MAX_Wunschdrehzahl "Prioritätsbit der Motorwunschdrehzahl  als MAX";
CM_ SG_ 812 MO_Prio_MIN_Wunschdrehzahl "Prioritätsbit der Motorwunschdrehzahl als MIN";
CM_ SG_ 812 MO_Rampenzeit_Generator_Anf "Das Motorsteuergerät kann eine Load-Response-Zeit des Generators vom Niedervoltenergiemanagement (NVEM) anfordern. Die Load-Response-Zeit wird vom NVEM umgesetzt, wenn dies bordnetzverträglich möglich ist.";
CM_ SG_ 812 MO_Sperrung_FahrPr_BZS "Sperrung einzelner Betriebszustände bzgl. Kommunikation zwischen Motor-SG und Charisma-SG (Gateway)";
CM_ SG_ 812 MO_StSt_Charisma_FahrPr "MLBevo: Aktuelles Fahrprogramm des Charisma-Teilnehmers (siehe Systemlastenheft Drive Select)
MQB: Istwert der Kennlinie (siehe Systemlastenheft MQB FPA)";
CM_ SG_ 812 MO_StSt_Charisma_Status "Charisma Systemstatus des Charisma-Teilnehmers

Wert 0x3 ist nur für Fahrzeuge ab MQB relevant";
CM_ SG_ 812 MO_v_Begrenz_Aktivierbar "Fehlerbit wird vom Motor-SG gesetzt, wenn dieses nicht in dieGeschwindigkeits-begrenzung gehen kann, ein Fehler während der v-Begrenzung auftritt oder v > v_Begrenzung - v_Delta";
CM_ SG_ 812 MO_v_Begrenzung_Niveau "Zeigt an, ob eine v-Begrenzung aufgrund Anforderung der Niveauregelung  im MSG aktiv ist oder nicht (Signal für Niveau zum Steuern der Kombianzeige).";

CM_ SG_ 1648 MO1_Freigabe_Info_WFS "WFS-Freigabeinformation";
CM_ SG_ 1648 MO1_Freigabe_Verfallsinfo_WFS "WFS-Freigabeverfallsinformation";
CM_ SG_ 1648 MO1_Sperr_Info_WFS "WFS-Sperrinformation";
CM_ SG_ 1648 MO_Abstellzeit "Abstelldauer nach letztem KL15 aus

Hinweis: 
Ehemaliger Fehlerwert 0xFF wird senderseitig nicht unterstützt. 
Diesen Wert aus Kompatibilitätsgründen nicht neu belegen!";
CM_ SG_ 1648 MO_Abstellzeit_Status "Statusinformation zur Abstellzeit
0: Die dem Status zugeordnete Variable konnte noch nicht berechnet werden. 
1: Die dem Status zugehörige Variable wurde korrekt berechnet. 
2: Der Wert der zugehörigen Variablen ist nur ein Minimalwert. 
3: Der Wert d";
CM_ SG_ 1648 MO_ANC_Kennfeld_Anf "Anforderung ANC Kennfeldumschaltung";
CM_ SG_ 1648 MO_Anzahl_Abgesch_Zyl "Gibt die Anzahl der abgeschalteten Zylinder an. In Übergangszuständen wird der Zielbetriebszustand angezeigt.";
CM_ SG_ 1648 MO_Bremslicht_Reku "Bremslicht (ggf. bei Rekuperation durch E-Motor) wird angesteuert";
CM_ SG_ 1648 MO_Drehzahl_Warnung "Warnhinweis zum Kombi im Fall einer fehlerbehafteten Drehzahlbegrenzung";
CM_ SG_ 1648 MO_EPCL "Die Anforderung der EPC-Lampe vom MSG ans Kombi soll durch das Bus-Signal MO_EPCL gemäß folgender Logik erfolgen:
MO_EPCL = 0 dez -> EPC Lampe aus, kein Text
MO_EPCL = 1 dez -> gelbe EPC-Symbolik, Text „Antrieb: Störung! Bitte Service aufsuchen“
MO_EPC";
CM_ SG_ 1648 MO_Ethanol_BS_Texte "Ethanol Brennstoff-Texte im Kombi

0 = kein Text
1 = E85 Warm_Up
2 = FlexFuel Warnung 3.Stufe (Too cold for ethanol)
3 = Warmfahrempfehlung MQB / FlexFuel Warnung 1.Stufe (Refuel with gasoline)
4 = FlexFuel Warnung 2. Stufe (Refuel with gasoline)
5";
CM_ SG_ 1648 MO_Fahrzeugtyp "Unterscheidet die Fahrzeugtypen bzgl. der Antriebsart";
CM_ SG_ 1648 MO_Fehler_Zylabsch "Fehlerstatus der Funktion Zylinderabschaltung ";
CM_ SG_ 1648 MO_Hybrid_StartStopp_LED "Ansteuerung der Funktions-LED der Hybrid Taste bzw. Start/Stop Deaktivierungstaste.
Der Start/Stopp-Master (derzeit im MSG) (oder ein künftiger Hybrid-Master) soll die Ansteuerung senden.";
CM_ SG_ 1648 MO_max_Ladedruck "maximal möglicher Ladedruck (zur Anpassung des Anzeigebereichs bei absoluter Ladedruckanzeige)";
CM_ SG_ 1648 MO_NMAX_Schaltanzeige "Maximaldrehzahl für Schaltanzeige";
CM_ SG_ 1648 MO_obere_Drehzahlgrenze "obere Drehzahlgrenze des Motors";
CM_ SG_ 1648 MO_StartStopp_PopUp "Das Signal zeigt an, ob der StSt-Status mittels Deaktivierungstaster geändert wurde. Ein Wechsel auf die Werte 01 oder 10 löst im Kombi ein entsprechendes PopUp aus. Bei einem Statuswechsel durch andere Signalquellen (z.B. Charisma, fehlerbedingte Abschal";
CM_ SG_ 1648 MO_Zylabsch_Texte "Zylinderabschaltung mode in Kombi, fuer Zylinderabschaltung";
CM_ SG_ 1648 MO_Zylabsch_Texte_02 "ZAS-Anzeige für den Fahrer im Kombi
0: kein ZAS (generell keinerlei ZAS-Anzeigen)  (Init für nicht ZAS-Motor)
1: ZAS im Vollmotorbetrieb  (Init für ZAS-Motor)
2: ZAS im Abschaltbetrieb: 1 Zyl aktiv
3: ZAS im Abschaltbetrieb: 2 Zyl aktiv
4: ZAS im Abs";

CM_ SG_ 289 MO_Entkopplung_Sollschlupf "MSG fordert von GSG an, das Anfahrelement (Fahr-/Wandlerkupplung) zu entkoppeln; das GSG soll die gesendete Drehzahl als Schlupf einstellen und ggf. die Regler-Parameter umschalten, damit Rucke aus dem Antrieb nicht im Fahrzeug spürbar werden; nutzbar z.B";
CM_ SG_ 289 MO_Fahrpedalgradient "Das Motorsteuergerät besitzt 2 analoge Fahrpedalsignale. Das Signal des ersten Kanals wird alle 4ms abgetastet. Um Bitschwankungen des A/D-Wandler herauszufiltern wird das Signal entjittert. Anschließend wird der Gradient berechnet. Entsprechend der Zyklu";
CM_ SG_ 289 MO_Fahrpedalrohwert_01 "AUDI D4: Zykluszeit: 10ms (siehe Zykluszeit schnell/Cycletime Fast)

Stellung des Fahrpedales (Rohwert, ohne Überlagerung durch GRA-Eingriffe etc.)

Die Funktionen zur Berechung des Fahrpedalrohwerts laufen im 10ms Raster. Der Fahrpedalwert berechnet ";
CM_ SG_ 289 MO_Moment_im_Leerlauf "Fahrerwunschmoment ist minimal: keine Momentenanforderung durch Fahrpedal, ACC oder GRA+; (Das Signal ist unabhängig von Momentenerhöhungen durch Leerlaufregler oder MSR).

AUDI D4: Zykluszeit: 10ms (siehe Zykluszeit schnell/Cycletime Fast)

Achtung:";
CM_ SG_ 289 MO_QBit_Fahrpedalwerte_01 "AUDI D4: Zykluszeit: 10ms (siehe Zykluszeit schnell/Cycletime Fast)

QBit für beide Fahrpedalwerte des Motors (Fahrpedalrohsignal für ESP, EPB, ACC; Fahrpedalwert für Getriebe)

Achtung:
Reduktion der Zykluszeit Motor_03 auf 10ms geplant.
Projektabh";
CM_ SG_ 289 MO_rel_Saugrohrdruck "Der Wert gibt an, um wieviel mbar der Saugrohrdruck unterhalb des Umgebungsdrucks liegt. Überdruck im Saugrohr wird nicht ausgegeben.
0: Saugrohrdruck=Umgebungsdruck";
CM_ SG_ 289 MO_rel_Saugrohrdruck_gem_err "0: mind. eine Modellrechnung wird zur Berechnung des relativen Saugdrucks herangezogen
1: Relativer Saugrohrdruck wird ausschließlich über Messgrößen bestimmt";
CM_ SG_ 289 MO_Schubabschaltung "ESP plausibilisiert Unterdrucksensor nur bei aktiver Schubabschaltung

MLBevo:
Signal wird nur in MLBevo Projekten mit PDKII Getriebe bedient. In allen anderen MLBevo Projekten wird das Signal mit '0' bedient
PDKII berücksichtigt Verzugszeiten, die in";
CM_ SG_ 289 MO_Sig_Fahrpedalgradient "Kennzeichnet das Vorzeichen des Signal 'Fahrpedalgradient'. Die Ausgabe erfolgt nur parallel statisch mit gesendetem Signal: 'Steuerungsbit Fahrpedalgradient' ";
CM_ SG_ 289 MO_Solldrehz_Leerlauf "Leerlaufsolldrehzahl, die im Motor eingestellt ist (Bei Parallelhybrid im E-Fahr-Betrieb Leerlaufsolldrehzahl der E-Maschine). Der Motor paßt aufgrund der Anforderung von anderen Steuergeräten seine Leerlaufsolldrehzahl an, bspw. Kat-Heizen, Anforderung v";
CM_ SG_ 289 MO_StartStopp_StoppVorbereitung "Zeigt allen aktiven Start-/Stoppteilnehmern einen möglichen Motorstopp im Anhaltevorgang an (Empfänger notwendige Vorbereitungen treffen)
Es liegen keine Vetos vor.";
CM_ SG_ 289 MO_temporaere_Fahrerabwesenheit "Das Signal dient zur Signalisierung einer temporären Abwesenheit des Fahrers. In dieser Zeit ist es ihm möglich, sich durch gewisse ¿ im Verlassenskonzept definierte ¿ Fahreraktionen im aktuellen Fahrzyklus zurückzumelden.
Das Signal wird gesetzt, sobald";
CM_ SG_ 289 Motor_20_BZ "Botschaft asynchron geroutet. Zählerwert kann springen.";
CM_ SG_ 289 Motor_20_CRC "Für MLB:
'Berechnung siehe Lastenheft 'Kommunikationsabsicherung für FlexRay und CAN''

Ab MQB und MLBevo:
'Berechnung siehe Lastenheft 'End-to-End Kommunikationsabsicherung'

Endwerte siehe Begleitdokument 'S-PDU Kennungsfolgen'";
CM_ SG_ 289 TSK_a_Soll_gradientenbegrenzt "TSK Sollbeschleunigung für Fahrerassistenzsysteme mit aktiver Längsführung (GRA, ACC, IPA...). Der Wert stellt den ruckbegrenzten Sollwert der TSK-Regelung dar und ist Basis der TSK-Antriebs- und Bremsmomentenvorsteuerung.";

CM_ SG_ 1423 FSA_Fehlerpfade_Initialisieren "Aktivierung der Fehlerpfad-Initialisierung  beim FSP Löschen ueber Mode04";
CM_ SG_ 1423 MO_FSA_Sensorheizung "Aktivierung Sensorheizung FSA";
CM_ SG_ 1423 MO_Getriebe_Oelalterung "Prozentualer Alterungswert Getriebeöl";
CM_ SG_ 1423 MO_ITM_Status "Statusinformationen an TME-Steuergerät bzgl. Thermomanagement";
CM_ SG_ 1423 MO_KJS_LLK_Pos_Summe "Aerodynamisch wirksamer Gesamtöffnungswinkel aller Kühlerlüfter- und LLK-Jalousiesteller.

Pos_Frontendverschl_ungenau = 15 zeigt eine Fehlfunktion bzw. unbekannte Position einer oder mehrere Jalousiesteller an.";
CM_ SG_ 1423 MO_Kuehlmittel_Temp_Rohwert "Rohwert Kuehlmitteltemperatur
Das Signal wird derzeit von Diesel-Projekten nicht bedient.";
CM_ SG_ 1423 MO_MMTR_Status "Status des Antriebs zur Funktion Make me track ready";
CM_ SG_ 1423 MO_Oel_Temp_Radsatz "Öltemperatur in PDK Radsatz ";
CM_ SG_ 1423 MO_SABody_PosLe "Öffnungswinkel der Linke Front Diffusor 
(0%= geschlossen, 100% =volle Kühlung)";
CM_ SG_ 1423 MO_SABody_PosRi "Öffnungswinkel der Rechte Front Diffusor 
(0%= geschlossen, 100% =volle Kühlung)";
CM_ SG_ 1423 MO_Tankdruck "Tank Über-/Unterdruck wird für Ansteuerintensität der Treibstoffpumpe der Standheizung benötigt.";

CM_ SG_ 967 MO_E_Mode "Anforderung der E-Mode Statusanzeige";
CM_ SG_ 967 MO_E_Texte "Anforderung von Hinweistexten des E-Systems separat für HEV/BEV bzw. erweiterbar für PHEV";
CM_ SG_ 967 MO_E_Warnungen "Anforderung von Warnanzeigen des E-Systems separat für HEV/BEV bzw. erweiterbar für PHEV";
CM_ SG_ 967 MO_EFLEX_Lampe "Um ein Starten mit E100 zu ermöglichen, wird Kraftstoff ggf. vorgeheizt. Das Signal dient der Anzeige des Heizungsstatus.

Heizung aus -> Lampe aus
Heizung ein -> Lampe ein
Heizung ein und Startversuch -> Lampe blinkend
Heizung nicht möglich -> Lampe";
CM_ SG_ 967 MO_Heissleuchte "Ansteuerung der Kühlwassertemperatur-Heißleuchte (Sensor nur noch am Motorsteuergerät): Temperaturschaltschwellen mit Hysterese (bei VW D1/Colorado Kombi derzeit noch nicht genutzt).";
CM_ SG_ 967 MO_ITM_Warnung_Pumpe "Textanzeige: 'Motor sofort abstellen, geschaltete Wasserpumpe defekt / klemmt'";
CM_ SG_ 967 MO_KJS_nicht_bereit "Dieses Signal zeigen einen Fehler der Kühlerjalousie mit unbekannter Stellung der Lamellen. ";
CM_ SG_ 967 MO_Kuehlerluefter_1 "Ansteuertastverhaeltnis (PWM) der Kuehlerluefterendstufe 1";
CM_ SG_ 967 MO_Kuehlerluefter_2 "Ansteuertastverhaeltnis (PWM) der Kuehlerluefterendstufe 2";
CM_ SG_ 967 MO_Kuehlerluefter_MUX "Multiplexer für das Signal 'MO_Kuehlerlüfter'";
CM_ SG_ 967 MO_OBD2_Lampe "OBD bzw. MIL-Lampe wird vom Motorsteuergerät angesteuert, die Information im Signal GE_OBD_Status wird vom Motorsteuergerät an das Kombi weitergereicht";
CM_ SG_ 967 MO_Oelwarnung_max "Ölstandswarnung mit der Aufforderung zum Ölwechsel.
Hintergrund: Bei Kraftstoffeintrag (B20) ins Öl verbleibt der RME-Anteil irreversibel im Öl.";
CM_ SG_ 967 MO_Partikel_Lampe "Partikelfilter-Lampe wird eingeschaltet";
CM_ SG_ 967 MO_RedFahrleistung_Lampe "Ansteuerung der Turtle-Mode Lampe für E-Traktion Fahrzeuge";
CM_ SG_ 967 MO_Systemlampe "EGas Systemlampe (EPC) oder Vorglühlampe im Kombi, Kombi steuert immer gleiche
LED an, nur über Ziffernblatt wird die EPC von der Vorglühlampe differenziert";
CM_ SG_ 967 MO_Tankdeckel_Lampe "Ansteuerung Tankdeckel-Warnlampe Kombiinstrument (nur Ottomotoren) z.Zt. Vorhalt VW";
CM_ SG_ 967 MO_Text_Motorstart "Anzeigetexte für Start/Stopp und Motor-Start
0xB Fehler_Kupplungsschalter nur für PAG-MLB";
CM_ SG_ 967 MO_Text_Partikelfil_Reg "Über dieses Bit im Kombi wird ein Klartextanzeige erzeugt werden: 'Partikelfilter benötigt Regeneration'.
";
CM_ SG_ 967 MO_Text_Tankdeckelwarn "Textbit der Tankdeckelwarnung, z.Zt. Vorhalt VW";
CM_ SG_ 967 MO_Vorglueh_Lampe "Vorglühlampe im Kombi, Kombi steuert immer gleiche LED an. 
Mit Einführung des Einheits-Kombis sind getrennte Signalwege für Vorglühlampe und EPCL notwendig.";
CM_ SG_ 967 MO_Zustand_HWP "Rückmeldung des  Ansteuerzustand der Hauptwasserpumpe an das Klima-SG .
Der Zustand 'HWP fördert' wird übermittelt, wenn die Schaufeln der Hauptwasserpumpe frei drehen können und die Motordrehzahl und damit die Wasserpumpendrehzahl größer als Null ist. B";
CM_ SG_ 967 OLEV_Oelstand_nicht_vorhanden "Kein aktueller Ölstand vorhanden";
CM_ SG_ 967 OLEV_Systemstoerung "Systemstörung im Ölsystem";
CM_ SG_ 967 WIV_Anzeige_aktiv "Peilstabsanzeigefunktion aktiv";
CM_ SG_ 967 WIV_laufender_Motor "Messung bei laufendem Motor nicht möglich";
CM_ SG_ 967 WIV_nachfuellanzeige_ein "Steuert das Aufblenden der Nachfüllanzeige im Kombi, nach Klemme 15 ein und geöffneter Motorhaube";
CM_ SG_ 967 WIV_nicht_betriebswarm "Motor nicht betriebswarm, Messung ungenau";
CM_ SG_ 967 WIV_Oeldr_Warn_Motor "Löst im Kombiinstrument die rote Prio1-Öldruckwarnung (inkl. 3xBeep) aus.
nur MLB: die Warnauslösung erfolgt nur bei gleichzeitig gesetztem 'WIV_Enable_Oeldr_Motor'";
CM_ SG_ 967 WIV_Oeldyn_avl "Ölstand aus dynamischer Messung vorhanden";
CM_ SG_ 967 WIV_Oelmenge "Ölmenge zwischen Min und Max";
CM_ SG_ 967 WIV_Oelmin_Warn "Signal gibt an wenn der Ölstand die Min-Schwelle unterschritten hat";
CM_ SG_ 967 WIV_Oelstand "8 Segmente zur Balkenanzeige des Ölstands";
CM_ SG_ 967 WIV_Oelstand_nicht_vorhanden "Kein aktueller Ölstand vorhanden";
CM_ SG_ 967 WIV_Oelsystem_aktiv "Gesamtölsystem aktiv (entspricht Ölsensor verbaut) und das Ölstand-Untermenu im MMI aktiv";
CM_ SG_ 967 WIV_Schieflage "Fahrzeug steht nicht waagerecht, Messung ungenau";
CM_ SG_ 967 WIV_Sensorfehler "Ölstand/Öltemperatursensor (TOG) defekt";
CM_ SG_ 967 WIV_Ueberfuell_deaktiv "Unterdrückung der Warnung im Kombi die durch Signal WIV_Ueberfuel_Warn ausgelöst wird";
CM_ SG_ 967 WIV_Ueberfuell_Warn "Ölstand hat die Überfüllschwelle überschritten";
CM_ SG_ 967 WIV_Unterfuell_Warn "Ölstand hat die Unterfüllschwelle unterschritten";

CM_ SG_ 340 MO_Drehzahl_VM "Motordrehzahl des Verbrennungsmotors

für OBD freeze frame

Hinweis: 
Ehemaliger Fehlerwert 0xFFFF wird senderseitig nicht unterstützt. 
Diesen Wert aus Kompatibilitätsgründen nicht neu belegen!";
CM_ SG_ 340 MO_Fehlerstatus_Antrieb_FDR "Fehlerstatus Antrieb - FDR";
CM_ SG_ 340 MO_IstMoment_VKM "Ist-Moment des Verbrennungsmotors

einheitenloser Wert! MO_Faktor_Momente_02 in Motor_Code_01 berücksichtigen!";
CM_ SG_ 340 MO_Mom_Begr_Schalt "Einheitenloser Wert! Faktor in MO_Faktor_Momente (CAN V6.x) bzw. MO_Faktor_Momente_02 (CAN V7.x/8.x) in Motor_Code_01 beachten!

Bei aktueller Drehzahl kurzfristig (ca. 100..200 ms) für momentenerhöhende Getriebeeingriffe max. zur Verfügung stehendes Ge";
CM_ SG_ 340 MO_Mom_Begr_Schalt_Min "Bei aktueller Drehzahl im nächsten Task (im VKM Umsetzung zur nächsten möglichen Verbrennung) minmal stellbares Moment (Summe aus Verbrennungsmotor und E-Motor) aufgrund Momenten-Reduzierungs-Anforderung durch reduzierenden Getriebeeingriff.
Berücksichti";
CM_ SG_ 340 MO_Primaerachse_Anforderung "Das Signal dient der Steuerung der Primärachse. 

Anforderung zum Öffnen/Schließen der Getriebekupplungen und damit An-/Abkuppeln der Primärachse. 
Wird in MHEV-Projekten keine explizite Anforderung gesendet (Wert 0), ist die Freilaufsteuerung aus 'MO_";
CM_ SG_ 340 Motor_28_BZ "Botschaft asynchron geroutet. Zählerwert kann springen.";
CM_ SG_ 340 Motor_28_CRC "Für MLB:
'Berechnung siehe Lastenheft 'Kommunikationsabsicherung für FlexRay und CAN''

Ab MQB und MLBevo:
'Berechnung siehe Lastenheft 'End-to-End Kommunikationsabsicherung''

Endwerte siehe Begleitdokument 'S-PDU Kennungsfolgen'";

CM_ SG_ 1366 FWS_Koeffizient_2 "Von der quadratischen Geschwindigkeit abhängiger Fahrwiderstandsanteil. Details zum Signal siehe Dokument zur Signalbeschreibung";
CM_ SG_ 1366 FWS_QBit_Koeffizient_2 "Qualitätsbit zu FWS_Koeffizient_2.
Nähere Beschreibung siehe Dokument zur Signalbeschreibung";
CM_ SG_ 1366 MO_Fahrzeugabstellzeit "Zeit seit letzter Fahrbereitschaft.";
CM_ SG_ 1366 MO_Fahrzeugabstellzeit_Status "Status Fahrzeugabstellzeit";
CM_ SG_ 1366 MO_HV_Auszeit "Zeit seit letzter Hochvoltaktivität.";
CM_ SG_ 1366 MO_HV_Auszeit_Status "Status HV-Auszeit.";
CM_ SG_ 1366 MO_Oelstand_Sens_roh "Rohwert des Ölstands-Sensors in mm";
CM_ SG_ 1366 MO_Verbau_StartSys_EM_HV "Signal zeigt an, welche Komponenten des Startsystemes verbaut sind.
Verbau E-Maschine HV";
CM_ SG_ 1366 MO_Verbau_StartSys_EM_MV "Signal zeigt an, welche Komponenten des Startsystemes verbaut sind.
Verbau E-Maschine MV z.B. 48V";
CM_ SG_ 1366 MO_Verbau_StartSys_Q_Diode "Signal zeigt an, welche Komponenten des Startsystemes verbaut sind.
Verbau Q_Diode";
CM_ SG_ 1366 MO_Verbau_StartSys_Ritzelstarter "Signal zeigt an, welche Komponenten des Startsystemes verbaut sind.
Verbau Ritzel Starter";
CM_ SG_ 1366 MO_Verbau_StartSys_RSG_MV "Signal zeigt an, welche Komponenten des Startsystemes verbaut sind.
Verbau Riemen Starter Generator MV z.B. 48V";
CM_ SG_ 1366 MO_Verbau_StartSys_RSG_NV "Signal zeigt an, welche Komponenten des Startsystemes verbaut sind.
Verbau Riemen Starter Generator NV z.B. 12V";
CM_ SG_ 1366 MO_Ziel_SoC_Fremdladung "Auf diesen SoC soll MHEV-Speicher geladen werden, wenn ein Ladegerät erkannt ist.";

CM_ SG_ 283 MO_AIAD_MaxLeistung "Maximal zulässige Leistung, die das PDCC einzustellen hat.";
CM_ SG_ 283 MO_EBoost_verf_praed "Zeigt an, ob für eine im Projekt definierte Zeit (max. 10s) E-Boost in Höhe von EM1_maxPred_Moment verfügbar sein wird.

0 - Init_oder_nicht_verfügbar
1 - EBoost_kurzzeit_verfügbar (~3Sek.)
2 - EBoost_langzeit_verfügbar (~10Sek)";
CM_ SG_ 283 MO_eLaunch_verf "Zeigt an, ob aus Antriebssicht E-Launch verfügbar ist.";
CM_ SG_ 283 MO_Fahrbereitschaft "Das Signal MO_Fahrbereitschaft zeigt in mehreren Stufen an, ob der Motor in einem anfahrbereiten Zustand ist.";
CM_ SG_ 283 MO_Freilauf_Info "Freilauf Informationssignal vom Motorsteuergerät zum Getriebesteuergerät. Das Motorsteuergerät kann über dieses Signal den Freilauf freigeben, verhindern bzw. explizit anfordern.";
CM_ SG_ 283 MO_Freilauf_Status "Freilauf-Status-Signal vom Frailauf-Master an aktive Freilauf-Teilnehmer. In diesem Signal zeigt der Freilauf-Master an, welchen aktuellen Status die Freilauf-Betriebsstrategie hat.";
CM_ SG_ 283 MO_Heckspoiler_Anf "Anforderung den Heckspoiler zur Ladeluft- bzw. Motorraumkühlung auszufahren.";
CM_ SG_ 283 MO_Krit_Heckobjekt "Beschreibt die Kritikalität des hinter einem in der Spur fahrenden Fahrzeuges";
CM_ SG_ 283 MO_NGS_Gangpos "Gang- bzw. Neutralinformation des erweiterten Neutralgangsensors. Bedingt durch den eingeschränkten Erfassungssbereich des Sensors sind die Ganginformationen als eingelegt bzw. fast eingelegt/vorausgewählt zu interpretieren (nur Handschalter)";
CM_ SG_ 283 MO_Parken_WFS_Status "Gesammelte Rückmeldung des Limitierungsstatus aller EM in einem vom ZFAS angeforderten Parkvorgang.";
CM_ SG_ 283 MO_Positionierung_aktiv "Zeigt an, dass die Motorpositionierung mit Hilfe des Riemenstartergenerator momentan aktiv ist.";
CM_ SG_ 283 MO_Rennstart_verf "Zeigt an, ob aus Antriebssicht ein Rennstart verfügbar ist.";
CM_ SG_ 283 MO_Status_Katheizen "Status des Katheizen.

0 = Katheizen nicht aktiv
1 = Katheizen aktiv";
CM_ SG_ 283 MO_Status_MIN_Wunschdrehzahl "In 2.0 TFSI Motorprojekten EA888 Gen3 und EA888 EVO4 im MLBevo (AU536 und AU49x, in allen anderen Projekten ist das Signal nicht zu implementieren) wird das Bus Signal MO_MIN_Wunschdrehzahl verwendet, um durch eine damit angepasste Gangwahl des Getriebes ";

CM_ SG_ 2527679581 MO_Abwurfschwelle_Charge "Signalisiert den Offset auf das Signal BMS_SOC_Max bei dem der Charge-Mode von der BS abgeworfen wird";
CM_ SG_ 2527679581 MO_Abwurfschwelle_EV "Signalisiert den Offset auf das Signal BMS_SOC_Kaltstart bei dem der EV-Mode von der BS abgeworfen wird";
CM_ SG_ 2527679581 MO_Anf_KJS_1 "Ansteuersollwert  Kühlerjalousie (motoreigene Bedarfe)";
CM_ SG_ 2527679581 MO_Hysterese_Reakt_Charge "Signalisiert die Hysterese auf die MO_Abwurfschwelle_Charge ab welcher der Charge-Mode wieder reaktiviert werden kann";
CM_ SG_ 2527679581 MO_Hysterese_Reakt_EV "Signalisiert die Hysterese auf die MO_Abwurfschwelle_EV ab welcher der EV-Mode wieder reaktiviert werden kann";
CM_ SG_ 2527679581 MO_TME_KL_Anf "Lüfteranforderung DME->TME.
Max-Auswahl aus TME Lüfteranforderung + SKE positionsabhängiger Offset.";

CM_ SG_ 377 ElCatCtl_StOpm "Ist-Betriebsmodus eKat";
CM_ SG_ 377 MO_ElCat_ErrAcvDcha "Status zur aktiven Entladeeinheit im eKAT-SG";
CM_ SG_ 377 MO_ElCat_StTestOpWire "Fehler Offene Leitung Ekat";
CM_ SG_ 377 MO_Soll_NutzbarerSOC "Der Sollwert für den Kunden-Nutzbaren-SOC bei einer SOC-steuernden Betriebsstrategie";

CM_ SG_ 2331595979 MO_eATL1_eATL_SollVolumenstrom "Für die Kühlung des eATL_1 aktuell mindestens benötigter Kühlwasservolumenstrom";
CM_ SG_ 2331595979 MO_eATL1_HVK_Fehler_AE "eATL1 Fehler in der aktiven Entladung";
CM_ SG_ 2331595979 MO_eATL2_eATL_SollVolumenstrom "Für die Kühlung des eATL_2 aktuell mindestens benötigter Kühlwasservolumenstrom";
CM_ SG_ 2331595979 MO_eATL2_HVK_Fehler_AE "eATL2 Fehler in der aktiven Entladung";
CM_ SG_ 2331595979 MO_ElCat_HVK_EoHVL_Status "Status Erkennung offener HV_Leitung an der HV-Komponente eKAT

Signale kommen vom SubCAN 1 ElCat_HVK_EoHVL_Status";
CM_ SG_ 2331595979 MO_EM_MaxDyn_Ladespannung "Prädiziertes Spannungsniveau, das unter Belastung mit dem systembedingt tatsächlich maximal realisierbaren Ladestrom nicht überschritten wird";
CM_ SG_ 2331595979 MO_EM_MinDyn_Entladespannung "Prädiziertes Spannungsniveau, das unter Belastung mit dem systembedingt tatsächlich maximal realisierbaren Entladestrom nicht unterschritten wird";
CM_ SG_ 2331595979 MO_Status_Kaltabfahrbegrenzung "Status der Kaltabfahrbegrenzung. VoKo entspricht Vorkonditionierungsphase";

CM_ SG_ 2589283599 MO_CatHeatBar_LB "Cat heating progress bar";
CM_ SG_ 2589283599 MO_Eboost_LB_active "LB eboost activation status";
CM_ SG_ 2589283599 MO_Eboost_LB_available "LB eboost is available in the actual DM/PS";
CM_ SG_ 2589283599 MO_Eboost_LB_driveraction "LB eboost driver advice";
CM_ SG_ 2589283599 MO_Eboost_LB_failure "LB eboost functionality failure";
CM_ SG_ 2589283599 MO_Eboost_LB_LVLavailable "LB eboost levels available";
CM_ SG_ 2589283599 MO_Eboost_LB_LVLselected "LB eboost level selected";
CM_ SG_ 2589283599 MO_Eboost_LB_possible "LB eboost is avaialbe in the actual DM/PS and possible based on system status";
CM_ SG_ 2589283599 MO_Kilometerstand_Wakeup "Odometer value sent at wake-up";
CM_ SG_ 2589283599 MO_Nachlaufzeit_Kuehlerluefter_2 "Nachlaufzeit Kühlerlüfter 2 MSG für Verwendung im TME SG";
CM_ SG_ 2589283599 MO_Status_KL "Diagnose_nicht_durchgefuehrt
Lüfter_iO
Diagnose_laeuft
Lüfter_iO_Diagnose_laeuft
Lüfter_Notlauf
Lüfter_Fehler";
CM_ SG_ 2589283599 MO_TME_KL_Anf_LB "Intercooler cooling request";

CM_ SG_ 2527679913 MO_AGB_EntlueftenHT "Motorfreigabe AGB Ventil zur Entlüftung HT-Kreis";
CM_ SG_ 2527679913 MO_AGB_EntlueftenNT "Motorfreigabe AGB Ventil zur Entlüftung NT-Kreis";
CM_ SG_ 2527679913 MO_AGB_HVBHeizen "Motorfreigabe AGB Ventil zum HVB-Heizen";
CM_ SG_ 2527679913 MO_eATL1_Temperatur_PWR "Aktuelle Temperatur PWR eATL_1";
CM_ SG_ 2527679913 MO_eATL1_Verlustleistung "Aktuelle Verlustleistung PWR eATL1";
CM_ SG_ 2527679913 MO_eATL2_Temperatur_PWR "Aktuelle Temperatur PWR eATL_2";
CM_ SG_ 2527679913 MO_eATL2_Verlustleistung "Aktuelle Verlustleistung PWR eATL2";
CM_ SG_ 2527679913 MO_eATL_Nachlaufkuehlung "Information über den Bedarf der Kühlung der eATL-PWRs, nach Motor aus";
CM_ SG_ 2527679913 MO_ElCat_FlgWarnOvT "Warnung Uebertemperatur
Signal von SubCAN1: ElCat_FlgWarnOvT";
CM_ SG_ 2527679913 MO_ElCat_Verlustleistung "Verlustleistung eKAT-SG, berechnet im MotorSG";
CM_ SG_ 2527679913 MO_HVEM_HV_Anf "Motor Anforderung für HV-Nachlauf";

CM_ SG_ 1601 MO_Ansaugsystem "Art des Ansaugsystems des Verbrennungsmotors";
CM_ SG_ 1601 MO_Anzahl_Zyl "Zylinderzahl des Verbrennungsmotors";
CM_ SG_ 1601 MO_Anzeige_StSt_gueltig "Zeigt die Gültigkeit der neuen StSt-Anzeigesignale an, MO_Anzeige_StSt_Text und  MO_Anzeige_Symbol. Mo_Text_Motorstart 1..5 sind zu ignorieren.";
CM_ SG_ 1601 MO_Code "Motorcodierinformation Version 16 (Details siehe Anhang)";
CM_ SG_ 1601 MO_DPF_verbaut "Verbauinformation Diesel-Partikel-Filter
";
CM_ SG_ 1601 MO_Faktor_Momente_02 "Dieses Signal schaltet den Wertebereich aller Momente vom Motor, Getriebe, TSK, Bremse ... um! Die Momente besitzen somit einen variablen Wertebereich, weil sich durch den Faktor die Momente sowohl in Auflösung als auch Maximalwerten ändert.

0x0 nicht ";
CM_ SG_ 1601 MO_Getriebe_Code "Getriebecodierung des Motors";
CM_ SG_ 1601 MO_Hubraum "Hubraum des Verbrennungsmotors";
CM_ SG_ 1601 MO_Hybridfahrzeug "Anhand dieses Signals plausibilisiert die Lenkhilfe das Bit Fahrbereitschaft.

Im Projekt Cayenne PHEV (und ggf. auch VW526 PHEV) ist aus Gründen der Abwärtskompatibilität der Wert '2' zu senden.";
CM_ SG_ 1601 MO_Kraftstoffart "Primärkraftstoff zum Antrieb des Fahrzeugs";
CM_ SG_ 1601 MO_Leistung "Nennleistung des Verbrennungsmotors

Im reinen E-Fahrzeug (BEV): Ausgabe der elektrischen Systemleistung";
CM_ SG_ 1601 MO_OBD_Typ "Abgastyp OBD
Hinweis: In Fahrzeugen mit dem Zielmarkt China und einer Zertifizierung ab China 6 muss auf dem Signal 'MO_OBD_Typ' der Wert 'US_OBD' gesendet werden.";
CM_ SG_ 1601 MO_StartStopp_Codiert "Funktion StartStopp im aktuellen Klemmenzyklus verbaut";
CM_ SG_ 1601 Motor_Code_01_CRC "Für MLB:
'Berechnung siehe Lastenheft 'Kommunikationsabsicherung für FlexRay und CAN''

Ab MQB und MLBevo:
'Berechnung siehe Lastenheft 'End-to-End Kommunikationsabsicherung''

Endwerte siehe Begleitdokument 'S-PDU Kennungsfolgen'";
CM_ SG_ 1601 TSK_Codierung "Information über den plausibilisierten Codierungszustand des Triebstrangskoordinators auf ACC oder GRA.";

CM_ SG_ 220 MO_FCU_SollLeistung "Sollleistung der Brennstoffzelle zur Einspeisung ins Traktonsnetz (Netto)
Netto=Nebenaggregateleistung nicht enthalten";
CM_ SG_ 220 MO_FCU_SollModus "Sollmodus für Brennstoffzellensystem";

CM_ SG_ 2463978654 MO_FCU_Betriebspunkt_Ist "Status zur Betriebspunkt-Anforderung des Brennstofzellensystems an die Betriebsstrategie";
CM_ SG_ 2463978654 MO_FCU_MaxLeistung "Maximale zulässige Leistung (netto) die das Brennstoffzellensystem in Traktionsnetz liefern darf
Netto=Ohne HV-Nebenaggregate";
CM_ SG_ 2463978654 MO_FCU_MinLeistung "Minimal zulässige Leistung die das Brennstoffzellensystem aus Traktionsnetz aufnehmen darf. Netto=Ohne HV-Nebenaggregate";
CM_ SG_ 2463978654 MO_MaxStrom_Sekundaerkreis "Maximal zulässiger Strom des Brennstoffzellensystems Richtung Traktionsnetz";
CM_ SG_ 2463978654 MO_TME_Senkenleistung_Soll "Senkleistung die über das TME im Load-Dump aufgenommen werden soll";

CM_ SG_ 305 Ladezustand_02 "Aktueller relativer Ladezustand der HV-Batterie
";
CM_ SG_ 305 MO_ePerformance "Zeigt die elektrische Leistungreserve bei BEV und PHEV Projekten an.
Bei Init und Fehler soll keine Anzeige erfolgen. ";
CM_ SG_ 305 MO_ePowermeter "Anzeige ePowermeter (Fahrreserve elektrisch bis Start Verbrennungsmotor (Verbrenner startet bei 100%))";
CM_ SG_ 305 MO_Powermeter "Anzeigewerte im Kombi
0       = Unteres Ende Bremsen/grau;
340   = Unteres Ende CHARGE;
1020 = READY;
1870 = Oberes Ende EFFICIENCY;
3400 = 100%;
4080 = MAX;";
CM_ SG_ 305 MO_Powermeter_Elm "Die Prozentwerte ergeben sich aus dem momentanen Moment der E-Maschine bezogen auf das im aktuellen Arbeitspunkt maximal mögliche Moment der E-Maschine (generatorisch = negativ / motorisch = positiv )";
CM_ SG_ 305 MO_Powermeter_Elm_02 "relatives Moment / relative Leistung der elektrischen Maschine";
CM_ SG_ 305 MO_Zust_Antrieb "Signalisiert die Zuordnung der Antriebsverbräuche zu den Antriebsmaschinen für die Restreichweitenberechnung, nicht gleichbedeutend mit Motorlauf EM oder VM bzw. Brennstoffzelle";
CM_ SG_ 305 MO_Zust_Betriebsstrategie "Signalisiert den aktuellen Zustand der Betriebsstrategie";

CM_ SG_ 394 MO_Ablaufstatus "aktueller Status bezüglich der Ausführung des Sollzustand

detaillierte Beschreibung der einzelnen Übergänge ist in der aktuellsten Version des Lastenhefts 'Funktionslastenheft Betriebsartenkoordination bei elektrifizierten Fahrzeugen_Vxx' zu entnehmen";
CM_ SG_ 394 MO_Ablaufstrg_Betriebszustand "Istzustand Betriebsbereitschaft

1 = Betriebsbereitschaft bedeutet: Alle Komponenten sind betriebsbereit. Fahrzeug kann kein Vortriebsmoment erzeugen.

2 = Fahrbetrieb bedeutet: Fahrzeug kann Vortriebsmoment erzeugen.";
CM_ SG_ 394 MO_Ablaufstrg_Kraftschluss2_Ist "Istzustand des Kraftschlusses der Sekundärachse in der Hybridablaufsteuerung (z.B. el. Hinterachse im B9 eQuattro).
Dieses Signal entspricht nicht einem physikalischen Zustand, sondern den Istzustand der Ablaufsteuerung.

Das Signal darf nur ausgwertet";
CM_ SG_ 394 MO_Ablaufstrg_Kraftschluss2_Ziel "Zielstatus des Kraftschlusses der Sekundärachse in der Hybridablaufsteuerung (z.B. el. Hinterachse im B9 eQuattro).
Mit dem Bit soll das Getriebe Kraftschluss herstellen oder den Kraftschluss unterbrechen.

Das Signal darf nur ausgwertet werden, wenn '";
CM_ SG_ 394 MO_Ablaufstrg_Kraftschluss_Ist "Istzustand des Kraftschlusses in der Hybridablaufsteuerung.
Dieses Signal entspricht nicht einem physikalischen Zustand, sondern den Istzustand der Ablaufsteuerung.

Das Signal darf nur ausgwertet werden, wenn 'MO_Ablaufstrg_Betriebszustand' eine Betri";
CM_ SG_ 394 MO_Ablaufstrg_Kraftschluss_Ziel "Zielstatus des Kraftschlusses in der Hybridablaufsteuerung.
Mit dem Bit soll das Getriebe Kraftschluss herstellen oder den Kraftschluss unterbrechen.

Das Signal darf nur ausgwertet werden, wenn 'MO_Ablaufstrg_Betriebszustand' eine Betriebsbereitschaft";
CM_ SG_ 394 MO_Ablaufstrg_Zustand_K0_Ist "Iststatus der K0 Kupplung in der Hybridablaufsteuerung.
Dieses Signal entspricht nicht einem physikalischen Zustand, sondern den Istzustand der Ablaufsteuerung.

Das Signal darf nur ausgwertet werden, wenn 'MO_Ablaufstrg_Betriebszustand' eine Betriebsb";
CM_ SG_ 394 MO_Ablaufstrg_Zustand_K0_Ziel "Zielstatus der K0 Kupplung in der Hybridablaufsteuerung
K0 Steuerung im Motorsteuergerät:
- Infobit an das Getriebe, dass K0 jetzt geschlossen wird
K0 Steuerung durch anderes Steuergerät:
- Bit um dem anderen SG mitzuteilen, dass dieses die K0 schlies";
CM_ SG_ 394 MO_Ablaufstrg_Zustand_VKM_Ist "Istzustand VKM
Dieses Signal entspricht nicht einem physikalischen Zustand, sondern den Istzustand der Ablaufsteuerung.

Das Signal darf nur ausgewertet werden, wenn 'MO_Ablaufstrg_Betriebszustand' eine Betriebsbereitschaft signalisiert.";
CM_ SG_ 394 MO_Ablaufstrg_Zustand_VKM_Ziel "Zielzustand VKM
Dieses Signal entspricht nicht einem physikalischen Zustand, sondern den Zielzustand der Ablaufsteuerung.

Das Signal darf nur ausgewertet werden, wenn 'MO_Ablaufstrg_Betriebszustand' eine Betriebsbereitschaft signalisiert.";
CM_ SG_ 394 MO_Abstellposition_02 "Winkelabstand (in °KW) des sog. Zielzylinders von seinem ZOT (bspw. nötig um Startmoment bei Schleppstart zu berechnen)

255 = Abstellposition kann nicht genau bestimmt werden (bspw. Rückdrehen des Motors)";
CM_ SG_ 394 MO_Auth_Aufforderung_WFS "WFS-Anforderung für Hybridumfänge";
CM_ SG_ 394 MO_HYB_Adaption_aktiv "Motor fordert Sondermaßnahmen vom Getriebe PDK2 (gültig nur für Hybridprojekte)
Das Signal wird im PDKII dazu verwendet, die Fahrkupplungen bei einem Momentenadaptionswunsch der K0-Trennkupplung nicht zu befüllen";
CM_ SG_ 394 MO_HYB_E_Faktor "Signed Nibble, verwendet vom GSG zur Interpolation zwischen VMKennfeld und dem Rekuperations-Grenzkennfeld (negative Werte des E-Faktors) bzw. dem Boost-Grenzkennfeld (positive Werte des E-Faktors).
0000 = VM-Kennfeld (keine Interpolation)
0001..0111 = ";
CM_ SG_ 394 MO_HYB_EMode_Info "Hybrid-Mode der Motorsteuerung zur Beeinflussung der Schaltkennfelder im Getriebe. Nicht-Hybridfahrzeuge senden den Initwert.";
CM_ SG_ 394 MO_HYB_LowSpeedModus "MSG legt fest:
0 = klassisches Ausrollen/Anfahren mit N_mot >= N_Leerlauf_VM
1 = elektr. Ausrollen/Anfahren mit geschl. Triebstrang mit N_mot < N_Leerlauf_VM";
CM_ SG_ 394 MO_HYB_Stoppmodus "Hybridsteuerung zeigt an, auf welche Weise gestoppt werden soll.";
CM_ SG_ 394 MO_Mom_Freiheit_Sekundaerachse "Signalisiert die Momentenfreiheit der Sekundärachse und ist damit Voraussetzung für das Abkoppeln.";
CM_ SG_ 394 MO_Nachlaufzeit_Kuehlerluefter "Nachlaufzeit Kühlerlüfter MSG für Verwendung im TME SG";
CM_ SG_ 394 MO_Start_Art "Beschreibt Art des Starts näher 

Schlupfstart kann entweder Momentenvorhalt oder Impulsstart sein oder eine Kombination aus beidem.";
CM_ SG_ 394 MO_Start_Dynamik "Zeigt die Start-Variante bzw. Start-Dynamik eines VKM-Starts an";
CM_ SG_ 394 MO_Tankklappensteuerung "Ansteuerungsanforderung der Tankklappe";

CM_ SG_ 339 MO_ErwGrenzen_Anf "temporäre Anforderung erweiterter Leistungsgrenzen
0 = normaler Betrieb angefordert
1 = erweiterte Leistungsgrenzen angefordert
BMS und EMS liefern ggf. erweiterte Leistungsgrenzen, um VKM-Start auch unter schwierigen Bedingungen gewährleisten zu könne";
CM_ SG_ 339 MO_Fehler_Notentladung_Anf "Aufforderung zur schnellstmöglichen Entladeung des HV-Zwischenkreises aufgrund Crash-Erkennung / Abriss Pilotlinie";
CM_ SG_ 339 MO_HVEM_Eskalation "Eskalationsbit, mit diesem zusammen darf MO_HVEM_MaxLeistung < der minimal angeforderten Leistung sein und ist durch das HVEM durch Ergreifung aller Eskalationsmaßnahmen umzusetzen (Bei neg. Ladebilanz z.B. im Leerlauf nötig, um die HVBatt vor Entladung e";
CM_ SG_ 339 MO_HVEM_MaxLeistung "Maximal zulässige Leistung, die das HVEM einzustellen hat. 
Ohne Eskalationsbit ist diese Anforderung >= der Minimal benötigten Leistung des HVEM

Hinweis: Ehemaliger Fehlerwert 0x1FF wird senderseitig nicht unterstützt. Diesen Wert aus Kompatibilitäts";
CM_ SG_ 339 MO_HVK_AntriebFehlerstatus "aktueller Fehlerstatus des Antriebs
0: Komponente IO (keine HVK relevanter Fehler)
1 - 5: reserve
6: Keine Komponentenfunktion (Aus)
7: Init";
CM_ SG_ 339 MO_HVK_AntriebZustand "Aktueller Zustand des Antriebs:
0 : Antrieb_AUS               
1 : Antrieb_Startphase        
2 : E-Fahren                  
3 : Hybrid-Fahren             
4 : reserve                   
5 : reserve                   
6 : Keine_Komponentenfunktion ";
CM_ SG_ 339 MO_HVK_EmFehlerstatus "aktueller Fehlerstatus des elektrischen Antriebes (E-Maschine und PWR)

0: Komponente IO (keine HVK relevanter Fehler)
1: Eingeschränkter Betrieb wg. Teilbetrieb
2: reserve
3: Eingeschr_KompFkt_Interlock
4 - 5: reserve
6: Keine Komponentenfunktion ";
CM_ SG_ 339 MO_HVK_EmIstzustand "Aktueller Istzustand der Elm_State
0 : HvOff              
1 : HvStbyReq          
2 : HvStbyOk         
3 : HvBattOnReq        
4 : HvBattOnOk       
10 : HvOnIdle          
18 : HvOnDrvReq        
19 : HvOnDrvOk       
20 : HvOnDrvRdy          ";
CM_ SG_ 339 MO_MVK_AntriebFehlerstatus "aktueller Fehlerstatus des Antriebs
0: Komponente IO (keine MVK relevanter Fehler)
1 - 5: reserve
6: Keine Komponentenfunktion (Aus)
7: Init";
CM_ SG_ 339 MO_MVK_AntriebZustand "Aktueller Zustand des Antriebs:
0 : Antrieb_AUS               
1 : Antrieb_Startphase        
2 : FreilaufMotorAus                  
3 : reserve             
4 : reserve                   
5 : reserve                   
6 : Keine_Komponentenfunktio";
CM_ SG_ 339 MO_MVK_Bordnetz_Anf "Explizite Anforderung des Motors zur Aktivierung bzw. Aufrechterhaltung des Mittelvolt-Bordnetzes für die Ausführung von Motorfunktionen";
CM_ SG_ 339 MO_MVK_EmFehlerstatus "aktueller Fehlerstatus der elektrischen Maschine (RSG)

0: Komponente IO (keine MVK relevanter Fehler)
1: Eingeschränkter Betrieb wg. Teilbetrieb
2: reserve
3 - 5: reserve
6: Keine Komponentenfunktion (Aus)
7: Init";
CM_ SG_ 339 MO_MVK_EmIstzustand "Aktueller Istzustand der Elm_State
0 : MvOff              
1 : MvStbyReq          
2 : MvStbyOk         
3 : MvBattOnReq        
4 : MvBattOnOk       
10 : MvOnIdle          
18 : MvOnDrvReq        
19 : MvOnDrvOk       
20 : MvOnDrv           
";
CM_ SG_ 339 MSG_HYB_30_BZ "BZ für die Botschaft MSG_HYB_30
Botschaft asynchron geroutet. Zählerwert kann springen.";
CM_ SG_ 339 MSG_HYB_30_CRC "CRC für die Botschaft MSG_HYB_30";

CM_ SG_ 1434 KL_IstLeistung "Gesamt-Ist-Leistung für Komfort- und Thermomanagement";
CM_ SG_ 1434 TME_Dauer_Vorkond_innen "Geschätzte Dauer für die Vorkonditionierung";
CM_ SG_ 1434 TME_Eskalation "Anfrage um zusätzliche Leistung während des Ladens / Leistungsreduzierung des Komfortbereichs während der Fahrt zu erlauben ";
CM_ SG_ 1434 TME_Leistungsanf_Komfort "Leistungsanforderung für den Komfort-Bereich (Innenraum kühlen/heizen)";
CM_ SG_ 1434 TME_Leistungsanf_ThermoHeizen "Leistungsanforderung Thermomanagement für das Heizen von Komponenten";
CM_ SG_ 1434 TME_Leistungsanf_ThermoKuehlen "Leistungsanforderung Thermomanagement für das Kühlen von Komponenten";

CM_ SG_ 689 TME_Energie_Komfort "Energieverbrauch für die Vorkonditionierung des Innenraums (beim Laden)";
CM_ SG_ 689 TME_Energie_Thermo "Energieverbrauch für die Temperierung der Bauteile (beim Laden)";
CM_ SG_ 689 TME_PlanAntw_Zaehler "TME Antwort-Zähler der Ladeplan-Anfragen des ILF";
CM_ SG_ 689 TME_Verbrauch_gesamt "Energieverbrauch vom TME für Komfort- und Thermo-Bereich";
CM_ SG_ 689 TME_Verbrauch_gesamt_Ueberlauf "Überlauf-Bit für das Signal TME_Verbrauch_gesamt";

CM_ SG_ 931 MVEM_DC_SollLeistung_MV "Soll-Leistung des DC/DC-Wandlers Höherspannungsseitig (48V-seitig).

Hochsetzen - negativ";
CM_ SG_ 931 MVEM_DC_SollSpannung_MV "Soll-Ausgangspannung des DC/DC-Wandlers MV-Spannungssseitig (48V-seitig).";
CM_ SG_ 931 MVEM_EMG_MaxGenSpannung "max. Spannung des 48V-RSG im generatorischen Betrieb.";
CM_ SG_ 931 MVEM_EMG_MaxGenStrom "Maximaler Strom des RSGs im spannungsgeregeltem Betrieb. ";
CM_ SG_ 931 MVEM_IstStrom_MVVerbraucher "Iststrom-Aufnahme der 48V-Verbraucher (inkl 48V-DC/DC-Wandler) im 48V-Netz

Verbrauch - positiv
Rückspeisung - negativ";
CM_ SG_ 931 MVEM_MO_RSG_Startleistung "Verfügbare Leistungvorgabe von MVEM an MSG:
Leistungsvorgabe für Freigabe Start-Stopp und Freilaufmotor-Aus";
CM_ SG_ 931 MVEM_Umin_Funktionsgruppe_C_02 "Systeme der Funktionsgruppe C müssen bei Unterschreitung der Spannungsgrenze ihren Leistungsbedarf dynamisch abregeln.";

CM_ SG_ 2589283456 MVEM_MO_Sollspannung_Notbetrieb "Im eingeschränkten Betrieb des 48V Systems und Fehlerfälle der 48V Batterie.";
CM_ SG_ 2589283456 MVEM_Umax_Rueckspeisung "Systeme, die rückspeisefähig sind, müssen vor Erreichen der oberen Spannungsgrenze ihren Leistungsbedarf dynamisch abregeln.";
CM_ SG_ 2589283456 MVEM_Umin_Funktionsgruppe_A "Systeme der Funktionsgruppe A müssen bei Unterschreitung der Spannungsgrenze ihren Leistungsbedarf dynamisch abregeln.";
CM_ SG_ 2589283456 MVEM_Umin_Funktionsgruppe_B "Systeme der Funktionsgruppe B müssen bei Unterschreitung der Spannungsgrenze ihren Leistungsbedarf dynamisch abregeln.";
CM_ SG_ 2589283456 MVEM_Umin_Funktionsgruppe_C "Systeme der Funktionsgruppe C müssen bei Unterschreitung der Spannungsgrenze ihren Leistungsbedarf dynamisch abregeln.";

CM_ SG_ 2463978826 MVEM_TME_Leistungsfreigabe "Die Leistung, welches das MVEM der TME zur Verfügung stellt.";

CM_ SG_ 1284 MV_Bordnetz_aktiv "Signalisiert ein aktives MV-Bordnetz. MV-Schütze geschlossen.";
CM_ SG_ 1284 MV_Bordnetz_Fehler "Status ob im  MV-Netz ein Fehler detektiert wurde.";
CM_ SG_ 1284 MVK_01_BZ "4bit Botschaftszähler, wird mit jeder Sendebotschaft inkrementiert";
CM_ SG_ 1284 MVK_01_CRC "Für MLB:
Berechnung siehe Lastenheft 'Kommunikationsabsicherung für FlexRay und CAN'
Ab MQB und MLBevo:
Berechnung siehe Lastenheft 'End-to-End Kommunikationsabsicherung'

Endwerte siehe Begleitdokument 'S-PDU Kennungsfolgen'";
CM_ SG_ 1284 MVK_BMS_Sollmodus "Angeforderter Sollmodus der MV-Batterie:
0 : MV_Off                                
1 : MV_On (HS geschlossen)                
2 : nicht belegbar                        
3 : nicht belegbar                        
4 : nicht belegbar 
5 : nicht belegb";
CM_ SG_ 1284 MVK_BOOST_Sollmodus "Sollmodus eBooster auf 48V
0 : keine Freigabe
1 : Freigabe
2 : nicht belegbar
3 : nicht belegbar
4 : nicht belegbar
5 : nicht belegbar
6 : nicht belegbar
7 : Init   (CAN-Initialisierung)   

Info: 'nicht belegbar' d.h. Sollmodus nicht relevant f";
CM_ SG_ 1284 MVK_DCDC_Sollmodus "angeforderte Soll-Betriebsart des 48V DC/DC-Wandlers: 
0: Standby; Kommunikation aktiv
1: MvOn (48V-Netz ist aktiv)
2: Tiefsetzen (48V --> BN 14,4V)
3: Hochsetzen (BN 14,4V --> 48V)
4: Startunterstuetzung_48V (Stützung des 48V-BN im Startvorgang)
5:";
CM_ SG_ 1284 MVK_DCDC_Sollmodus_02 "Angeforderte Soll-Betriebsart des 48V DC/DC-Wandlers: 
0: Standby; Kommunikation aktiv
1: MvOn (48V-Netz ist aktiv)
2: Tiefsetzen (48V --> BN12)
3: Hochsetzen (BN12 --> 48V)
4: Startunterstuetzung_48V (Stützung des 48V-BN im Startvorgang)
5: nicht v";
CM_ SG_ 1284 MVK_eABC_Sollmodus "Sollmodus eABC auf 48V
0 : keine Freigabe
1 : Freigabe
2 : nicht belegbar
3 : nicht belegbar
4 : nicht belegbar
5 : nicht belegbar
6 : nicht belegbar
7 : Init   (CAN-Initialisierung)   

Info: 'nicht belegbar' d.h. Sollmodus nicht relevant für M";
CM_ SG_ 1284 MVK_eAWS_Sollmodus "Sollmodus eAWS auf 48V
0 : keine Freigabe
1 : Freigabe
2 : nicht belegbar
3 : nicht belegbar
4 : nicht belegbar
5 : nicht belegbar
6 : nicht belegbar
7 : Init   (CAN-Initialisierung)   

Info: 'nicht belegbar' d.h. Sollmodus nicht relevant für M";
CM_ SG_ 1284 MVK_eKAT_Sollmodus "Angeforderter Sollmodus des eKAT";
CM_ SG_ 1284 MVK_eKMV_Sollmodus "Sollmodus MVK --> TME für Ansteuerung des eKMV";
CM_ SG_ 1284 MVK_Istmodus_Anf "MVK-Anforderung an alle 48V-Komponenten deren Istmodus im schnellen Zyklus (Inhibitzeit) zu senden.";
CM_ SG_ 1284 MVK_MO_EmSollzustand "Anforderung vom MVK Sollzustand der Elm_State
0 = MvOff              
1 = MvStbyReq          
2 = MvStbyWait         
3 = MvBattOnReq        
4 = MvBattOnWait       
10 = MvOnIdle          
18 = MvOnDrvReq        
19 = MvOnDrvWait       
20 = MvO";
CM_ SG_ 1284 MVK_MV_Netz_Warnungen "Anforderung Warnung/Fehler MV-System im Kombi
0: Keine Warnung/Init
1:Anforderung_Anzeige_Warnung_MV-Netz (gelbes Symbol)
2:Anforderung_Anzeige_Fehler_MV-Netz (rotes Symbol)
3:Anforderung_Anzeige_Warnung_Kein_Wiederstart_möglich";
CM_ SG_ 1284 MVK_MVH_L_Sollmodus "Sollmodus MVK --> TME für Ansteuerung des MVH_L";
CM_ SG_ 1284 MVK_MVPTC_Sollmodus "Sollmodus MV-PTC
0 : keine Freigabe
1 : Freigabe
2 : nicht belegbar
3 : nicht belegbar
4 : nicht belegbar
5 : nicht belegbar
6 : nicht belegbar
7 : Init   (CAN-Initialisierung)   

Info: 'nicht belegbar' d.h. Sollmodus nicht relevant für MVK";

CM_ SG_ 1157 ND_SatInUse "Anzahl der zur Berechnung verwendeten Satelliten";
CM_ SG_ 1157 ND_SatInView "Anzahl der sichtbaren Satelliten";
CM_ SG_ 1157 ND_UTC "UTC-Zeit, verstrichene Sekunden seit 01.01.1970 00:00
0xFFFFFFFE = Init
0xFFFFFFFF = Fehler bei Berechnung der UTC-Time";
CM_ SG_ 1157 NP_Altitude "Hoehe ueber NN
0xFFF = Fehler bei der Berechnung der Höhe über NN";
CM_ SG_ 1157 POS_Guete_horizontal "Horizontale Genauigkeit der Position in der Botschaft NavPos_02_MapMatched (Signale
POS_LatDegree, POS_LongDegree)

Abhängig vom Signal
POS_Guete_horizontal_verfuegbar";
CM_ SG_ 1157 POS_Guete_horizontal_verfuegbar "Bei gesetztem Bit wird das Signal POS_Guete_horizontal befüllt und ist verfügbar.";

CM_ SG_ 1158 NP_LatDegree "Latitude (Nord-Süd Wert)";
CM_ SG_ 1158 NP_LatDirection "Hemisphäre Nord/Süd";
CM_ SG_ 1158 NP_LongDegree "Longitude (Ost-West Wert)";
CM_ SG_ 1158 NP_LongDirection "Hemisphäre Ost/West";
CM_ SG_ 1158 NP_Sat "Nummer der verwendeten Sateliten beim letzten Fix";

CM_ SG_ 2589283496 POS_Heading "Heading of current position
MUX(1)";
CM_ SG_ 2589283496 POS_Heading_Trust "Vertrauenswert Heading 
MUX(1) ";
CM_ SG_ 2589283496 POS_Last_GPS_Sync "Letztes bekannte GPS Sync in [s]
MUX(1)";
CM_ SG_ 2589283496 POS_LatDegree "latitude - position data of navigation
MUX(0)";
CM_ SG_ 2589283496 POS_LatDirection "latitude direction nav position
MUX(0)";
CM_ SG_ 2589283496 POS_LongDegree "long - position data of navigation
MUX(0)";
CM_ SG_ 2589283496 POS_LongDirection "longitude direction nav position
MUX(0)";
CM_ SG_ 2589283496 POS_MUX "Multiplex-Signal zum schalten des Signals der Positionen von der Navigation.
MUX(0/1)";
CM_ SG_ 2589283496 POS_ODD_EVEN "Synchronisation der MUX Pos Signale
MUX(0/1)";
CM_ SG_ 2589283496 POS_PosStati "Aktueller Status der Navgation:
MUX(0)
0   init
1   no nav available (ready_4_nav)
2   no map available (sd_removed, not_enabled)
3   nav booting
4   nav error
5   nav calibrating
6   nav no gps resync since 1h
7   nav offroad  parkgarage ramp of";
CM_ SG_ 2589283496 POS_UTC_REF "Zeitstempel der Nav
MUX(1)

UTC-Zeit, verstrichene Sekunden seit 01.01.1970 00:00
0xFFFFFFFE = Init
0xFFFFFFFF = Fehler bei Berechnung der UTC-Time

Signal wird nur bei aktiver Navigation-Funktion zyklisch gesendet.";

CM_ SG_ 2600468623 NM_AWC_CAB "CAB = Clusteraktivbits";
CM_ SG_ 2600468623 NM_AWC_Car_Wakeup "Car Wakeup (Gateway wertet aus)";
CM_ SG_ 2600468623 NM_AWC_CBV_AWB "Das Signal ist zu setzen, wenn das SG aktiv den Bus geweckt hat
0 = Passiver_WakeUp = SG hat das Netzwerk nicht aktiv geweckt
1 = Akitiver_WakeUp = SG hat das Netzwerk aktiv geweckt";
CM_ SG_ 2600468623 NM_AWC_CBV_CRI "Das Signal ist dauerhaft gesetzt, wenn das NM-Layout Cluster- Anforderungen enthält";
CM_ SG_ 2600468623 NM_AWC_NM_aktiv_Diagnose "Diagnose befindet sich nach VW80124 in einer NonDefaultDiagnostic-Session, z.B. ExtendedDiagnostic-Session";
CM_ SG_ 2600468623 NM_AWC_NM_aktiv_KL15 "Steuergerät hat KL15-EIN erkannt";
CM_ SG_ 2600468623 NM_AWC_NM_aktiv_Tmin "Mindestaktivzeit ist noch nicht abgelaufen (bei jedem Weckereignis wird die Mindestaktivzeit neu gestartet)";
CM_ SG_ 2600468623 NM_AWC_NM_State "1 = Zustand Repeat Message (<-- Bus-Sleep Mode)
2 = Zustand Repeat Message (<-- Prepare Bus-Sleep Mode)
4 = Zustand Normal Operation (<-- Repeat Message)
8 = Zustand Normal Operation (<-- Ready Sleep)";
CM_ SG_ 2600468623 NM_AWC_SNI "Source Node-Identifier (SNI) identifiziert den Sender der NM-Botschaft (Knotenadresse) eindeutig im Fahrzeug";
CM_ SG_ 2600468623 NM_AWC_UDS_CC "Funktionseinschränkung aufgrund aktivem UDS-Communication Control, siehe VW80124";

CM_ SG_ 2600468654 NM_BattRegelung_CAB "CAB = Clusteraktivbits";
CM_ SG_ 2600468654 NM_BattRegelung_Car_Wakeup "Car Wakeup (Gateway wertet aus)";
CM_ SG_ 2600468654 NM_BattRegelung_CBV_AWB "Das Signal ist zu setzen, wenn das SG aktiv den Bus geweckt hat
0 = Passiver_WakeUp = SG hat das Netzwerk nicht aktiv geweckt
1 = Akitiver_WakeUp = SG hat das Netzwerk aktiv geweckt";
CM_ SG_ 2600468654 NM_BattRegelung_CBV_CRI "Das Signal ist dauerhaft gesetzt, wenn das NM-Layout Cluster- Anforderungen enthält";
CM_ SG_ 2600468654 NM_BattRegelung_NM_aktiv_KL15 "Steuergerät hat KL15-EIN erkannt";
CM_ SG_ 2600468654 NM_BattRegelung_NM_aktiv_NV "Niedervoltspeicher_angefordert";
CM_ SG_ 2600468654 NM_BattRegelung_NM_aktiv_Tmin "Mindestaktivzeit ist noch nicht abgelaufen (bei jedem Weckereignis wird die Mindestaktivzeit neu gestartet)";
CM_ SG_ 2600468654 NM_BattRegelung_NM_State "1 = Zustand Repeat Message (<-- Bus-Sleep Mode)
2 = Zustand Repeat Message (<-- Prepare Bus-Sleep Mode)
4 = Zustand Normal Operation (<-- Repeat Message)
8 = Zustand Normal Operation (<-- Ready Sleep)";
CM_ SG_ 2600468654 NM_BattRegelung_SNI "Source Node-Identifier (SNI) identifiziert den Sender der NM-Botschaft (Knotenadresse) eindeutig im Fahrzeug";
CM_ SG_ 2600468654 NM_BattRegelung_UDS_CC "Funktionseinschränkung aufgrund aktivem UDS-Communication Control, siehe VW80124";
CM_ SG_ 2600468654 NM_BattRegelungNM_aktiv_Diagnose "Diagnose befindet sich nach VW80124 in einer NonDefaultDiagnostic-Session, z.B. ExtendedDiagnostic-Session";

CM_ SG_ 2600468636 NM_BMS_48V_CAB "CAB = Clusteraktivbits";
CM_ SG_ 2600468636 NM_BMS_48V_Car_Wakeup "Car Wakeup (Gateway wertet aus)";
CM_ SG_ 2600468636 NM_BMS_48V_CBV_AWB "Das Signal ist zu setzen, wenn das SG aktiv den Bus geweckt hat
0 = Passiver_WakeUp = SG hat das Netzwerk nicht aktiv geweckt
1 = Akitiver_WakeUp = SG hat das Netzwerk aktiv geweckt";
CM_ SG_ 2600468636 NM_BMS_48V_CBV_CRI "Das Signal ist dauerhaft gesetzt, wenn das NM-Layout Cluster- Anforderungen enthält";
CM_ SG_ 2600468636 NM_BMS_48V_NM_aktiv_Diagnose "Diagnose befindet sich nach VW80124 in einer NonDefaultDiagnostic-Session, z.B. ExtendedDiagnostic-Session";
CM_ SG_ 2600468636 NM_BMS_48V_NM_aktiv_Hochvolt "Hochvolt aktiv";
CM_ SG_ 2600468636 NM_BMS_48V_NM_aktiv_KL15 "Steuergerät hat KL15-EIN erkannt";
CM_ SG_ 2600468636 NM_BMS_48V_NM_aktiv_Tmin "Mindestaktivzeit ist noch nicht abgelaufen (bei jedem Weckereignis wird die Mindestaktivzeit neu gestartet)";
CM_ SG_ 2600468636 NM_BMS_48V_NM_State "1 = Zustand Repeat Message (<-- Bus-Sleep Mode)
2 = Zustand Repeat Message (<-- Prepare Bus-Sleep Mode)
4 = Zustand Normal Operation (<-- Repeat Message)
8 = Zustand Normal Operation (<-- Ready Sleep)";
CM_ SG_ 2600468636 NM_BMS_48V_SNI "Source Node-Identifier (SNI) identifiziert den Sender der NM-Botschaft (Knotenadresse) eindeutig im Fahrzeug";
CM_ SG_ 2600468636 NM_BMS_48V_UDS_CC "Funktionseinschränkung aufgrund aktivem UDS-Communication Control, siehe VW80124";

CM_ SG_ 2600468545 NM_DCDC_CAB "CAB = Clusteraktivbits";
CM_ SG_ 2600468545 NM_DCDC_Car_Wakeup "Car Wakeup (Gateway wertet aus)
";
CM_ SG_ 2600468545 NM_DCDC_CBV_AWB "Das Signal ist zu setzen, wenn das SG aktiv den Bus geweckt hat";
CM_ SG_ 2600468545 NM_DCDC_CBV_CRI "Das Signal ist dauerhaft gesetzt, wenn das NM-Layout dem neuen NM-Layout für Teilnetzbetrieb entspricht";
CM_ SG_ 2600468545 NM_DCDC_NM_aktiv_Anf_MVK "Anforderung MVK (Nachlaufursache, SG nicht im NM-Zustand 'Ready to Sleep')";
CM_ SG_ 2600468545 NM_DCDC_NM_aktiv_Diagnose "Diagnose befindet sich nach VW80124 in einer NonDefaultDiagnostic-Session, z.B. ExtendedDiagnostic-Session";
CM_ SG_ 2600468545 NM_DCDC_NM_aktiv_KL15 "Steuergerät hat KL15-EIN erkannt";
CM_ SG_ 2600468545 NM_DCDC_NM_aktiv_Tmin "Mindestaktivzeit ist noch nicht abgelaufen (bei jedem Weckereignis wird die Mindestaktivzeit neu gestartet)";
CM_ SG_ 2600468545 NM_DCDC_NM_State "1 = Zustand Repeat Message (<-- Bus-Sleep Mode)
2 = Zustand Repeat Message (<-- Prepare Bus-Sleep Mode)
4 = Zustand Normal Operation (<-- Repeat Message)
8 = Zustand Normal Operation (<-- Ready Sleep)
16 = Zustand Repeat Message (<-- Ready Sleep)
32 ";
CM_ SG_ 2600468545 NM_DCDC_SNI "Source Node-Identifier (SNI) identifiziert den Sender der NM-Botschaft (Knotenadresse) eindeutig im Fahrzeug";
CM_ SG_ 2600468545 NM_DCDC_UDS_CC "Funktionseinschränkung aufgrund aktivem UDS-Communication Control; siehe VW80124";

CM_ SG_ 2600468663 NM_DCDC_HV_CAB "CAB = Clusteraktivbits";
CM_ SG_ 2600468663 NM_DCDC_HV_Car_Wakeup "Car Wakeup (Gateway wertet aus)";
CM_ SG_ 2600468663 NM_DCDC_HV_CBV_AWB "Das Signal ist zu setzen, wenn das SG aktiv den Bus geweckt hat";
CM_ SG_ 2600468663 NM_DCDC_HV_CBV_CRI "Das Signal ist dauerhaft gesetzt, wenn das NM-Layout dem neuen NM-Layout für Teilnetzbetrieb entspricht";
CM_ SG_ 2600468663 NM_DCDC_HV_NM_aktiv_Anf_HVK "Anforderung HVK (Nachlaufursache, SG nicht im NM-Zustand 'Ready to Sleep')";
CM_ SG_ 2600468663 NM_DCDC_HV_NM_aktiv_Diagnose "Diagnose befindet sich nach VW80124 in einer NonDefaultDiagnostic-Session, z.B. ExtendedDiagnostic-Session";
CM_ SG_ 2600468663 NM_DCDC_HV_NM_aktiv_KL15 "Steuergerät hat KL15-EIN erkannt";
CM_ SG_ 2600468663 NM_DCDC_HV_NM_aktiv_Tmin "Mindestaktivzeit ist noch nicht abgelaufen (bei jedem Weckereignis wird die Mindestaktivzeit neu gestartet)";
CM_ SG_ 2600468663 NM_DCDC_HV_NM_State "1 = Zustand Repeat Message (<-- Bus-Sleep Mode)
2 = Zustand Repeat Message (<-- Prepare Bus-Sleep Mode)
4 = Zustand Normal Operation (<-- Repeat Message)
8 = Zustand Normal Operation (<-- Ready Sleep)";
CM_ SG_ 2600468663 NM_DCDC_HV_SNI "Source Node-Identifier (SNI) identifiziert den Sender der NM-Botschaft (Knotenadresse) eindeutig im Fahrzeug";
CM_ SG_ 2600468663 NM_DCDC_HV_UDS_CC "Funktionseinschränkung aufgrund aktivem UDS-Communication Control; siehe VW80124";

CM_ SG_ 2600468679 NM_DCDC_HV_02_CAB "CAB = Clusteraktivbits";
CM_ SG_ 2600468679 NM_DCDC_HV_02_Car_Wakeup "Car Wakeup (Gateway wertet aus)";
CM_ SG_ 2600468679 NM_DCDC_HV_02_CBV_AWB "Das Signal ist zu setzen, wenn das SG aktiv den Bus geweckt hat";
CM_ SG_ 2600468679 NM_DCDC_HV_02_CBV_CRI "Das Signal ist dauerhaft gesetzt, wenn das NM-Layout dem neuen NM-Layout für Teilnetzbetrieb entspricht";
CM_ SG_ 2600468679 NM_DCDC_HV_02_NM_aktiv_Anf_HVK "Anforderung HVK (Nachlaufursache, SG nicht im NM-Zustand 'Ready to Sleep')";
CM_ SG_ 2600468679 NM_DCDC_HV_02_NM_aktiv_Diag "Diagnose befindet sich nach VW80124 in einer NonDefaultDiagnostic-Session, z.B. ExtendedDiagnostic-Session";
CM_ SG_ 2600468679 NM_DCDC_HV_02_NM_aktiv_KL15 "Steuergerät hat KL15-EIN erkannt";
CM_ SG_ 2600468679 NM_DCDC_HV_02_NM_aktiv_Tmin "Mindestaktivzeit ist noch nicht abgelaufen (bei jedem Weckereignis wird die Mindestaktivzeit neu gestartet)";
CM_ SG_ 2600468679 NM_DCDC_HV_02_NM_State "1 = Zustand Repeat Message (<-- Bus-Sleep Mode)
2 = Zustand Repeat Message (<-- Prepare Bus-Sleep Mode)
4 = Zustand Normal Operation (<-- Repeat Message)
8 = Zustand Normal Operation (<-- Ready Sleep)";
CM_ SG_ 2600468679 NM_DCDC_HV_02_SNI "Source Node-Identifier (SNI) identifiziert den Sender der NM-Botschaft (Knotenadresse) eindeutig im Fahrzeug";
CM_ SG_ 2600468679 NM_DCDC_HV_02_UDS_CC "Funktionseinschränkung aufgrund aktivem UDS-Communication Control; siehe VW80124";

CM_ SG_ 2600468661 NM_FCU_CAB "CAB = Clusteraktivbits";
CM_ SG_ 2600468661 NM_FCU_Car_Wakeup "Car Wakeup (Gateway wertet aus)";
CM_ SG_ 2600468661 NM_FCU_CBV_AWB "Das Signal ist zu setzen, wenn das SG aktiv den Bus geweckt hat";
CM_ SG_ 2600468661 NM_FCU_CBV_CRI "Das Signal ist dauerhaft gesetzt, wenn das NM-Layout dem neuen NM-Layout für Teilnetzbetrieb entspricht";
CM_ SG_ 2600468661 NM_FCU_NM_aktiv_Diag "Diagnose befindet sich nach VW80124 in einer NonDefaultDiagnostic-Session, z.B. ExtendedDiagnostic-Session";
CM_ SG_ 2600468661 NM_FCU_NM_aktiv_HCAN "Buskopplung - SubCAN aktiv wenn Hauptbus (HCAN) aktiv";
CM_ SG_ 2600468661 NM_FCU_NM_aktiv_KL15 "Steuergerät hat KL15-EIN erkannt";
CM_ SG_ 2600468661 NM_FCU_NM_aktiv_Shutdown "Beim Shutdown muss die Restenergie im System abgebaut werden. Bei kalten Temperaturen muss davor zunächst die Zelle getrocknet werden.";
CM_ SG_ 2600468661 NM_FCU_NM_aktiv_Tankvorgang "Busnachlauf aufgrund aktivem Tankvorgang oder Tankvorbereitung";
CM_ SG_ 2600468661 NM_FCU_NM_aktiv_Tmin "Mindestaktivzeit ist noch nicht abgelaufen (bei jedem Weckereignis wird die Mindestaktivzeit neu gestartet)";
CM_ SG_ 2600468661 NM_FCU_NM_State "1 = Zustand Repeat Message (<-- Bus-Sleep Mode)
2 = Zustand Repeat Message (<-- Prepare Bus-Sleep Mode)
4 = Zustand Normal Operation (<-- Repeat Message)
8 = Zustand Normal Operation (<-- Ready Sleep)";
CM_ SG_ 2600468661 NM_FCU_SNI "Source Node-Identifier (SNI) identifiziert den Sender der NM-Botschaft (Knotenadresse) eindeutig im Fahrzeug";
CM_ SG_ 2600468661 NM_FCU_UDS_CC "Funktionseinschränkung aufgrund aktivem UDS-Communication Control; siehe VW80124";

CM_ SG_ 2600468496 NM_Gateway_CAB "CAB = Clusteraktivbits";
CM_ SG_ 2600468496 NM_Gateway_Car_Wakeup "Car Wakeup (Subbusmaster wertet aus)

MQB: 
-Diagnose- oder Komponentenschutzmaster-Funktion weckt den schlafenden Subbus (z.B. MOST)

E3_Volumen:
- Diagnose aktiv -aktive Diagnosekommunikation am OBD-Stecker

MQBw_Baseline:
- Diagnose aktiv -akt";
CM_ SG_ 2600468496 NM_Gateway_CBV_AWB "Das Signal ist zu setzen, wenn das SG aktiv den Bus geweckt hat
0 = Passiver_WakeUp = SG hat das Netzwerk nicht aktiv geweckt
1 = Akitiver_WakeUp = SG hat das Netzwerk aktiv geweckt";
CM_ SG_ 2600468496 NM_Gateway_CBV_CRI "Das Signal ist dauerhaft gesetzt, wenn das NM-Layout Cluster- Anforderungen enthält";
CM_ SG_ 2600468496 NM_Gateway_NM_aktiv_Buskopplung "Nachlauf aufgrund Kopplung zweier Busse. z.B. K-CAN und K2-CAN";
CM_ SG_ 2600468496 NM_Gateway_NM_aktiv_Connect "Nachlauf aufgrund Connect";
CM_ SG_ 2600468496 NM_Gateway_NM_aktiv_CWU "Nachlauf aufgrund CWU Anforderung";
CM_ SG_ 2600468496 NM_Gateway_NM_aktiv_Diagnose "Diagnose befindet sich nach VW80124 in einer NonDefaultDiagnostic-Session, z.B. ExtendedDiagnostic-Session";
CM_ SG_ 2600468496 NM_Gateway_NM_aktiv_EM "Nachlauf aufgrund Energiemanagement";
CM_ SG_ 2600468496 NM_Gateway_NM_aktiv_FC "Nachlauf aufgrund Funktionscluster Anforderung";
CM_ SG_ 2600468496 NM_Gateway_NM_aktiv_Fremdladung "Nachlauf aufgrund Fremdladung";
CM_ SG_ 2600468496 NM_Gateway_NM_aktiv_KL15 "Steuergerät hat KL15-EIN erkannt";
CM_ SG_ 2600468496 NM_Gateway_NM_aktiv_LIN2 "Bus aktiv aufgrund aktivem LIN2 (Hupe betätigt)";
CM_ SG_ 2600468496 NM_Gateway_NM_aktiv_OBDC "Nachlauf aufgrund OBDC";
CM_ SG_ 2600468496 NM_Gateway_NM_aktiv_Tmin "Mindestaktivzeit ist noch nicht abgelaufen (bei jedem Weckereignis wird die Mindestaktivzeit neu gestartet)";
CM_ SG_ 2600468496 NM_Gateway_NM_State "1 = Zustand Repeat Message (<-- Bus-Sleep Mode)
2 = Zustand Repeat Message (<-- Prepare Bus-Sleep Mode)
4 = Zustand Normal Operation (<-- Repeat Message)
8 = Zustand Normal Operation (<-- Ready Sleep)";
CM_ SG_ 2600468496 NM_Gateway_SNI "Source Node-Identifier (SNI) identifiziert den Sender der NM-Botschaft (Knotenadresse) eindeutig im Fahrzeug";
CM_ SG_ 2600468496 NM_Gateway_UDS_CC "Funktionseinschränkung aufgrund aktivem UDS-Communication Control, siehe VW80124";

CM_ SG_ 2600468603 NM_BMC_NM_aktiv_HCAN "BMC-Subcan wird wachhgehalten, solange H-CAN aktiv ist.";
CM_ SG_ 2600468603 NM_Hybrid_01_CAB "CAB = Clusteraktivbits";
CM_ SG_ 2600468603 NM_Hybrid_01_Car_Wakeup "Car Wakeup (Gateway wertet aus)
";
CM_ SG_ 2600468603 NM_Hybrid_01_CBV_AWB "Das Signal ist zu setzen, wenn das SG aktiv den Bus geweckt hat
0 = Passiver_WakeUp = SG hat das Netzwerk nicht aktiv geweckt
1 = Akitiver_WakeUp = SG hat das Netzwerk aktiv geweckt";
CM_ SG_ 2600468603 NM_Hybrid_01_CBV_CRI "Das Signal ist dauerhaft gesetzt, wenn das NM-Layout Cluster- Anforderungen enthält";
CM_ SG_ 2600468603 NM_Hybrid_01_NM_aktiv_Diagnose "Diagnose befindet sich nach VW80124 in einer NonDefaultDiagnostic-Session, z.B. ExtendedDiagnostic-Session";
CM_ SG_ 2600468603 NM_Hybrid_01_NM_aktiv_Hochvolt "Hochvolt aktiv";
CM_ SG_ 2600468603 NM_Hybrid_01_NM_aktiv_KL15 "Steuergerät hat KL15-EIN erkannt";
CM_ SG_ 2600468603 NM_Hybrid_01_NM_aktiv_KondAnf "Hochvoltbatterie Dauerkonditionierung";
CM_ SG_ 2600468603 NM_Hybrid_01_NM_aktiv_Tmin "Mindestaktivzeit ist noch nicht abgelaufen (bei jedem Weckereignis wird die Mindestaktivzeit neu gestartet)";
CM_ SG_ 2600468603 NM_Hybrid_01_NM_State "1 = Zustand Repeat Message (<-- Bus-Sleep Mode)
2 = Zustand Repeat Message (<-- Prepare Bus-Sleep Mode)
4 = Zustand Normal Operation (<-- Repeat Message)
8 = Zustand Normal Operation (<-- Ready Sleep)";
CM_ SG_ 2600468603 NM_Hybrid_01_SNI "Source Node-Identifier (SNI) identifiziert den Sender der NM-Botschaft (Knotenadresse) eindeutig im Fahrzeug";
CM_ SG_ 2600468603 NM_Hybrid_01_UDS_CC "Funktionseinschränkung aufgrund aktivem UDS-Communication Control, siehe VW80124";

CM_ SG_ 2600468548 NM_Ladegeraet_CAB "CAB = Clusteraktivbits";
CM_ SG_ 2600468548 NM_Ladegeraet_Car_Wakeup "Car Wakeup (Gateway wertet aus)
MQB: Ladestecker gesteckt, entfernt, verriegelt oder entriegelt";
CM_ SG_ 2600468548 NM_Ladegeraet_CBV_AWB "Das Signal ist zu setzen, wenn das SG aktiv den Bus geweckt hat";
CM_ SG_ 2600468548 NM_Ladegeraet_CBV_CRI "Das Signal ist dauerhaft gesetzt, wenn das NM-Layout dem neuen NM-Layout für Teilnetzbetrieb entspricht";
CM_ SG_ 2600468548 NM_Ladegeraet_NM_aktiv_Bere_CVN "Aktiver Nachlauf aufgrund Berechnung des CVN, bei jedem Klemme 15 Wechsel von AUS-->AN 
Dauer ca. 30s";
CM_ SG_ 2600468548 NM_Ladegeraet_NM_aktiv_CVN_Berec "Berechnung CVN ist aktiv";
CM_ SG_ 2600468548 NM_Ladegeraet_NM_aktiv_Diagnose "Diagnose befindet sich nach VW80124 in einer NonDefaultDiagnostic-Session, z.B. ExtendedDiagnostic-Session";
CM_ SG_ 2600468548 NM_Ladegeraet_NM_aktiv_KL15 "Steuergerät hat KL15-EIN erkannt";
CM_ SG_ 2600468548 NM_Ladegeraet_NM_aktiv_Laden "Bus gefordert bei aktivem Ladevorgang";
CM_ SG_ 2600468548 NM_Ladegeraet_NM_aktiv_Ladezeit "Bus gefordert bei Ladezeitberechnung";
CM_ SG_ 2600468548 NM_Ladegeraet_NM_aktiv_NotlaufSt "Lokaler Nachlauf bei Kl15EIN durch aktivierten Notlauf bei gestecktem oder defekten Steckerkontakt";
CM_ SG_ 2600468548 NM_Ladegeraet_NM_aktiv_Tmin "Mindestaktivzeit ist noch nicht abgelaufen (bei jedem Weckereignis wird die Mindestaktivzeit neu gestartet)";
CM_ SG_ 2600468548 NM_Ladegeraet_NM_aktiv_Vorkondit "Wachhalten aufgrund Vorkonditionierung";
CM_ SG_ 2600468548 NM_Ladegeraet_NM_State "1 = Zustand Repeat Message (<-- Bus-Sleep Mode)
2 = Zustand Repeat Message (<-- Prepare Bus-Sleep Mode)
4 = Zustand Normal Operation (<-- Repeat Message)
8 = Zustand Normal Operation (<-- Ready Sleep)";
CM_ SG_ 2600468548 NM_Ladegeraet_SNI "Source Node-Identifier (SNI) identifiziert den Sender der NM-Botschaft (Knotenadresse) eindeutig im Fahrzeug";
CM_ SG_ 2600468548 NM_Ladegeraet_UDS_CC "Funktionseinschränkung aufgrund aktivem UDS-Communication Control; siehe VW80124";

CM_ SG_ 2600468678 NM_Ladegeraet_2_CAB "CAB = Clusteraktivbits";
CM_ SG_ 2600468678 NM_Ladegeraet_2_Car_Wakeup "Car Wakeup (Gateway wertet aus)
MQB: Ladestecker gesteckt, entfernt, verriegelt oder entriegelt";
CM_ SG_ 2600468678 NM_Ladegeraet_2_CBV_AWB "Das Signal ist zu setzen, wenn das SG aktiv den Bus geweckt hat";
CM_ SG_ 2600468678 NM_Ladegeraet_2_CBV_CRI "Das Signal ist dauerhaft gesetzt, wenn das NM-Layout dem neuen NM-Layout für Teilnetzbetrieb entspricht";
CM_ SG_ 2600468678 NM_Ladegeraet_2_NM_aktiv_Diag "Diagnose befindet sich nach VW80124 in einer NonDefaultDiagnostic-Session, z.B. ExtendedDiagnostic-Session";
CM_ SG_ 2600468678 NM_Ladegeraet_2_NM_aktiv_KL15 "Steuergerät hat KL15-EIN erkannt";
CM_ SG_ 2600468678 NM_Ladegeraet_2_NM_aktiv_Laden "Bus gefordert bei aktivem Ladevorgang";
CM_ SG_ 2600468678 NM_Ladegeraet_2_NM_aktiv_Tmin "Mindestaktivzeit ist noch nicht abgelaufen (bei jedem Weckereignis wird die Mindestaktivzeit neu gestartet)";
CM_ SG_ 2600468678 NM_Ladegeraet_2_NM_State "1 = Zustand Repeat Message (<-- Bus-Sleep Mode)
2 = Zustand Repeat Message (<-- Prepare Bus-Sleep Mode)
4 = Zustand Normal Operation (<-- Repeat Message)
8 = Zustand Normal Operation (<-- Ready Sleep)";
CM_ SG_ 2600468678 NM_Ladegeraet_2_SNI "Source Node-Identifier (SNI) identifiziert den Sender der NM-Botschaft (Knotenadresse) eindeutig im Fahrzeug";
CM_ SG_ 2600468678 NM_Ladegeraet_2_UDS_CC "Funktionseinschränkung aufgrund aktivem UDS-Communication Control; siehe VW80124";

CM_ SG_ 2600468481 NM_Sekundaer_01_CAB "CAB = Clusteraktivbits";
CM_ SG_ 2600468481 NM_Sekundaer_01_Car_Wakeup "Car Wakeup (Gateway wertet aus)";
CM_ SG_ 2600468481 NM_Sekundaer_01_CBV_AWB "Das Signal ist zu setzen, wenn das SG aktiv den Bus geweckt hat";
CM_ SG_ 2600468481 NM_Sekundaer_01_CBV_CRI "Das Signal ist dauerhaft gesetzt, wenn das NM-Layout dem neuen NM-Layout für Teilnetzbetrieb entspricht";
CM_ SG_ 2600468481 NM_Sekundaer_01_NM_aktiv_Anf_HVK "Anforderung HVK (Nachlaufursache, SG nicht im NM-Zustand 'Ready to Sleep')";
CM_ SG_ 2600468481 NM_Sekundaer_01_NM_aktiv_Diag "Diagnose befindet sich nach VW80124 in einer NonDefaultDiagnostic-Session, z.B. ExtendedDiagnostic-Session";
CM_ SG_ 2600468481 NM_Sekundaer_01_NM_aktiv_KL15 "Steuergerät hat KL15-EIN erkannt";
CM_ SG_ 2600468481 NM_Sekundaer_01_NM_aktiv_Tmin "Mindestaktivzeit ist noch nicht abgelaufen (bei jedem Weckereignis wird die Mindestaktivzeit neu gestartet)";
CM_ SG_ 2600468481 NM_Sekundaer_01_NM_State "1 = Zustand Repeat Message (<-- Bus-Sleep Mode)
2 = Zustand Repeat Message (<-- Prepare Bus-Sleep Mode)
4 = Zustand Normal Operation (<-- Repeat Message)
8 = Zustand Normal Operation (<-- Ready Sleep)
16 = Zustand Repeat Message (<-- Normal Operation)";
CM_ SG_ 2600468481 NM_Sekundaer_01_SNI "Source Node-Identifier (SNI) identifiziert den Sender der NM-Botschaft (Knotenadresse) eindeutig im Fahrzeug";
CM_ SG_ 2600468481 NM_Sekundaer_01_UDS_CC "Funktionseinschränkung aufgrund aktivem UDS-Communication Control; siehe VW80124";

CM_ SG_ 2600468483 NM_Sekundaer_03_CAB "CAB = Clusteraktivbits";
CM_ SG_ 2600468483 NM_Sekundaer_03_Car_Wakeup "Car Wakeup (Gateway wertet aus)";
CM_ SG_ 2600468483 NM_Sekundaer_03_CBV_AWB "Das Signal ist zu setzen, wenn das SG aktiv den Bus geweckt hat";
CM_ SG_ 2600468483 NM_Sekundaer_03_CBV_CRI "Das Signal ist dauerhaft gesetzt, wenn das NM-Layout dem neuen NM-Layout für Teilnetzbetrieb entspricht";
CM_ SG_ 2600468483 NM_Sekundaer_03_NM_aktiv_Anf_HVK "Anforderung HVK (Nachlaufursache, SG nicht im NM-Zustand 'Ready to Sleep')";
CM_ SG_ 2600468483 NM_Sekundaer_03_NM_aktiv_Diagnos "Diagnose befindet sich nach VW80124 in einer NonDefaultDiagnostic-Session, z.B. ExtendedDiagnostic-Session";
CM_ SG_ 2600468483 NM_Sekundaer_03_NM_aktiv_KL15 "Steuergerät hat KL15-EIN erkannt";
CM_ SG_ 2600468483 NM_Sekundaer_03_NM_aktiv_Tmin "Mindestaktivzeit ist noch nicht abgelaufen (bei jedem Weckereignis wird die Mindestaktivzeit neu gestartet)";
CM_ SG_ 2600468483 NM_Sekundaer_03_NM_State "1 = Zustand Repeat Message (<-- Bus-Sleep Mode)
2 = Zustand Repeat Message (<-- Prepare Bus-Sleep Mode)
4 = Zustand Normal Operation (<-- Repeat Message)
8 = Zustand Normal Operation (<-- Ready Sleep)
16 = Zustand Repeat Message (<-- Normal Operation)";
CM_ SG_ 2600468483 NM_Sekundaer_03_SNI "Source Node-Identifier (SNI) identifiziert den Sender der NM-Botschaft (Knotenadresse) eindeutig im Fahrzeug";
CM_ SG_ 2600468483 NM_Sekundaer_03_UDS_CC "Funktionseinschränkung aufgrund aktivem UDS-Communication Control; siehe VW80124";

CM_ SG_ 2600468553 NM_Sub_Gateway_CAB "CAB = Clusteraktivbits";
CM_ SG_ 2600468553 NM_Sub_Gateway_Car_Wakeup "Car Wakeup (Gateway wertet aus)";
CM_ SG_ 2600468553 NM_Sub_Gateway_CBV_AWB "Das Signal ist zu setzen, wenn das SG aktiv den Bus geweckt hat";
CM_ SG_ 2600468553 NM_Sub_Gateway_CBV_CRI "Das Signal ist dauerhaft gesetzt, wenn das NM-Layout dem neuen NM-Layout für Teilnetzbetrieb entspricht";
CM_ SG_ 2600468553 NM_Sub_Gateway_NM_aktiv_Diagnose "Diagnose befindet sich nach VW80124 in einer NonDefaultDiagnostic-Session, z.B. ExtendedDiagnostic-Session";
CM_ SG_ 2600468553 NM_Sub_Gateway_NM_aktiv_KL15 "Steuergerät hat KL15-EIN erkannt";
CM_ SG_ 2600468553 NM_Sub_Gateway_NM_aktiv_Tmin "Mindestaktivzeit ist noch nicht abgelaufen (bei jedem Weckereignis wird die Mindestaktivzeit neu gestartet)";
CM_ SG_ 2600468553 NM_Sub_Gateway_NM_State "1 = Zustand Repeat Message (<-- Bus-Sleep Mode)
2 = Zustand Repeat Message (<-- Prepare Bus-Sleep Mode)
4 = Zustand Normal Operation (<-- Repeat Message)
8 = Zustand Normal Operation (<-- Ready Sleep)
16 = Zustand Repeat Message (<-- Ready Sleep)
32 ";
CM_ SG_ 2600468553 NM_Sub_Gateway_SNI "Source Node-Identifier (SNI) identifiziert den Sender der NM-Botschaft (Knotenadresse) eindeutig im Fahrzeug";
CM_ SG_ 2600468553 NM_Sub_Gateway_UDS_CC "Funktionseinschränkung aufgrund aktivem UDS-Communication Control; siehe VW80124";

CM_ SG_ 2600468546 NM_TME_CAB "CAB = Clusteraktivbits";
CM_ SG_ 2600468546 NM_TME_Car_Wakeup "Car Wakeup (Gateway wertet aus)";
CM_ SG_ 2600468546 NM_TME_CBV_AWB "Das Signal ist zu setzen, wenn das SG aktiv den Bus geweckt hat
0 = Passiver_WakeUp = SG hat das Netzwerk nicht aktiv geweckt
1 = Akitiver_WakeUp = SG hat das Netzwerk aktiv geweckt";
CM_ SG_ 2600468546 NM_TME_CBV_CRI "Das Signal ist dauerhaft gesetzt, wenn das NM-Layout Cluster- Anforderungen enthält";
CM_ SG_ 2600468546 NM_TME_NM_aktiv_Berechnung "Berechnung für Vorkonditionierung aktiv";
CM_ SG_ 2600468546 NM_TME_NM_aktiv_Diagnose "Diagnose befindet sich nach VW80124 in einer NonDefaultDiagnostic-Session, z.B. ExtendedDiagnostic-Session";
CM_ SG_ 2600468546 NM_TME_NM_aktiv_HV_Auszeitber "Nachlauf aufgrund HV Auszeitberechnung ";
CM_ SG_ 2600468546 NM_TME_NM_aktiv_KL15 "Steuergerät hat KL15-EIN erkannt";
CM_ SG_ 2600468546 NM_TME_NM_aktiv_Kuehlung "Nachlaufkühlung der E-Maschinen";
CM_ SG_ 2600468546 NM_TME_NM_aktiv_NT_Pumpe "Nachlauf NT-Pumpe";
CM_ SG_ 2600468546 NM_TME_NM_aktiv_Tmin "Mindestaktivzeit ist noch nicht abgelaufen (bei jedem Weckereignis wird die Mindestaktivzeit neu gestartet)";
CM_ SG_ 2600468546 NM_TME_NM_aktiv_Ventilsteuerung "Ventilsteuerung vor Abschaltung";
CM_ SG_ 2600468546 NM_TME_NM_aktiv_Vorkondition "Vorkonditionierung aktiv";
CM_ SG_ 2600468546 NM_TME_NM_State "1 = Zustand Repeat Message (<-- Bus-Sleep Mode)
2 = Zustand Repeat Message (<-- Prepare Bus-Sleep Mode)
4 = Zustand Normal Operation (<-- Repeat Message)
8 = Zustand Normal Operation (<-- Ready Sleep)";
CM_ SG_ 2600468546 NM_TME_SNI "Source Node-Identifier (SNI) identifiziert den Sender der NM-Botschaft (Knotenadresse) eindeutig im Fahrzeug";
CM_ SG_ 2600468546 NM_TME_UDS_CC "Funktionseinschränkung aufgrund aktivem UDS-Communication Control, siehe VW80124";

CM_ SG_ 1635 BEM_02_Abschaltstufen "Abschaltstufen des Ruhestrommanagements (Initialisierungswert aus EEprom)

Stufe 0 (keine Einschraenkungen)
Stufe 1 (Abschaltung Hochstromverbraucher)
Stufe 2 (Infotainmentabschaltung)
Stufe 3 (Wake-Up-Sperre)

Für den Transport- und Ruhestrommessm";
CM_ SG_ 1635 BEM_Anf_KL15_schalten "Abschaltempfehlung bzw. Verhinderung der automatischen Abschaltung Kl15 durch das BCM";
CM_ SG_ 1635 BEM_Batteriediagnose "Anzeige von Textwarnungen";
CM_ SG_ 1635 BEM_Generatordiagnose "Ansteuerung Generatorwarnleuchte im Kombi
";
CM_ SG_ 1635 BEM_HL_Regelung_Status "Status Regelung Heizleistung
";
CM_ SG_ 1635 BEM_Ladezustand "Ladezustand der Niedervoltbatterie
";
CM_ SG_ 1635 BEM_MMI_Vorwarnung "Anzeige Vorwarnung MMI-Abschaltung (Initialisierungswert aus EEprom)
";
CM_ SG_ 1635 BEM_Red_Innengeblaese "Reduzierung Innengebläse
";
CM_ SG_ 1635 BEM_REK_aktiv "Rekuperationsfreigabe vom Energiemanagement
0x0 = keine Rekuperationsfreigabe
0x1 = Rekuperationsfreigabe";
CM_ SG_ 1635 BEM_STH_Einschaltverbot "Einschränkung Standheizung/-lüftung durch BEM: Setzt der BEM das Bit, dann darf die Standheizung nicht mehr einschalten
(Die Standheizung muss aber nicht abschalten, sondern darf weiterbrennen)
(Initialisierungswert aus EEprom)
";
CM_ SG_ 1635 BEM_STH_Zielzeit "Maximal mögliche Zeit für den Standheizungsbetrieb, um die Startfähigkeit nicht zu gefährden";
CM_ SG_ 1635 BEM_UBDM "Batteriespannung, gemessen vom Batteriedatenmodul";
CM_ SG_ 1635 BEM_UGenSoll "Sollspannungsvorgabe an den Generator, beinhaltet temperaturoptimierte Batterieladung und Rekuperation";
CM_ SG_ 1635 MIB_Stromsparmodus "Signal beschreibt die Aktivierung für den Stromsparmodus beim MIB.
Bei AUS (= 0) gibt es keine weitere Anforderung an die MIB-Komponenten.
Bei EIN (= 1) werden alle MIB Komponenten in einen Stromsparmodus versetzt.";
CM_ SG_ 1635 NVEM_Anf_SD_schalten "Anforderung Nachlauf für den Steckdosenbetrieb
Initialisierungswert aus EEprom";
CM_ SG_ 1635 NVEM_Batterie_Service "Anforderung einer Batterie-Service - Anzeige / Anforderung an die Werkstatt über MOD";
CM_ SG_ 1635 NVEM_Freigabe_OnlineUpdate "Freigabe für Online-Update durch Energiemanagement";
CM_ SG_ 1635 NVEM_Freigabe_ORU4 "Bestätigung oder Ablehnung eines konkreten, angefragten Online Updates durch das Energiemanagements";
CM_ SG_ 1635 NVEM_Last_Anf "Das NVEM fordert für die Batteriediagnose einen Lastimpuls vom Fahrzeug an, der durch kontrollierte Verbraucherzuschaltungen (z. B. Aktivierung Heckscheibenheizung) generiert wird";

CM_ SG_ 869 BEM_Anf_KL "Das BEM fordert über das MSG den Kühlerlüfter-Betrieb an; hierzu wird ein minimaler Leistungswert im MSG appliziert. 
Szenario: bei erkannter abgetrennten Batterie soll durch Ansteuerung des Kühlerlüfters das Energienetz stabilisiert werden.";
CM_ SG_ 869 BEM_Batt_Ab "Batterieverbindungskontrolle:
0x0: Batterie am Bordnetz
0x1: Batterie ab erkannt";
CM_ SG_ 869 BEM_DFM "Generatorauslastungsgrad, vom Generator über LIN an das Gateway gesandt. Das Motorsteuergerät regelt auf dieses Signal die PTC, das Energiemanagement im BSG/BCM kalkuliert die Bordnetzauslastung";
CM_ SG_ 869 BEM_HYB_DC_uMinLV "Abregelgrenze: minimal erlaubte Bordnetzspannung im Hochsetzbetrieb (Hybrid)";
CM_ SG_ 869 BEM_HYB_DC_uSollLV "Sollwert für die Bordnetzspannung im Tiefsetzbetrieb vom Traktionsnetz ins Bordnetz (Hybrid)";
CM_ SG_ 869 BEM_Hybrid_Info "Einschränkung des Hybridbetriebs durch Energiemanagement
0 = keine Einschränkung des Hybridbetriebs durch das Energiemanagement [Hybridfreigabe]
1 = Motorstart über 12V-Starter nur bei v = 0 km/h möglich
2 = kein Motorstart über 12V-Starter nach elektr";
CM_ SG_ 869 BEM_n_LLA "Es gilt: Signalspec BEM_n_LLA v1.0

Anforderung einer Leerlaufdrehzahlanhebung in drei Stufen. Die Höhe der jeweiligen LL-Drehzahlstufe ist im Motorsteuergerät appliziert.



";
CM_ SG_ 869 BEM_P_Generator "Es gilt: Signalspec BEM_P_Generator v1.0

Mechanische Generatorleistung dient dem Motorsteuergerät zur Berechnung der Motorlast; Genauigkeit ca. +/- (500W + 20% vom Messwert)

MLBevo: Bei NVEM_P_Generator_Status = 1 wird das Signal ohne Filterung ausg";
CM_ SG_ 869 BEM_StartStopp_Info "Stopp-Freigabe und Start-Anforderung an den Start-Stopp-Koordinator";
CM_ SG_ 869 NVEM_05_BZ "4bit Botschaftszähler, wird mit jeder Sendebotschaft inkrementiert";
CM_ SG_ 869 NVEM_05_CRC "Für MLB:
Berechnung siehe Lastenheft 'Kommunikationsabsicherung für FlexRay und CAN'
Ab MQB und MLBevo:
Berechnung siehe Lastenheft 'End-to-End Kommunikationsabsicherung'

Endwerte siehe Begleitdokument 'S-PDU Kennungsfolgen'";
CM_ SG_ 869 NVEM_Freilauf_Info "Freilauf Informationssignal vom NVEM zum Freilaufkoordinator. Das NVEM kann über dieses Signal den Freilauf freigeben, verhindern bzw. explizit anfordern.";
CM_ SG_ 869 NVEM_P_Generator_Status "Das Signal kennzeichnet ob BEM_P_Generator aktuell gefilterte oder ungefilterte Werte überträgt.";
CM_ SG_ 869 NVEM_Pilot_Info "NVEM Veto bei reduzierter Leistungsfähigkeit des Energienetzes";
CM_ SG_ 869 NVEM_Red_KL "Reduzierung der Kühlerlüfteranforderung durch das NVEM an das MSG bei energetisch kritischen Zuständen während Staupilot";

CM_ SG_ 2527679508 NVEM_06_BZ "4bit Botschaftszähler, wird mit jeder Sendebotschaft inkrementiert";
CM_ SG_ 2527679508 NVEM_06_CRC "Für MLB:
'Berechnung siehe Lastenheft 'Kommunikationsabsicherung für FlexRay und CAN''

Ab MQB und MLBevo:
'Berechnung siehe Lastenheft 'End-to-End Kommunikationsabsicherung''

Endwerte siehe Begleitdokument 'S-PDU Kennungsfolgen'";
CM_ SG_ 2527679508 NVEM_Bordnetzdiagnose "Wird vom NVEM im NV-Netz ein Bordnetz-Fehler erkannt, so soll dies zu einer mehrstufigen Anzeige führen.";
CM_ SG_ 2527679508 NVEM_Energie_Klima_Vorgabe "NVEM-Energievorgabe für Klima-Vorkonditionierung";
CM_ SG_ 2527679508 NVEM_Max_Rampenzeit "Vorgabe der max. Rampenzeit für den Generatorbetrieb des 12V-RSG (RSG-Ansteuerung durch Motor-SG)";
CM_ SG_ 2527679508 NVEM_Max_Spannung "Mild_Hybrid: erlaubte Maximalspannung 12V - Netz
";
CM_ SG_ 2527679508 NVEM_Min_Spannung "Mild_Hybrid: erforderliche Mindestspannung 12V - Netz";
CM_ SG_ 2527679508 NVEM_Min_Spannung_Start "Minimale einzuhaltende Spannung im RSG Wiederstart";
CM_ SG_ 2527679508 NVEM_MV_DC_uMinLV "Abregelgrenze: minimal erlaubte Bordnetzspannung im Hochsetzbetrieb vom 12V-Bordnetz ins 48V-Netz";
CM_ SG_ 2527679508 NVEM_MV_DC_uSollLV "Sollwert für die 12V-Bordnetzspannung im Tiefsetzbetrieb vom 48V-Netz ins 12V-Bordnetz";

CM_ SG_ 2527679509 NVEM_07_BZ "Fortlaufender Botschaftszaehler";
CM_ SG_ 2527679509 NVEM_07_CRC "Für MLB:
'Berechnung siehe Lastenheft 'Kommunikationsabsicherung für FlexRay und CAN''

Ab MQB und MLBevo:
'Berechnung siehe Lastenheft 'End-to-End Kommunikationsabsicherung''

Endwerte siehe Begleitdokument 'S-PDU Kennungsfolgen'";
CM_ SG_ 2527679509 NVEM_BMS_NV_Imax_RSG_Anf "prädizierter RSG-Verbrauchsstrom während des 12V-Zustarts";
CM_ SG_ 2527679509 NVEM_BMS_NV_Impuls_Abfrage "Trigger zur Lieferung aktueller Daten und Initialisierung der Schleppzeiger für die Signale UMinStart und IMaxStart.";
CM_ SG_ 2527679509 NVEM_BMS_NV_Nachlaufzeit_Vorgabe "Zeitvorgabe bis zum Öffnen des Trennelements";
CM_ SG_ 2527679509 NVEM_BMS_NV_Sollmodus "Anforderung Trennelement oeffnen/ schliessen";
CM_ SG_ 2527679509 NVEM_BMS_NV_Umin_Anf "erforderliche Mindestspannung für die Berechnung des Signals BMS_NV_Qe_Li_Inhalt";
CM_ SG_ 2527679509 NVEM_BMS_NV_Umin_RSG_Anf "erforderliche Mindestspannung beim RSG-Zustart für die Berechnung des Signals BMS_NV_Qe_Li_Inhalt";
CM_ SG_ 2527679509 NVEM_FMAus_I_Verbrauch "Predezierter Bordneztstromverbrauch während der Freilauf Motor Aus Phase.";

CM_ SG_ 527 NVEM_DC_iSoll_NV "Soll-Entladestrom 12V Seite des DCDC Wandlers";
CM_ SG_ 527 NVEM_DC_uSoll_NV "Sollspannung 12V Seite des DC Wandlers, feine Auflösung";
CM_ SG_ 527 NVEM_MOD_Budget "Füllstand des NV - Energie-Budgets für MD4";
CM_ SG_ 527 NVEM_MOD_Freigabe "Energiefreigabe für MOD  Funktionen";

CM_ SG_ 913 MO_QBit_Aussen_Temp "QBit der Aussentemperatur. Gesetzt bei Ersatzwert, Init oder Fehler.";
CM_ SG_ 913 MO_Servicemodus "Ausgabe aktiver Service-Mode";
CM_ SG_ 913 OBD_Abs_Load_Val "Absolute Load Value

Übertragung von Meßgrößen an das Getriebesteuergerät für Freeze Frame Abspeicherung bei Getriebefehlern

PID $43 Absolute Load Value; 0 .. 25700%  mit 100/255 %/bit";
CM_ SG_ 913 OBD_Abs_Pedal_Pos "Absolute Pedal Position

Übertragung von Meßgrößen an das Getriebesteuergerät für Freeze Frame Abspeicherung bei Getriebefehlern

PID $49 Accelerator Pedal Position D; 0 .. 100% mit 100/255 %/bit";
CM_ SG_ 913 OBD_Abs_Throttle_Pos "Absolute Throttle Position

Übertragung von Meßgrößen an das Getriebesteuergerät für Freeze Frame Abspeicherung bei Getriebefehlern

PID $11 Absolute Throttle Position; 0 .. 100% mit 100/255 %/bit";
CM_ SG_ 913 OBD_Calc_Load_Val "Calculated Load Value

Übertragung von Meßgrößen an das Getriebesteuergerät für Freeze Frame Abspeicherung bei Getriebefehlern

PID $04 Calculated Load Value; 0 .. 100% mit 100/255 % per bit
";
CM_ SG_ 913 OBD_ClearMem_Inhibit "Bei FSP_Loeschen_zulässig müssen alle OBD-ECUs im Gesamtfahrzeug einen Service 04hex Request (Ereignisspeicher löschen) korrekt ausführen. 

In MLB-, MLBevo-, MQB-Fahrzeugkonzepten muss der MIL-Master/Motorsteuergerät bei Kl.15 ein, projektabhängig, kon";
CM_ SG_ 913 OBD_Driving_Cycle "Signalisierung Driving Cycle Qualifizierung - Trigger Ignition Cycle Counter";
CM_ SG_ 913 OBD_Eng_Cool_Temp "Engine Coolant Temperature

Übertragung von Meßgrößen an das Getriebesteuergerät für Freeze Frame Abspeicherung bei Getriebefehlern

PID $05 Engine Coolant Temperature; -40 .. +215°C mit 1°C/bit und 40°C Offset";
CM_ SG_ 913 OBD_Kaltstart_Denominator "Bestimmte Diagnosen werden nur unter Kaltstartbedingungen durchgeführt, der entsprechende Denominator bei IUMPR-pflichtigen Systemen wird anhand dieses vom MSG gebildeten Signals inkrementiert. (Entspricht EVAP-Denominator)";
CM_ SG_ 913 OBD_Minimum_Trip "Grundlage OBD-Gesetz CCR 1968.2 (d)(4.3) Denominator Specifications
Bildung des General Denominator 'Normed Trip':
 600 sec. (kumulativ) Zeit nach Motorstart
 300 sec. (kumulativ) mit Fahrzeuggeschwindigkeit > 25 mph (40 km/h)
 30 sec. (kontinuierlich";
CM_ SG_ 913 OBD_Normed_Trip "Gesetzlich definierte 'Normed Condition' erfüllt, 'General Denominator' darf erhöht werden";
CM_ SG_ 913 OBD_Sperrung_IUMPR "Wenn der General Denominator auf Grund eines Fehlers in den Eingangsgrößen gesperrt wird, wird diese Information über Bussystem als OBD-Statusinformation OBD_Sperrung_IUMPR für andere OBD-Steuergeräte bereitgestellt. 

Das MSG (MIL-Master) setzt dieses ";
CM_ SG_ 913 OBD_Sperrung_Kaltstart_Denom "Information vom MIL Master, dass die Bildung des EVAP Denominators  im Motor nicht möglich ist und damit der noECM-Denominator gesperrt werden darf.";
CM_ SG_ 913 OBD_Warm_Up_Cycle "Mit dem Warm-Up-Cycle wird der zentrale Verlernzähler vom Gateway inkrementiert";

CM_ SG_ 2589283478 OBD_Aussen_Temp_gef "Gefilterte Aussentemperatur vom Motor für OBD Funktionen.";

CM_ SG_ 2549875343 OBDC_AWC_Req_Data "OnBoard Tester Diagnose Request AWC";

CM_ SG_ 2550006415 OBDC_AWC_Resp_Data "OnBoard Tester Diagnose Response AWC";

CM_ SG_ 2549875356 OBDC_BMS_48V_Req_Data "OnBoard Tester Diagnose Request BMS_48V";

CM_ SG_ 2549875399 OBDC_DCDC_HV_02_Req_Data "TP-Kanal für den Onboard Datensammler";

CM_ SG_ 2550006471 OBDC_DCDC_HV_02_Resp_Data "TP-Kanal für den Onboard Datensammler";

CM_ SG_ 2549875407 OBDC_DCDC_HV_03_Req_Data "TP-Kanal für den Onboard Datensammler";

CM_ SG_ 2550006479 OBDC_DCDC_HV_03_Resp_Data "TP-Kanal für den Onboard Datensammler";

CM_ SG_ 2549875383 OBDC_DCDC_HV_Req_Data "TP-Kanal für den Onboard Datensammler";

CM_ SG_ 2550006455 OBDC_DCDC_HV_Resp_Data "TP-Kanal für den Onboard Datensammler";

CM_ SG_ 2549875265 OBDC_DCDC_Req_Data "OnBoard Tester Diagnose Request DCDC";

CM_ SG_ 2550006337 OBDC_DCDC_Resp_Data "TP-Kanal für den Onboard Datensammler";

CM_ SG_ 2549875381 OBDC_FCU_Req_Data "TP-Kanal für den Onboard Datensammler";

CM_ SG_ 2550006453 OBDC_FCU_Resp_Data "TP-Kanal für den Onboard Datensammler";

CM_ SG_ 2549940736 OBDC_Funktionaler_Req_All_Data "VDC funktionaler Request auf CANHS";

CM_ SG_ 2549875323 OBDC_Hybrid_01_Req_Data "OnBoard Tester Diagnose Request Hybrid_01";

CM_ SG_ 2549875398 OBDC_Ladegeraet_2_Req_Data "TP-Kanal für den Onboard Datensammler";

CM_ SG_ 2550006470 OBDC_Ladegeraet_2_Resp_Data "TP-Kanal für den Onboard Datensammler";

CM_ SG_ 2549903568 OBDC_SSN_BJB_Req_Data "OnBoard Tester Diagnose Request BJB";

CM_ SG_ 2550034640 OBDC_SSN_BJB_Resp_Data "OnBoard Tester Diagnose Response BJB";

CM_ SG_ 2549903569 OBDC_SSN_CMC_01_Req_Data "Request FID- zu NA- Kommunikation zw. OnboardDiagnoseClient und DK2F Sub-System-Knoten CMC_01 ... 16";

CM_ SG_ 2550034641 OBDC_SSN_CMC_01_Resp_Data "Response FID- zu NA- Kommunikation zw. OnboardDiagnoseClient und DK2F Sub-System-Knoten CMC_01 ... 16";

CM_ SG_ 2549903570 OBDC_SSN_CMC_02_Req_Data "Request FID- zu NA- Kommunikation zw. OnboardDiagnoseClient und DK2F Sub-System-Knoten CMC_01 ... 16";

CM_ SG_ 2550034642 OBDC_SSN_CMC_02_Resp_Data "Response FID- zu NA- Kommunikation zw. OnboardDiagnoseClient und DK2F Sub-System-Knoten CMC_01 ... 16";

CM_ SG_ 2549903571 OBDC_SSN_CMC_03_Req_Data "Request FID- zu NA- Kommunikation zw. OnboardDiagnoseClient und DK2F Sub-System-Knoten CMC_01 ... 16";

CM_ SG_ 2550034643 OBDC_SSN_CMC_03_Resp_Data "Response FID- zu NA- Kommunikation zw. OnboardDiagnoseClient und DK2F Sub-System-Knoten CMC_01 ... 16";

CM_ SG_ 2549903572 OBDC_SSN_CMC_04_Req_Data "Request FID- zu NA- Kommunikation zw. OnboardDiagnoseClient und DK2F Sub-System-Knoten CMC_01 ... 16";
BA_DEF_ BO_  "DiagRequest" ENUM "No", "Yes";
BA_DEF_ BO_  "DiagResponse" ENUM "No", "Yes";
BA_DEF_ BO_  "DiagState" ENUM "No", "Yes";
BA_DEF_ BO_  "GenMsgChkConstant" HEX 0 4095;
BA_DEF_ BO_  "GenMsgCycleTime" INT 0 65535;
BA_DEF_ BO_  "GenMsgCycleTimeFast" INT 0 65535;
BA_DEF_ BO_  "GenMsgDelayTime" INT 0 100000;
BA_DEF_ BO_  "GenMsgILSupport" ENUM "No", "Yes";
BA_DEF_ BO_  "GenMsgNrOfRepetition" INT 0 100;
BA_DEF_ BO_  "GenMsgPDUConstants" STRING;
BA_DEF_ BO_  "GenMsgSendType" ENUM "Cyclic", "not_used", "not_used", "not_used", "not_used", "not_used", "not_used", "IfActive", "NoMsgSendType";
BA_DEF_ BO_  "GenMsgStartDelayTime" INT 0 100000;
BA_DEF_ BO_  "NmMessage" ENUM "No", "Yes";
BA_DEF_ BO_  "NmhMessage" ENUM "No", "Yes";
BA_DEF_ BO_  "MsgType" ENUM "Application", "NM ", "NMH", "TP2.0", "ISO-TP ", "BAP", "EID", "KS", "XCP_PRE_CONFIGURED", "XCP_RUNTIME_CONFIGURED";
BA_DEF_ BO_  "VAGTP20_API" HEX 0 255;
BA_DEF_ BO_  "VAGTP20_DynConnection" ENUM "No", "Yes";
BA_DEF_ BO_  "VAGTP20_DynSetup" ENUM "No", "Yes";
BA_DEF_ BO_  "VAGTP20_StatConnection" ENUM "No", "Yes";
BA_DEF_ SG_  "GenSigActiveRepetitions" INT -2147483648 2147483647;
BA_DEF_ SG_  "GenSigInactiveValue" INT -2147483648 2147483647;
BA_DEF_ SG_  "GenSigSendType" ENUM "Cyclic", "OnWrite", "OnWriteWithRepetition", "OnChange", "OnChangeWithRepetition", "IfActive", "IfActiveWithRepetition", "NoSigSendType", "OnChangeAndIfActive", "OnChangeAndIfActiveWithRepetition";
BA_DEF_ SG_  "GenSigStartValue" INT -2147483648 2147483647;
BA_DEF_ SG_  "NWM-WakeupAllowed" ENUM "No", "Yes";
BA_DEF_ SG_  "GenSigFuncType" ENUM "NoFunction", "MsgCounter", "CRC-8", "XOR", "XOR-2", "DatedBit", "SW-Kl15", "CHK", "Constant", "Protocol", "CRC-8-SAE_J1850", "CRC-32", "DataLength", "DataID", "MsgCounter16", "SOK-Signatur", "Cluster";
BA_DEF_ SG_  "GenSigSwitchedByIgnition" ENUM "No", "Yes";
BA_DEF_ SG_  "Fehlerwert" HEX 0 2147483647;
BA_DEF_ SG_  "GenSigMissingSourceValue" HEX 0 2147483647;
BA_DEF_DEF_  "DiagRequest" "No";
BA_DEF_DEF_  "DiagResponse" "No";
BA_DEF_DEF_  "DiagState" "No";
BA_DEF_DEF_  "GenMsgChkConstant" 0;
BA_DEF_DEF_  "GenMsgCycleTime" 0;
BA_DEF_DEF_  "GenMsgCycleTimeFast" 0;
BA_DEF_DEF_  "GenMsgDelayTime" 0;
BA_DEF_DEF_  "GenMsgILSupport" "No";
BA_DEF_DEF_  "GenMsgNrOfRepetition" 0;
BA_DEF_DEF_  "GenMsgPDUConstants" "";
BA_DEF_DEF_  "GenMsgSendType" "NoMsgSendType";
BA_DEF_DEF_  "GenMsgStartDelayTime" 0;
BA_DEF_DEF_  "NmMessage" "No";
BA_DEF_DEF_  "NmhMessage" "No";
BA_DEF_DEF_  "MsgType" "Application";
BA_DEF_DEF_  "VAGTP20_API" 0;
BA_DEF_DEF_  "VAGTP20_DynConnection" "No";
BA_DEF_DEF_  "VAGTP20_DynSetup" "No";
BA_DEF_DEF_  "VAGTP20_StatConnection" "No";
BA_DEF_DEF_  "GenSigActiveRepetitions" 0;
BA_DEF_DEF_  "GenSigInactiveValue" 0;
BA_DEF_DEF_  "GenSigSendType" "NoSigSendType";
BA_DEF_DEF_  "GenSigStartValue" 0;
BA_DEF_DEF_  "NWM-WakeupAllowed" "No";
BA_DEF_DEF_  "GenSigFuncType" "NoFunction";
BA_DEF_DEF_  "GenSigSwitchedByIgnition" "Yes";
BA_DEF_DEF_  "Fehlerwert" 0;
BA_DEF_DEF_  "GenSigMissingSourceValue" 0;
BA_ "GenMsgCycleTime" BO_ 2589283481 500;
BA_ "GenMsgILSupport" BO_ 2589283481 1;
BA_ "GenMsgSendType" BO_ 2589283481 0;
BA_ "GenMsgCycleTime" BO_ 160 100;
BA_ "GenMsgILSupport" BO_ 160 1;
BA_ "GenMsgPDUConstants" BO_ 160 "0x4a,0xb4,0xe8,0x24,0x99,0x5a,0x59,0x8b,0x1e,0xaa,0x94,0xb6,0x09,0xd5,0xaf,0x97";
BA_ "GenMsgSendType" BO_ 160 0;
BA_ "GenMsgCycleTime" BO_ 1600 320;
BA_ "GenMsgILSupport" BO_ 1600 1;
BA_ "GenMsgSendType" BO_ 1600 0;
BA_ "GenMsgCycleTime" BO_ 1607 320;
BA_ "GenMsgILSupport" BO_ 1607 1;
BA_ "GenMsgSendType" BO_ 1607 0;
BA_ "GenMsgCycleTime" BO_ 168 10;
BA_ "GenMsgILSupport" BO_ 168 1;
BA_ "GenMsgPDUConstants" BO_ 168 "0x52,0x8c,0x50,0xee,0x4f,0xa6,0xcc,0xcf,0x7d,0x2f,0x98,0x6b,0x27,0x41,0x9f,0x93";
BA_ "GenMsgSendType" BO_ 168 0;
BA_ "GenMsgCycleTime" BO_ 958 100;
BA_ "GenMsgDelayTime" BO_ 958 10;
BA_ "GenMsgILSupport" BO_ 958 1;
BA_ "GenMsgPDUConstants" BO_ 958 "0x1f,0x28,0xc6,0x85,0xe6,0xf8,0xb0,0x19,0x5b,0x64,0x35,0x21,0xe4,0xf7,0x9c,0x24";
BA_ "GenMsgSendType" BO_ 958 0;
BA_ "GenMsgCycleTime" BO_ 812 200;
BA_ "GenMsgDelayTime" BO_ 812 40;
BA_ "GenMsgILSupport" BO_ 812 1;
BA_ "GenMsgSendType" BO_ 812 0;
BA_ "GenMsgCycleTime" BO_ 1648 500;
BA_ "GenMsgDelayTime" BO_ 1648 20;
BA_ "GenMsgILSupport" BO_ 1648 1;
BA_ "GenMsgSendType" BO_ 1648 0;
BA_ "GenMsgCycleTime" BO_ 289 1000;
BA_ "GenMsgILSupport" BO_ 289 1;
BA_ "GenMsgPDUConstants" BO_ 289 "0xe9,0x65,0xae,0x6b,0x7b,0x35,0xe5,0x5f,0x4e,0xc7,0x86,0xa2,0xbb,0xdd,0xeb,0xb4";
BA_ "GenMsgSendType" BO_ 289 0;
BA_ "GenMsgCycleTime" BO_ 1423 320;
BA_ "GenMsgILSupport" BO_ 1423 1;
BA_ "GenMsgSendType" BO_ 1423 0;
BA_ "GenMsgCycleTime" BO_ 967 80;
BA_ "GenMsgILSupport" BO_ 967 1;
BA_ "GenMsgSendType" BO_ 967 0;
BA_ "GenMsgCycleTime" BO_ 340 200;
BA_ "GenMsgILSupport" BO_ 340 1;
BA_ "GenMsgPDUConstants" BO_ 340 "0x21,0x93,0x4a,0x04,0x5c,0x18,0xe0,0x69,0x14,0xce,0x26,0x8f,0x5e,0xb1,0xdf,0x53";
BA_ "GenMsgSendType" BO_ 340 0;
BA_ "GenMsgCycleTime" BO_ 1366 960;
BA_ "GenMsgILSupport" BO_ 1366 1;
BA_ "GenMsgSendType" BO_ 1366 0;
BA_ "GenMsgCycleTime" BO_ 283 500;
BA_ "GenMsgDelayTime" BO_ 283 10;
BA_ "GenMsgILSupport" BO_ 283 1;
BA_ "GenMsgSendType" BO_ 283 0;
BA_ "GenMsgCycleTime" BO_ 2527679581 320;
BA_ "GenMsgILSupport" BO_ 2527679581 1;
BA_ "GenMsgSendType" BO_ 2527679581 0;
BA_ "GenMsgCycleTime" BO_ 377 100;
BA_ "GenMsgDelayTime" BO_ 377 10;
BA_ "GenMsgILSupport" BO_ 377 1;
BA_ "GenMsgSendType" BO_ 377 0;
BA_ "GenMsgCycleTime" BO_ 2331595979 40;
BA_ "GenMsgILSupport" BO_ 2331595979 1;
BA_ "GenMsgSendType" BO_ 2331595979 0;
BA_ "GenMsgCycleTime" BO_ 2589283599 960;
BA_ "GenMsgDelayTime" BO_ 2589283599 160;
BA_ "GenMsgILSupport" BO_ 2589283599 1;
BA_ "GenMsgSendType" BO_ 2589283599 0;
BA_ "GenMsgCycleTime" BO_ 2527679913 320;
BA_ "GenMsgILSupport" BO_ 2527679913 1;
BA_ "GenMsgSendType" BO_ 2527679913 0;
BA_ "GenMsgChkConstant" BO_ 1601 71;
BA_ "GenMsgCycleTime" BO_ 1601 960;
BA_ "GenMsgILSupport" BO_ 1601 1;
BA_ "GenMsgPDUConstants" BO_ 1601 "0x47,0x47,0x47,0x47,0x47,0x47,0x47,0x47,0x47,0x47,0x47,0x47,0x47,0x47,0x47,0x47";
BA_ "GenMsgSendType" BO_ 1601 0;
BA_ "GenMsgCycleTime" BO_ 220 10;
BA_ "GenMsgILSupport" BO_ 220 1;
BA_ "GenMsgSendType" BO_ 220 0;
BA_ "GenMsgCycleTime" BO_ 2463978654 40;
BA_ "GenMsgILSupport" BO_ 2463978654 1;
BA_ "GenMsgSendType" BO_ 2463978654 0;
BA_ "GenMsgCycleTime" BO_ 305 500;
BA_ "GenMsgILSupport" BO_ 305 1;
BA_ "GenMsgSendType" BO_ 305 0;
BA_ "GenMsgCycleTime" BO_ 394 200;
BA_ "GenMsgDelayTime" BO_ 394 10;
BA_ "GenMsgILSupport" BO_ 394 1;
BA_ "GenMsgSendType" BO_ 394 0;
BA_ "GenMsgStartDelayTime" BO_ 394 20;
BA_ "GenMsgCycleTime" BO_ 339 200;
BA_ "GenMsgDelayTime" BO_ 339 10;
BA_ "GenMsgILSupport" BO_ 339 1;
BA_ "GenMsgPDUConstants" BO_ 339 "0x03,0x13,0x23,0x7a,0x40,0x51,0x68,0xba,0xa8,0xbe,0x55,0x02,0x11,0x31,0x76,0xec";
BA_ "GenMsgSendType" BO_ 339 0;
BA_ "GenMsgStartDelayTime" BO_ 339 20;
BA_ "GenMsgCycleTime" BO_ 1434 80;
BA_ "GenMsgILSupport" BO_ 1434 1;
BA_ "GenMsgSendType" BO_ 1434 0;
BA_ "GenMsgCycleTime" BO_ 689 40;
BA_ "GenMsgILSupport" BO_ 689 1;
BA_ "GenMsgSendType" BO_ 689 0;
BA_ "GenMsgCycleTime" BO_ 931 80;
BA_ "GenMsgILSupport" BO_ 931 1;
BA_ "GenMsgSendType" BO_ 931 0;
BA_ "GenMsgStartDelayTime" BO_ 931 320;
BA_ "GenMsgCycleTime" BO_ 2589283456 320;
BA_ "GenMsgILSupport" BO_ 2589283456 1;
BA_ "GenMsgSendType" BO_ 2589283456 0;
BA_ "GenMsgStartDelayTime" BO_ 2589283456 50;
BA_ "GenMsgCycleTime" BO_ 2463978826 100;
BA_ "GenMsgILSupport" BO_ 2463978826 1;
BA_ "GenMsgSendType" BO_ 2463978826 0;
BA_ "GenMsgCycleTime" BO_ 1284 100;
BA_ "GenMsgDelayTime" BO_ 1284 10;
BA_ "GenMsgILSupport" BO_ 1284 1;
BA_ "GenMsgPDUConstants" BO_ 1284 "0x03,0x63,0x3e,0x04,0xf9,0xb4,0x4f,0x32,0x25,0x56,0x1e,0xc1,0x83,0xfa,0x31,0x97";
BA_ "GenMsgSendType" BO_ 1284 0;
BA_ "GenMsgStartDelayTime" BO_ 1284 10;
BA_ "GenMsgCycleTime" BO_ 1157 1000;
BA_ "GenMsgILSupport" BO_ 1157 1;
BA_ "GenMsgSendType" BO_ 1157 0;
BA_ "GenMsgCycleTime" BO_ 1158 1000;
BA_ "GenMsgILSupport" BO_ 1158 1;
BA_ "GenMsgSendType" BO_ 1158 0;
BA_ "GenMsgCycleTime" BO_ 2589283496 500;
BA_ "GenMsgILSupport" BO_ 2589283496 1;
BA_ "GenMsgSendType" BO_ 2589283496 0;
BA_ "GenMsgCycleTime" BO_ 2600468623 200;
BA_ "GenMsgCycleTimeFast" BO_ 2600468623 10;
BA_ "GenMsgSendType" BO_ 2600468623 7;
BA_ "NmhMessage" BO_ 2600468623 1;
BA_ "MsgType" BO_ 2600468623 2;
BA_ "GenMsgCycleTime" BO_ 2600468654 200;
BA_ "GenMsgCycleTimeFast" BO_ 2600468654 10;
BA_ "GenMsgSendType" BO_ 2600468654 7;
BA_ "NmhMessage" BO_ 2600468654 1;
BA_ "MsgType" BO_ 2600468654 2;
BA_ "GenMsgCycleTime" BO_ 2600468636 200;
BA_ "GenMsgCycleTimeFast" BO_ 2600468636 10;
BA_ "GenMsgSendType" BO_ 2600468636 7;
BA_ "NmhMessage" BO_ 2600468636 1;
BA_ "MsgType" BO_ 2600468636 2;
BA_ "GenMsgCycleTime" BO_ 2600468545 200;
BA_ "GenMsgCycleTimeFast" BO_ 2600468545 10;
BA_ "GenMsgSendType" BO_ 2600468545 7;
BA_ "NmhMessage" BO_ 2600468545 1;
BA_ "MsgType" BO_ 2600468545 2;
BA_ "GenMsgCycleTime" BO_ 2600468663 200;
BA_ "GenMsgCycleTimeFast" BO_ 2600468663 10;
BA_ "GenMsgSendType" BO_ 2600468663 7;
BA_ "NmhMessage" BO_ 2600468663 1;
BA_ "MsgType" BO_ 2600468663 2;
BA_ "GenMsgCycleTime" BO_ 2600468679 200;
BA_ "GenMsgCycleTimeFast" BO_ 2600468679 10;
BA_ "GenMsgSendType" BO_ 2600468679 7;
BA_ "NmhMessage" BO_ 2600468679 1;
BA_ "MsgType" BO_ 2600468679 2;
BA_ "GenMsgCycleTime" BO_ 2600468661 200;
BA_ "GenMsgCycleTimeFast" BO_ 2600468661 10;
BA_ "GenMsgSendType" BO_ 2600468661 7;
BA_ "NmhMessage" BO_ 2600468661 1;
BA_ "MsgType" BO_ 2600468661 2;
BA_ "GenMsgCycleTime" BO_ 2600468496 200;
BA_ "GenMsgCycleTimeFast" BO_ 2600468496 10;
BA_ "GenMsgSendType" BO_ 2600468496 7;
BA_ "NmhMessage" BO_ 2600468496 1;
BA_ "MsgType" BO_ 2600468496 2;
BA_ "GenMsgCycleTime" BO_ 2600468603 200;
BA_ "GenMsgCycleTimeFast" BO_ 2600468603 10;
BA_ "GenMsgSendType" BO_ 2600468603 7;
BA_ "NmhMessage" BO_ 2600468603 1;
BA_ "MsgType" BO_ 2600468603 2;
BA_ "GenMsgCycleTime" BO_ 2600468548 200;
BA_ "GenMsgCycleTimeFast" BO_ 2600468548 10;
BA_ "GenMsgSendType" BO_ 2600468548 7;
BA_ "NmhMessage" BO_ 2600468548 1;
BA_ "MsgType" BO_ 2600468548 2;
BA_ "GenMsgCycleTime" BO_ 2600468678 200;
BA_ "GenMsgCycleTimeFast" BO_ 2600468678 10;
BA_ "GenMsgSendType" BO_ 2600468678 7;
BA_ "NmhMessage" BO_ 2600468678 1;
BA_ "MsgType" BO_ 2600468678 2;
BA_ "GenMsgCycleTime" BO_ 2600468481 200;
BA_ "GenMsgCycleTimeFast" BO_ 2600468481 10;
BA_ "GenMsgSendType" BO_ 2600468481 7;
BA_ "NmhMessage" BO_ 2600468481 1;
BA_ "MsgType" BO_ 2600468481 2;
BA_ "GenMsgCycleTime" BO_ 2600468483 200;
BA_ "GenMsgCycleTimeFast" BO_ 2600468483 10;
BA_ "GenMsgSendType" BO_ 2600468483 7;
BA_ "NmhMessage" BO_ 2600468483 1;
BA_ "MsgType" BO_ 2600468483 2;
BA_ "GenMsgCycleTime" BO_ 2600468553 200;
BA_ "GenMsgCycleTimeFast" BO_ 2600468553 10;
BA_ "GenMsgSendType" BO_ 2600468553 7;
BA_ "NmhMessage" BO_ 2600468553 1;
BA_ "MsgType" BO_ 2600468553 2;
BA_ "GenMsgCycleTime" BO_ 2600468546 200;
BA_ "GenMsgCycleTimeFast" BO_ 2600468546 10;
BA_ "GenMsgSendType" BO_ 2600468546 7;
BA_ "NmhMessage" BO_ 2600468546 1;
BA_ "MsgType" BO_ 2600468546 2;
BA_ "GenMsgCycleTime" BO_ 1635 100;
BA_ "GenMsgILSupport" BO_ 1635 1;
BA_ "GenMsgPDUConstants" BO_ 1635 "0x7d,0xba,0x97,0x94,0x5a,0x4a,0xeb,0xd4,0x6c,0x28,0x54,0x81,0xc7,0x1c,0x25,0x2a";
BA_ "GenMsgSendType" BO_ 1635 0;
BA_ "GenMsgStartDelayTime" BO_ 1635 10;
BA_ "GenMsgCycleTime" BO_ 869 50;
BA_ "GenMsgILSupport" BO_ 869 1;
BA_ "GenMsgPDUConstants" BO_ 869 "0xe3,0x0a,0x29,0xd3,0x96,0xaa,0xeb,0x89,0xe6,0x5f,0x14,0xc4,0xe9,0x27,0x0b,0x2d";
BA_ "GenMsgSendType" BO_ 869 0;
BA_ "GenMsgStartDelayTime" BO_ 869 5;
BA_ "GenMsgCycleTime" BO_ 2527679508 100;
BA_ "GenMsgDelayTime" BO_ 2527679508 80;
BA_ "GenMsgILSupport" BO_ 2527679508 1;
BA_ "GenMsgPDUConstants" BO_ 2527679508 "0xa3,0xed,0x65,0xcf,0xc5,0x26,0x54,0x1a,0x99,0x3c,0x01,0x84,0xf4,0x46,0x9c,0x28";
BA_ "GenMsgSendType" BO_ 2527679508 0;
BA_ "GenMsgStartDelayTime" BO_ 2527679508 10;
BA_ "GenMsgCycleTime" BO_ 2527679509 500;
BA_ "GenMsgDelayTime" BO_ 2527679509 50;
BA_ "GenMsgILSupport" BO_ 2527679509 1;
BA_ "GenMsgPDUConstants" BO_ 2527679509 "0x01,0x40,0xf0,0x21,0x22,0x92,0x44,0x1a,0x85,0xeb,0x7b,0xcd,0x7c,0x59,0xc5,0xc2";
BA_ "GenMsgSendType" BO_ 2527679509 0;
BA_ "GenMsgStartDelayTime" BO_ 2527679509 50;
BA_ "GenMsgCycleTime" BO_ 527 50;
BA_ "GenMsgILSupport" BO_ 527 1;
BA_ "GenMsgPDUConstants" BO_ 527 "0xd4,0x22,0xad,0x3f,0x25,0xaa,0x62,0x5b,0xdc,0x73,0xed,0xc3,0x9a,0x14,0x2f,0x3e";
BA_ "GenMsgSendType" BO_ 527 0;
BA_ "GenMsgStartDelayTime" BO_ 527 50;
BA_ "GenMsgCycleTime" BO_ 913 80;
BA_ "GenMsgILSupport" BO_ 913 1;
BA_ "GenMsgSendType" BO_ 913 0;
BA_ "GenMsgCycleTime" BO_ 2589283478 320;
BA_ "GenMsgILSupport" BO_ 2589283478 1;
BA_ "GenMsgSendType" BO_ 2589283478 0;
BA_ "DiagRequest" BO_ 2549875343 1;
BA_ "MsgType" BO_ 2549875343 4;
BA_ "DiagResponse" BO_ 2550006415 1;
BA_ "MsgType" BO_ 2550006415 4;
BA_ "DiagRequest" BO_ 2549875374 1;
BA_ "MsgType" BO_ 2549875374 4;
BA_ "DiagResponse" BO_ 2550006446 1;
BA_ "MsgType" BO_ 2550006446 4;
BA_ "DiagRequest" BO_ 2549875356 1;
BA_ "MsgType" BO_ 2549875356 4;
BA_ "DiagResponse" BO_ 2550006428 1;
BA_ "MsgType" BO_ 2550006428 4;
BA_ "DiagRequest" BO_ 2549875399 1;
BA_ "MsgType" BO_ 2549875399 4;
BA_ "DiagResponse" BO_ 2550006471 1;
BA_ "MsgType" BO_ 2550006471 4;
BA_ "DiagRequest" BO_ 2549875407 1;
BA_ "MsgType" BO_ 2549875407 4;
BA_ "DiagResponse" BO_ 2550006479 1;
BA_ "MsgType" BO_ 2550006479 4;
BA_ "DiagRequest" BO_ 2549875383 1;
BA_ "MsgType" BO_ 2549875383 4;
BA_ "DiagResponse" BO_ 2550006455 1;
BA_ "MsgType" BO_ 2550006455 4;
BA_ "DiagRequest" BO_ 2549875265 1;
BA_ "MsgType" BO_ 2549875265 4;
BA_ "DiagResponse" BO_ 2550006337 1;
BA_ "MsgType" BO_ 2550006337 4;
BA_ "DiagRequest" BO_ 2549875381 1;
BA_ "MsgType" BO_ 2549875381 4;
BA_ "DiagResponse" BO_ 2550006453 1;
BA_ "MsgType" BO_ 2550006453 4;
BA_ "DiagState" BO_ 2549940736 1;
BA_ "MsgType" BO_ 2549940736 4;
BA_ "DiagRequest" BO_ 2549875323 1;
BA_ "MsgType" BO_ 2549875323 4;
BA_ "DiagResponse" BO_ 2550006395 1;
BA_ "MsgType" BO_ 2550006395 4;
BA_ "DiagRequest" BO_ 2549875398 1;
BA_ "MsgType" BO_ 2549875398 4;
BA_ "DiagResponse" BO_ 2550006470 1;
BA_ "MsgType" BO_ 2550006470 4;
BA_ "DiagRequest" BO_ 2549875268 1;
BA_ "MsgType" BO_ 2549875268 4;
BA_ "DiagResponse" BO_ 2550006340 1;
BA_ "MsgType" BO_ 2550006340 4;
BA_ "DiagRequest" BO_ 2549903568 1;
BA_ "MsgType" BO_ 2549903568 4;
BA_ "DiagResponse" BO_ 2550034640 1;
BA_ "MsgType" BO_ 2550034640 4;
BA_ "DiagRequest" BO_ 2549903569 1;
BA_ "MsgType" BO_ 2549903569 4;
BA_ "DiagResponse" BO_ 2550034641 1;
BA_ "MsgType" BO_ 2550034641 4;
BA_ "DiagRequest" BO_ 2549903570 1;
BA_ "MsgType" BO_ 2549903570 4;
BA_ "DiagResponse" BO_ 2550034642 1;
BA_ "MsgType" BO_ 2550034642 4;
BA_ "DiagRequest" BO_ 2549903571 1;
BA_ "MsgType" BO_ 2549903571 4;
BA_ "DiagResponse" BO_ 2550034643 1;
BA_ "MsgType" BO_ 2550034643 4;
BA_ "DiagRequest" BO_ 2549903572 1;
BA_ "MsgType" BO_ 2549903572 4;
